VERSION ""

NS_ :

BS_:

BU_: EBOOST_HS CGM_HS BSM_HS HCP_B_HS AVM_HS PFAF_HS LVMPC_HS DCDC_HS TRCM_HS AMP_HS VICM2_HS FICM_HS ARS_HS MCP_B_HS MCP_A_HS ICCM_OBD_HS SAS_HS ACCM_HS VLBS_HS EBCM_OBD_HS HCP_T_HS EDI_HS HPCC_HS VITM_OBD_HS VICM_HS HCP_HS APPS_HS ICCM_HS EOCM_F_HS GPCM_HS VCM_HS HMIM_HS VES_HS Dummy_HS MCP_C_HS ONSTAR_HS EPS_HS TestTool_HS MCP_HS BCP_HS ALC_HS AHL_AFL_HS SADS_HS EPB_HS FCM_HS TCCM_HS RDCM_HS PTO_HS EBCM_HS ACC_HS BCM_HS TCM_HS ECM_HS

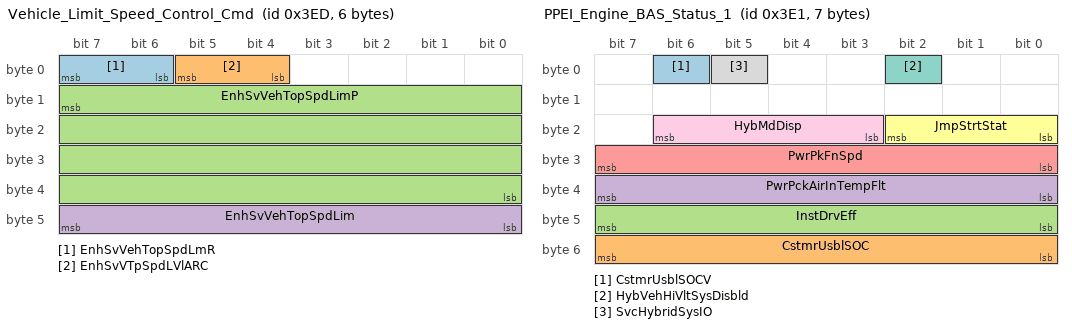
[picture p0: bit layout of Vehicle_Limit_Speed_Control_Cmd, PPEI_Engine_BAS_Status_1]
BO_ 1005 Vehicle_Limit_Speed_Control_Cmd: 6 ONSTAR_HS
 SG_ EnhSvVehTopSpdLmR : 7|2@0+ (1,0) [0|3] ""  ECM_HS
 SG_ EnhSvVTpSpdLVlARC : 5|2@0+ (1,0) [0|3] ""  ECM_HS
 SG_ EnhSvVehTopSpdLimP : 15|32@0+ (1,0) [0|4294967295] ""  ECM_HS
 SG_ EnhSvVehTopSpdLim : 47|8@0+ (2,0) [0|510] "km / h"  ECM_HS

BO_ 688 Starter_Generator_Status_3: 5 BCP_HS
 SG_ StrtrGenSpdV : 39|1@0+ (1,0) [0|1] ""  ECM_HS,EBCM_OBD_HS,EBCM_HS
 SG_ StrtrGenSpd : 21|14@0+ (1,0) [0|16383] "rpm"  ECM_HS,EBCM_OBD_HS,EBCM_HS

BO_ 993 PPEI_Engine_BAS_Status_1: 7 BCP_HS
 SG_ CstmrUsblSOCV : 6|1@0+ (1,0) [0|1] ""  CGM_HS,BCM_HS
 SG_ CstmrUsblSOC : 55|8@0+ (0.39216,0) [0|100.0008] "%"  CGM_HS,BCM_HS
 SG_ InstDrvEff : 47|8@0- (0.78125,0) [-100|99.21875] "%"  CGM_HS,BCM_HS
 SG_ PwrPckAirInTempFlt : 39|8@0+ (1,-40) [-40|215] "deg C"  CGM_HS,BCM_HS
 SG_ PwrPkFnSpd : 31|8@0+ (0.392157,0) [0|100.000035] "%"  CGM_HS,BCM_HS
 SG_ JmpStrtStat : 18|3@0+ (1,0) [0|7] ""  CGM_HS,BCM_HS
 SG_ HybVehHiVltSysDisbld : 2|1@0+ (1,0) [0|1] ""  CGM_HS,ONSTAR_HS
 SG_ SvcHybridSysIO : 5|1@0+ (1,0) [0|1] ""  CGM_HS,BCM_HS
 SG_ HybMdDisp : 22|4@0+ (1,0) [0|15] ""  CGM_HS,BCM_HS

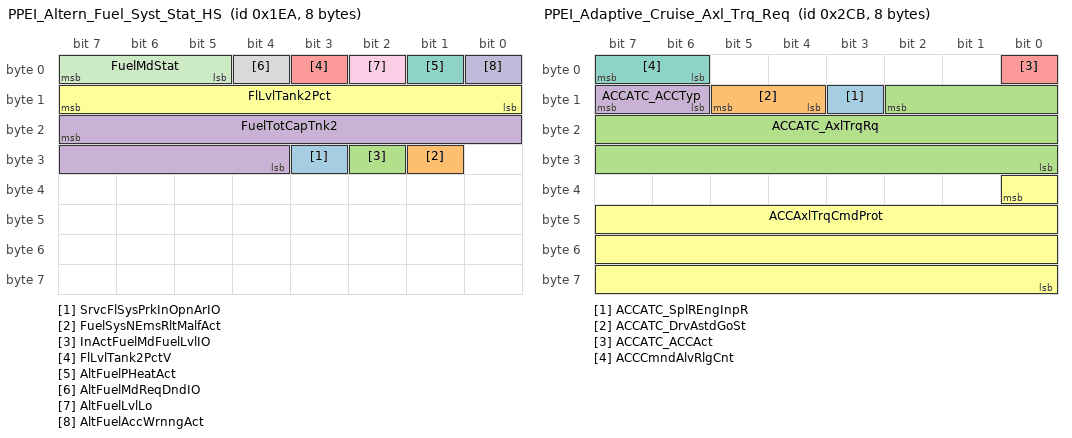
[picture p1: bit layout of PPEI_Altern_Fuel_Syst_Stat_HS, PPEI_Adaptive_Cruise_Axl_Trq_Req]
BO_ 490 PPEI_Altern_Fuel_Syst_Stat_HS: 8 ECM_HS
 SG_ SrvcFlSysPrkInOpnArIO : 27|1@0+ (1,0) [0|1] ""  BCM_HS
 SG_ FuelSysNEmsRltMalfAct : 25|1@0+ (1,0) [0|1] ""  BCM_HS
 SG_ InActFuelMdFuelLvlIO : 26|1@0+ (1,0) [0|1] ""  BCM_HS
 SG_ FuelTotCapTnk2 : 23|12@0+ (0.125,0) [0|511.875] "liters"  BCM_HS
 SG_ FlLvlTank2PctV : 3|1@0+ (1,0) [0|1] ""  BCM_HS
 SG_ FlLvlTank2Pct : 15|8@0+ (0.392157,0) [0|100.000035] "%"  BCM_HS
 SG_ AltFuelPHeatAct : 1|1@0+ (1,0) [0|1] ""  ECM_HS,BCM_HS
 SG_ AltFuelMdReqDndIO : 4|1@0+ (1,0) [0|1] ""  BCM_HS
 SG_ AltFuelLvlLo : 2|1@0+ (1,0) [0|1] ""  BCM_HS,ECM_HS
 SG_ AltFuelAccWrnngAct : 0|1@0+ (1,0) [0|1] ""  BCM_HS
 SG_ FuelMdStat : 7|3@0+ (1,0) [0|7] ""  BCM_HS,ECM_HS

BO_ 431 PTEI_Trans_General_Status_2: 8 TCM_HS
 SG_ TrnsInpCltchStatV : 39|1@0+ (1,0) [0|1] ""  ECM_HS
 SG_ TransCrnkPermsnStatV : 23|1@0+ (1,0) [0|1] ""  ECM_HS
 SG_ TransVehTopSpdLim : 63|8@0+ (2,0) [0|510] "km / h"  ECM_HS
 SG_ TransMinVoltReq : 55|8@0+ (0.07843,0) [0|19.99965] "volts"  ECM_HS
 SG_ TDslPrtFltrIdlRgtnMdAtv : 6|1@0+ (1,0) [0|1] ""  ECM_HS
 SG_ DrvlneTrqStabStat : 38|3@0+ (1,0) [0|7] ""  ECM_HS
 SG_ TrnsTrqCnvCltCmdMdF : 19|1@0+ (1,0) [0|1] ""  ECM_HS
 SG_ AutoTransGrSftDirectFl : 16|1@0+ (1,0) [0|1] ""  ECM_HS
 SG_ AutoTransGrSftDirect : 18|2@0+ (1,0) [0|3] ""  ECM_HS
 SG_ TrnsTrqCnvCltCmndMd : 22|3@0+ (1,0) [0|7] ""  ECM_HS
 SG_ TrnsTrqCnvCltDsrSlp : 35|12@0- (1,0) [-2048|2047] "rpm"  ECM_HS
 SG_ TrnsStWntrMdOvrd : 25|2@0+ (1,0) [0|3] ""  ECM_HS
 SG_ TrnsStTwHaulMdOvrd : 27|2@0+ (1,0) [0|3] ""  ECM_HS
 SG_ TrnsStSprtMdOvrd : 29|2@0+ (1,0) [0|3] ""  ECM_HS
 SG_ TrnsStEconMdOvrd : 31|2@0+ (1,0) [0|3] ""  ECM_HS
 SG_ TrnsInpCltchStat : 2|3@0+ (1,0) [0|7] ""  ECM_HS
 SG_ TrnsAntcptdCrpTrqRRnV : 7|1@0+ (1,0) [0|1] ""  ECM_HS
 SG_ TrnsAntcptdCrpTrqRRn : 15|8@0+ (0.5,0) [0|127.5] "Nm"  ECM_HS
 SG_ TrnCltAdpAtv : 3|1@0+ (1,0) [0|1] ""  ECM_HS
 SG_ TransCrnkPermsnStat : 5|1@0+ (1,0) [0|1] ""  ECM_HS
 SG_ WrmUpShftPtrn : 4|1@0+ (1,0) [0|1] ""  ECM_HS

BO_ 715 PPEI_Adaptive_Cruise_Axl_Trq_Req: 8 ACC_HS
 SG_ ACCATC_SplREngInpR : 11|1@0+ (1,0) [0|1] ""  ECM_HS
 SG_ ACCATC_DrvAstdGoSt : 13|2@0+ (1,0) [0|3] ""  ECM_HS
 SG_ ACCATC_AxlTrqRq : 10|19@0+ (0.125,-22534) [-22534|43001.875] "Nm"  ECM_HS
 SG_ ACCATC_ACCTyp : 15|2@0+ (1,0) [0|3] ""  ECM_HS
 SG_ ACCATC_ACCAct : 0|1@0+ (1,0) [0|1] ""  ECM_HS
 SG_ ACCAxlTrqCmdProt : 32|25@0+ (1,0) [0|33554431] ""  ECM_HS
 SG_ ACCCmndAlvRlgCnt : 7|2@0+ (1,0) [0|3] ""  ECM_HS

BO_ 1267 PPEI_Powertrain_Config_Data_2: 1 ECM_HS
 SG_ VehMassNom : 7|8@0+ (20,500) [500|5600] "kg"  CGM_HS,EOCM_F_HS,ACC_HS,FCM_HS

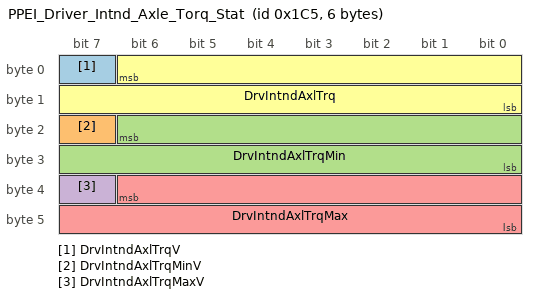
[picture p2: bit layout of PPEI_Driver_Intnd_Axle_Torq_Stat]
BO_ 453 PPEI_Driver_Intnd_Axle_Torq_Stat: 6 ECM_HS
 SG_ DrvIntndAxlTrqV : 7|1@0+ (1,0) [0|1] ""  CGM_HS,FCM_HS,ICCM_OBD_HS,ICCM_HS,EBCM_OBD_HS,EBCM_HS,BSM_HS,VICM_HS,EOCM_F_HS,ACC_HS
 SG_ DrvIntndAxlTrqMinV : 23|1@0+ (1,0) [0|1] ""  CGM_HS,FCM_HS,EOCM_F_HS,ACC_HS
 SG_ DrvIntndAxlTrqMin : 22|15@0+ (2,-22534) [-22534|43000] "Nm"  CGM_HS,FCM_HS,HCP_B_HS,EOCM_F_HS,ACC_HS
 SG_ DrvIntndAxlTrqMaxV : 39|1@0+ (1,0) [0|1] ""  CGM_HS,FCM_HS,EOCM_F_HS,ACC_HS
 SG_ DrvIntndAxlTrqMax : 38|15@0+ (2,-22534) [-22534|43000] "Nm"  CGM_HS,FCM_HS,EOCM_F_HS,ACC_HS
 SG_ DrvIntndAxlTrq : 6|15@0+ (2,-22534) [-22534|43000] "Nm"  CGM_HS,FCM_HS,ICCM_OBD_HS,ICCM_HS,EBCM_OBD_HS,EBCM_HS,BSM_HS,VICM_HS,EOCM_F_HS,ACC_HS

BO_ 452 PPEI_Torque_Request_Status: 8 ECM_HS
 SG_ FSpRgACCSwADdPVal : 50|2@0+ (1,0) [0|3] ""  CGM_HS,EBCM_OBD_HS,EBCM_HS
 SG_ FSpRgACCSwADdARC : 6|2@0+ (1,0) [0|3] ""  CGM_HS,EBCM_OBD_HS,EBCM_HS
 SG_ FSpRgACCSwADd : 7|1@0+ (1,0) [0|1] ""  CGM_HS,EBCM_OBD_HS,EBCM_HS,ACC_HS
 SG_ AutBrkAccActPsStRC : 34|2@0+ (1,0) [0|3] ""  CGM_HS,FCM_HS,EPB_HS,EOCM_F_HS,ACC_HS,EBCM_OBD_HS,EBCM_HS
 SG_ AutBrkAccActPsStPVal : 48|9@0+ (1,0) [0|511] ""  CGM_HS,FCM_HS,EPB_HS,EOCM_F_HS,ACC_HS,EBCM_OBD_HS,EBCM_HS
 SG_ ABAAPS_AccPos : 47|8@0+ (0.392157,0) [0|100.000035] "%"  CGM_HS,FCM_HS,EPB_HS,EBCM_OBD_HS,EBCM_HS,ACC_HS,EOCM_F_HS
 SG_ ABAAPS_AccPosV : 32|1@0+ (1,0) [0|1] ""  CGM_HS,FCM_HS,EPB_HS,EBCM_OBD_HS,EBCM_HS,ACC_HS,EOCM_F_HS
 SG_ ACCATCS_LmtgStat : 12|2@0+ (1,0) [0|3] ""  HCP_B_HS,CGM_HS,EOCM_F_HS,ACC_HS
 SG_ ACCATCS_RqStat : 15|3@0+ (1,0) [0|7] ""  HCP_B_HS,CGM_HS,EOCM_F_HS,ACC_HS
 SG_ RdLdNomAxlTrq : 10|19@0+ (0.125,-22534) [-22534|43001.875] "Nm"  CGM_HS,EOCM_F_HS,ACC_HS
 SG_ AccPdlOvrrdAtvProtVal : 1|2@0+ (1,0) [0|3] ""  CGM_HS,FCM_HS,EOCM_F_HS,EBCM_OBD_HS,EBCM_HS,ACC_HS,PTO_HS
 SG_ AccPdlOvrrdAtvARC : 3|2@0+ (1,0) [0|3] ""  CGM_HS,FCM_HS,EOCM_F_HS,EBCM_OBD_HS,EBCM_HS,ACC_HS,PTO_HS
 SG_ AccPdlOvrrdAtv : 4|1@0+ (1,0) [0|1] ""  CGM_HS,FCM_HS,BCM_HS,EOCM_F_HS,EBCM_OBD_HS,EBCM_HS,ACC_HS,PTO_HS
 SG_ CPSATCS_ReqStatus : 37|3@0+ (1,0) [0|7] ""  CGM_HS,FCM_HS,ACC_HS,EOCM_F_HS
 SG_ CPSATCS_LmtngStatus : 39|2@0+ (1,0) [0|3] ""  CGM_HS,FCM_HS,ACC_HS,EOCM_F_HS
 SG_ RVBATCS_ReqStat : 53|3@0+ (1,0) [0|7] ""  CGM_HS,EOCM_F_HS
 SG_ RVBATCS_LmtngStat : 55|2@0+ (1,0) [0|3] ""  CGM_HS,EOCM_F_HS

BO_ 1905 DTC_Triggered_771: 7 EBOOST_HS
 SG_ DTCI_DTCFaultType_771 : 55|8@0+ (1,0) [0|255] ""  HMIM_HS,ONSTAR_HS
 SG_ DTCI_CodeSupported_771 : 40|1@0+ (1,0) [0|1] ""  HMIM_HS,ONSTAR_HS
 SG_ DTCI_CurrentStatus_771 : 41|1@0+ (1,0) [0|1] ""  HMIM_HS,ONSTAR_HS
 SG_ DTCI_TstNPsdCdClrdSt_771 : 42|1@0+ (1,0) [0|1] ""  HMIM_HS,ONSTAR_HS
 SG_ DTCI_TstFldCdClrdStat_771 : 43|1@0+ (1,0) [0|1] ""  HMIM_HS,ONSTAR_HS
 SG_ DTCI_HistStat_771 : 44|1@0+ (1,0) [0|1] ""  HMIM_HS,ONSTAR_HS
 SG_ DTCI_TstNPsdPwrUpSt_771 : 45|1@0+ (1,0) [0|1] ""  HMIM_HS,ONSTAR_HS
 SG_ DTCI_TstFldPwrUpSt_771 : 46|1@0+ (1,0) [0|1] ""  HMIM_HS,ONSTAR_HS
 SG_ DTCI_WrnIndRqdSt_771 : 47|1@0+ (1,0) [0|1] ""  HMIM_HS,ONSTAR_HS
 SG_ DTCI_DTCFailType_771 : 39|8@0+ (1,0) [0|255] ""  HMIM_HS,ONSTAR_HS
 SG_ DTCI_DTCNumber_771 : 23|16@0+ (1,0) [0|65535] ""  HMIM_HS,ONSTAR_HS
 SG_ DTCI_DTCSource_771 : 15|8@0+ (1,0) [0|255] ""  HMIM_HS,ONSTAR_HS
 SG_ DTCI_DTCTriggered_771 : 0|1@0+ (1,0) [0|1] ""  HMIM_HS,ONSTAR_HS
 SG_ DTCIUnused7_771 : 1|1@0+ (1,0) [0|1] ""  HMIM_HS,ONSTAR_HS
 SG_ DTCIUnused6_771 : 2|1@0+ (1,0) [0|1] ""  HMIM_HS,ONSTAR_HS
 SG_ DTCIUnused5_771 : 3|1@0+ (1,0) [0|1] ""  HMIM_HS,ONSTAR_HS
 SG_ DTCIUnused4_771 : 4|1@0+ (1,0) [0|1] ""  HMIM_HS,ONSTAR_HS
 SG_ DTCIUnused3_771 : 5|1@0+ (1,0) [0|1] ""  HMIM_HS,ONSTAR_HS
 SG_ DTCIUnused2_771 : 6|1@0+ (1,0) [0|1] ""  HMIM_HS,ONSTAR_HS
 SG_ DTCIUnused1_771 : 7|1@0+ (1,0) [0|1] ""  HMIM_HS,ONSTAR_HS

BO_ 1935 DTC_Triggered_78F: 7 Dummy_HS
 SG_ DTCI_DTCSource_78F : 15|8@0+ (1,0) [0|255] ""  HMIM_HS,ONSTAR_HS
 SG_ DTCI_DTCTriggered_78F : 0|1@0+ (1,0) [0|1] ""  HMIM_HS,ONSTAR_HS
 SG_ DTCIUnused1_78F : 7|1@0+ (1,0) [0|1] ""  HMIM_HS,ONSTAR_HS
 SG_ DTCIUnused2_78F : 6|1@0+ (1,0) [0|1] ""  HMIM_HS,ONSTAR_HS
 SG_ DTCIUnused3_78F : 5|1@0+ (1,0) [0|1] ""  HMIM_HS,ONSTAR_HS
 SG_ DTCIUnused4_78F : 4|1@0+ (1,0) [0|1] ""  HMIM_HS,ONSTAR_HS
 SG_ DTCIUnused5_78F : 3|1@0+ (1,0) [0|1] ""  HMIM_HS,ONSTAR_HS
 SG_ DTCIUnused6_78F : 2|1@0+ (1,0) [0|1] ""  HMIM_HS,ONSTAR_HS
 SG_ DTCIUnused7_78F : 1|1@0+ (1,0) [0|1] ""  HMIM_HS,ONSTAR_HS
 SG_ DTCI_CodeSupported_78F : 40|1@0+ (1,0) [0|1] ""  HMIM_HS,ONSTAR_HS
 SG_ DTCI_CurrentStatus_78F : 41|1@0+ (1,0) [0|1] ""  HMIM_HS,ONSTAR_HS
 SG_ DTCI_DTCFaultType_78F : 55|8@0+ (1,0) [0|255] ""  HMIM_HS,ONSTAR_HS
 SG_ DTCI_TstFldCdClrdStat_78F : 43|1@0+ (1,0) [0|1] ""  HMIM_HS,ONSTAR_HS
 SG_ DTCI_TstNPsdCdClrdSt_78F : 42|1@0+ (1,0) [0|1] ""  HMIM_HS,ONSTAR_HS
 SG_ DTCI_HistStat_78F : 44|1@0+ (1,0) [0|1] ""  HMIM_HS,ONSTAR_HS
 SG_ DTCI_TstNPsdPwrUpSt_78F : 45|1@0+ (1,0) [0|1] ""  HMIM_HS,ONSTAR_HS
 SG_ DTCI_TstFldPwrUpSt_78F : 46|1@0+ (1,0) [0|1] ""  HMIM_HS,ONSTAR_HS
 SG_ DTCI_WrnIndRqdSt_78F : 47|1@0+ (1,0) [0|1] ""  HMIM_HS,ONSTAR_HS
 SG_ DTCI_DTCFailType_78F : 39|8@0+ (1,0) [0|255] ""  HMIM_HS,ONSTAR_HS
 SG_ DTCI_DTCNumber_78F : 23|16@0+ (1,0) [0|65535] ""  HMIM_HS,ONSTAR_HS

BO_ 1934 DTC_Triggered_78E: 7 Dummy_HS
 SG_ DTCI_CodeSupported_78E : 40|1@0+ (1,0) [0|1] ""  HMIM_HS,ONSTAR_HS
 SG_ DTCI_CurrentStatus_78E : 41|1@0+ (1,0) [0|1] ""  HMIM_HS,ONSTAR_HS
 SG_ DTCI_DTCFailType_78E : 39|8@0+ (1,0) [0|255] ""  HMIM_HS,ONSTAR_HS
 SG_ DTCI_DTCFaultType_78E : 55|8@0+ (1,0) [0|255] ""  HMIM_HS,ONSTAR_HS
 SG_ DTCI_DTCNumber_78E : 23|16@0+ (1,0) [0|65535] ""  HMIM_HS,ONSTAR_HS
 SG_ DTCI_DTCSource_78E : 15|8@0+ (1,0) [0|255] ""  HMIM_HS,ONSTAR_HS
 SG_ DTCI_DTCTriggered_78E : 0|1@0+ (1,0) [0|1] ""  HMIM_HS,ONSTAR_HS
 SG_ DTCI_HistStat_78E : 44|1@0+ (1,0) [0|1] ""  HMIM_HS,ONSTAR_HS
 SG_ DTCI_TstFldCdClrdStat_78E : 43|1@0+ (1,0) [0|1] ""  HMIM_HS,ONSTAR_HS
 SG_ DTCI_TstFldPwrUpSt_78E : 46|1@0+ (1,0) [0|1] ""  HMIM_HS,ONSTAR_HS
 SG_ DTCI_TstNPsdCdClrdSt_78E : 42|1@0+ (1,0) [0|1] ""  HMIM_HS,ONSTAR_HS
 SG_ DTCI_TstNPsdPwrUpSt_78E : 45|1@0+ (1,0) [0|1] ""  HMIM_HS,ONSTAR_HS
 SG_ DTCIUnused1_78E : 7|1@0+ (1,0) [0|1] ""  HMIM_HS,ONSTAR_HS
 SG_ DTCIUnused2_78E : 6|1@0+ (1,0) [0|1] ""  HMIM_HS,ONSTAR_HS
 SG_ DTCIUnused3_78E : 5|1@0+ (1,0) [0|1] ""  HMIM_HS,ONSTAR_HS
 SG_ DTCIUnused4_78E : 4|1@0+ (1,0) [0|1] ""  HMIM_HS,ONSTAR_HS
 SG_ DTCIUnused5_78E : 3|1@0+ (1,0) [0|1] ""  HMIM_HS,ONSTAR_HS
 SG_ DTCIUnused6_78E : 2|1@0+ (1,0) [0|1] ""  HMIM_HS,ONSTAR_HS
 SG_ DTCIUnused7_78E : 1|1@0+ (1,0) [0|1] ""  HMIM_HS,ONSTAR_HS
 SG_ DTCI_WrnIndRqdSt_78E : 47|1@0+ (1,0) [0|1] ""  HMIM_HS,ONSTAR_HS

BO_ 1933 DTC_Triggered_78D: 7 Dummy_HS
 SG_ DTCI_CodeSupported_78D : 40|1@0+ (1,0) [0|1] ""  HMIM_HS,ONSTAR_HS
 SG_ DTCI_CurrentStatus_78D : 41|1@0+ (1,0) [0|1] ""  HMIM_HS,ONSTAR_HS
 SG_ DTCI_DTCFailType_78D : 39|8@0+ (1,0) [0|255] ""  HMIM_HS,ONSTAR_HS
 SG_ DTCI_DTCFaultType_78D : 55|8@0+ (1,0) [0|255] ""  HMIM_HS,ONSTAR_HS
 SG_ DTCI_DTCNumber_78D : 23|16@0+ (1,0) [0|65535] ""  HMIM_HS,ONSTAR_HS
 SG_ DTCI_DTCSource_78D : 15|8@0+ (1,0) [0|255] ""  HMIM_HS,ONSTAR_HS
 SG_ DTCI_DTCTriggered_78D : 0|1@0+ (1,0) [0|1] ""  HMIM_HS,ONSTAR_HS
 SG_ DTCI_HistStat_78D : 44|1@0+ (1,0) [0|1] ""  HMIM_HS,ONSTAR_HS
 SG_ DTCI_TstFldCdClrdStat_78D : 43|1@0+ (1,0) [0|1] ""  HMIM_HS,ONSTAR_HS
 SG_ DTCI_TstFldPwrUpSt_78D : 46|1@0+ (1,0) [0|1] ""  HMIM_HS,ONSTAR_HS
 SG_ DTCI_TstNPsdCdClrdSt_78D : 42|1@0+ (1,0) [0|1] ""  HMIM_HS,ONSTAR_HS
 SG_ DTCI_TstNPsdPwrUpSt_78D : 45|1@0+ (1,0) [0|1] ""  HMIM_HS,ONSTAR_HS
 SG_ DTCIUnused1_78D : 7|1@0+ (1,0) [0|1] ""  HMIM_HS,ONSTAR_HS
 SG_ DTCIUnused2_78D : 6|1@0+ (1,0) [0|1] ""  HMIM_HS,ONSTAR_HS
 SG_ DTCIUnused3_78D : 5|1@0+ (1,0) [0|1] ""  HMIM_HS,ONSTAR_HS
 SG_ DTCIUnused4_78D : 4|1@0+ (1,0) [0|1] ""  HMIM_HS,ONSTAR_HS
 SG_ DTCIUnused5_78D : 3|1@0+ (1,0) [0|1] ""  HMIM_HS,ONSTAR_HS
 SG_ DTCIUnused6_78D : 2|1@0+ (1,0) [0|1] ""  HMIM_HS,ONSTAR_HS
 SG_ DTCIUnused7_78D : 1|1@0+ (1,0) [0|1] ""  HMIM_HS,ONSTAR_HS
 SG_ DTCI_WrnIndRqdSt_78D : 47|1@0+ (1,0) [0|1] ""  HMIM_HS,ONSTAR_HS

BO_ 1932 DTC_Triggered_78C: 7 Dummy_HS
 SG_ DTCI_CodeSupported_78C : 40|1@0+ (1,0) [0|1] ""  HMIM_HS,ONSTAR_HS
 SG_ DTCI_CurrentStatus_78C : 41|1@0+ (1,0) [0|1] ""  HMIM_HS,ONSTAR_HS
 SG_ DTCI_DTCFailType_78C : 39|8@0+ (1,0) [0|255] ""  HMIM_HS,ONSTAR_HS
 SG_ DTCI_DTCFaultType_78C : 55|8@0+ (1,0) [0|255] ""  HMIM_HS,ONSTAR_HS
 SG_ DTCI_DTCNumber_78C : 23|16@0+ (1,0) [0|65535] ""  HMIM_HS,ONSTAR_HS
 SG_ DTCI_DTCSource_78C : 15|8@0+ (1,0) [0|255] ""  HMIM_HS,ONSTAR_HS
 SG_ DTCI_DTCTriggered_78C : 0|1@0+ (1,0) [0|1] ""  HMIM_HS,ONSTAR_HS
 SG_ DTCI_HistStat_78C : 44|1@0+ (1,0) [0|1] ""  HMIM_HS,ONSTAR_HS
 SG_ DTCI_TstFldCdClrdStat_78C : 43|1@0+ (1,0) [0|1] ""  HMIM_HS,ONSTAR_HS
 SG_ DTCI_TstFldPwrUpSt_78C : 45|1@0+ (1,0) [0|1] ""  HMIM_HS,ONSTAR_HS
 SG_ DTCI_TstNPsdCdClrdSt_78C : 42|1@0+ (1,0) [0|1] ""  HMIM_HS,ONSTAR_HS
 SG_ DTCI_TstNPsdPwrUpSt_78C : 46|1@0+ (1,0) [0|1] ""  HMIM_HS,ONSTAR_HS
 SG_ DTCIUnused1_78C : 7|1@0+ (1,0) [0|1] ""  HMIM_HS,ONSTAR_HS
 SG_ DTCIUnused2_78C : 6|1@0+ (1,0) [0|1] ""  HMIM_HS,ONSTAR_HS
 SG_ DTCIUnused3_78C : 5|1@0+ (1,0) [0|1] ""  HMIM_HS,ONSTAR_HS
 SG_ DTCIUnused4_78C : 4|1@0+ (1,0) [0|1] ""  HMIM_HS,ONSTAR_HS
 SG_ DTCIUnused5_78C : 3|1@0+ (1,0) [0|1] ""  HMIM_HS,ONSTAR_HS
 SG_ DTCIUnused6_78C : 2|1@0+ (1,0) [0|1] ""  HMIM_HS,ONSTAR_HS
 SG_ DTCIUnused7_78C : 1|1@0+ (1,0) [0|1] ""  HMIM_HS,ONSTAR_HS
 SG_ DTCI_WrnIndRqdSt_78C : 47|1@0+ (1,0) [0|1] ""  HMIM_HS,ONSTAR_HS

BO_ 1931 DTC_Triggered_78B: 7 Dummy_HS
 SG_ DTCI_CodeSupported_78B : 40|1@0+ (1,0) [0|1] ""  HMIM_HS,ONSTAR_HS
 SG_ DTCI_CurrentStatus_78B : 41|1@0+ (1,0) [0|1] ""  HMIM_HS,ONSTAR_HS
 SG_ DTCI_DTCFailType_78B : 39|8@0+ (1,0) [0|255] ""  HMIM_HS,ONSTAR_HS
 SG_ DTCI_DTCFaultType_78B : 55|8@0+ (1,0) [0|255] ""  HMIM_HS,ONSTAR_HS
 SG_ DTCI_DTCNumber_78B : 23|16@0+ (1,0) [0|65535] ""  HMIM_HS,ONSTAR_HS
 SG_ DTCI_DTCSource_78B : 15|8@0+ (1,0) [0|255] ""  HMIM_HS,ONSTAR_HS
 SG_ DTCI_DTCTriggered_78B : 0|1@0+ (1,0) [0|1] ""  HMIM_HS,ONSTAR_HS
 SG_ DTCI_HistStat_78B : 44|1@0+ (1,0) [0|1] ""  HMIM_HS,ONSTAR_HS
 SG_ DTCI_TstFldCdClrdStat_78B : 43|1@0+ (1,0) [0|1] ""  HMIM_HS,ONSTAR_HS
 SG_ DTCI_TstFldPwrUpSt_78B : 46|1@0+ (1,0) [0|1] ""  HMIM_HS,ONSTAR_HS
 SG_ DTCI_TstNPsdCdClrdSt_78B : 42|1@0+ (1,0) [0|1] ""  HMIM_HS,ONSTAR_HS
 SG_ DTCI_TstNPsdPwrUpSt_78B : 45|1@0+ (1,0) [0|1] ""  HMIM_HS,ONSTAR_HS
 SG_ DTCIUnused1_78B : 7|1@0+ (1,0) [0|1] ""  HMIM_HS,ONSTAR_HS
 SG_ DTCIUnused2_78B : 6|1@0+ (1,0) [0|1] ""  HMIM_HS,ONSTAR_HS
 SG_ DTCIUnused3_78B : 5|1@0+ (1,0) [0|1] ""  HMIM_HS,ONSTAR_HS
 SG_ DTCIUnused4_78B : 4|1@0+ (1,0) [0|1] ""  HMIM_HS,ONSTAR_HS
 SG_ DTCIUnused5_78B : 3|1@0+ (1,0) [0|1] ""  HMIM_HS,ONSTAR_HS
 SG_ DTCIUnused6_78B : 2|1@0+ (1,0) [0|1] ""  HMIM_HS,ONSTAR_HS
 SG_ DTCIUnused7_78B : 1|1@0+ (1,0) [0|1] ""  HMIM_HS,ONSTAR_HS
 SG_ DTCI_WrnIndRqdSt_78B : 47|1@0+ (1,0) [0|1] ""  HMIM_HS,ONSTAR_HS

BO_ 1930 DTC_Triggered_78A: 7 FCM_HS
 SG_ DTCI_CodeSupported_78A : 40|1@0+ (1,0) [0|1] ""  HMIM_HS,ONSTAR_HS
 SG_ DTCI_CurrentStatus_78A : 41|1@0+ (1,0) [0|1] ""  HMIM_HS,ONSTAR_HS
 SG_ DTCI_DTCFailType_78A : 39|8@0+ (1,0) [0|255] ""  HMIM_HS,ONSTAR_HS
 SG_ DTCI_DTCFaultType_78A : 55|8@0+ (1,0) [0|255] ""  HMIM_HS,ONSTAR_HS
 SG_ DTCI_DTCNumber_78A : 23|16@0+ (1,0) [0|65535] ""  HMIM_HS,ONSTAR_HS
 SG_ DTCI_DTCSource_78A : 15|8@0+ (1,0) [0|255] ""  HMIM_HS,ONSTAR_HS
 SG_ DTCI_DTCTriggered_78A : 0|1@0+ (1,0) [0|1] ""  HMIM_HS,ONSTAR_HS
 SG_ DTCI_HistStat_78A : 44|1@0+ (1,0) [0|1] ""  HMIM_HS,ONSTAR_HS
 SG_ DTCI_TstFldCdClrdStat_78A : 43|1@0+ (1,0) [0|1] ""  HMIM_HS,ONSTAR_HS
 SG_ DTCI_TstFldPwrUpSt_78A : 46|1@0+ (1,0) [0|1] ""  HMIM_HS,ONSTAR_HS
 SG_ DTCI_TstNPsdCdClrdSt_78A : 42|1@0+ (1,0) [0|1] ""  HMIM_HS,ONSTAR_HS
 SG_ DTCI_TstNPsdPwrUpSt_78A : 45|1@0+ (1,0) [0|1] ""  HMIM_HS,ONSTAR_HS
 SG_ DTCIUnused1_78A : 7|1@0+ (1,0) [0|1] ""  HMIM_HS,ONSTAR_HS
 SG_ DTCIUnused2_78A : 6|1@0+ (1,0) [0|1] ""  HMIM_HS,ONSTAR_HS
 SG_ DTCIUnused3_78A : 5|1@0+ (1,0) [0|1] ""  HMIM_HS,ONSTAR_HS
 SG_ DTCIUnused4_78A : 4|1@0+ (1,0) [0|1] ""  HMIM_HS,ONSTAR_HS
 SG_ DTCIUnused5_78A : 3|1@0+ (1,0) [0|1] ""  HMIM_HS,ONSTAR_HS
 SG_ DTCIUnused6_78A : 2|1@0+ (1,0) [0|1] ""  HMIM_HS,ONSTAR_HS
 SG_ DTCIUnused7_78A : 1|1@0+ (1,0) [0|1] ""  HMIM_HS,ONSTAR_HS
 SG_ DTCI_WrnIndRqdSt_78A : 47|1@0+ (1,0) [0|1] ""  HMIM_HS,ONSTAR_HS

BO_ 1929 DTC_Triggered_789: 7 ARS_HS
 SG_ DTCI_CodeSupported_789 : 40|1@0+ (1,0) [0|1] ""  HMIM_HS,ONSTAR_HS
 SG_ DTCI_CurrentStatus_789 : 41|1@0+ (1,0) [0|1] ""  HMIM_HS,ONSTAR_HS
 SG_ DTCI_DTCFailType_789 : 39|8@0+ (1,0) [0|255] ""  HMIM_HS,ONSTAR_HS
 SG_ DTCI_DTCFaultType_789 : 55|8@0+ (1,0) [0|255] ""  HMIM_HS,ONSTAR_HS
 SG_ DTCI_DTCNumber_789 : 23|16@0+ (1,0) [0|65535] ""  HMIM_HS,ONSTAR_HS
 SG_ DTCI_DTCSource_789 : 15|8@0+ (1,0) [0|255] ""  HMIM_HS,ONSTAR_HS
 SG_ DTCI_DTCTriggered_789 : 0|1@0+ (1,0) [0|1] ""  HMIM_HS,ONSTAR_HS
 SG_ DTCI_HistStat_789 : 44|1@0+ (1,0) [0|1] ""  HMIM_HS,ONSTAR_HS
 SG_ DTCI_TstFldCdClrdStat_789 : 43|1@0+ (1,0) [0|1] ""  HMIM_HS,ONSTAR_HS
 SG_ DTCI_TstFldPwrUpSt_789 : 46|1@0+ (1,0) [0|1] ""  HMIM_HS,ONSTAR_HS
 SG_ DTCI_TstNPsdCdClrdSt_789 : 42|1@0+ (1,0) [0|1] ""  HMIM_HS,ONSTAR_HS
 SG_ DTCI_TstNPsdPwrUpSt_789 : 45|1@0+ (1,0) [0|1] ""  HMIM_HS,ONSTAR_HS
 SG_ DTCIUnused1_789 : 7|1@0+ (1,0) [0|1] ""  HMIM_HS,ONSTAR_HS
 SG_ DTCIUnused2_789 : 6|1@0+ (1,0) [0|1] ""  HMIM_HS,ONSTAR_HS
 SG_ DTCIUnused3_789 : 5|1@0+ (1,0) [0|1] ""  HMIM_HS,ONSTAR_HS
 SG_ DTCIUnused4_789 : 4|1@0+ (1,0) [0|1] ""  HMIM_HS,ONSTAR_HS
 SG_ DTCIUnused5_789 : 3|1@0+ (1,0) [0|1] ""  HMIM_HS,ONSTAR_HS
 SG_ DTCIUnused6_789 : 2|1@0+ (1,0) [0|1] ""  HMIM_HS,ONSTAR_HS
 SG_ DTCIUnused7_789 : 1|1@0+ (1,0) [0|1] ""  HMIM_HS,ONSTAR_HS
 SG_ DTCI_WrnIndRqdSt_789 : 47|1@0+ (1,0) [0|1] ""  HMIM_HS,ONSTAR_HS

BO_ 1928 DTC_Triggered_788: 7 HMIM_HS
 SG_ DTCI_CodeSupported_788 : 40|1@0+ (1,0) [0|1] ""  HMIM_HS,ONSTAR_HS
 SG_ DTCI_CurrentStatus_788 : 41|1@0+ (1,0) [0|1] ""  HMIM_HS,ONSTAR_HS
 SG_ DTCI_DTCFailType_788 : 39|8@0+ (1,0) [0|255] ""  HMIM_HS,ONSTAR_HS
 SG_ DTCI_DTCFaultType_788 : 55|8@0+ (1,0) [0|255] ""  HMIM_HS,ONSTAR_HS
 SG_ DTCI_DTCNumber_788 : 23|16@0+ (1,0) [0|65535] ""  HMIM_HS,ONSTAR_HS
 SG_ DTCI_DTCSource_788 : 15|8@0+ (1,0) [0|255] ""  HMIM_HS,ONSTAR_HS
 SG_ DTCI_DTCTriggered_788 : 0|1@0+ (1,0) [0|1] ""  HMIM_HS,ONSTAR_HS
 SG_ DTCI_HistStat_788 : 44|1@0+ (1,0) [0|1] ""  HMIM_HS,ONSTAR_HS
 SG_ DTCI_TstFldCdClrdStat_788 : 42|1@0+ (1,0) [0|1] ""  HMIM_HS,ONSTAR_HS
 SG_ DTCI_TstFldPwrUpSt_788 : 46|1@0+ (1,0) [0|1] ""  HMIM_HS,ONSTAR_HS
 SG_ DTCI_TstNPsdCdClrdSt_788 : 43|1@0+ (1,0) [0|1] ""  HMIM_HS,ONSTAR_HS
 SG_ DTCI_TstNPsdPwrUpSt_788 : 45|1@0+ (1,0) [0|1] ""  HMIM_HS,ONSTAR_HS
 SG_ DTCIUnused1_788 : 7|1@0+ (1,0) [0|1] ""  HMIM_HS,ONSTAR_HS
 SG_ DTCIUnused2_788 : 6|1@0+ (1,0) [0|1] ""  HMIM_HS,ONSTAR_HS
 SG_ DTCIUnused3_788 : 5|1@0+ (1,0) [0|1] ""  HMIM_HS,ONSTAR_HS
 SG_ DTCIUnused4_788 : 4|1@0+ (1,0) [0|1] ""  HMIM_HS,ONSTAR_HS
 SG_ DTCIUnused5_788 : 3|1@0+ (1,0) [0|1] ""  HMIM_HS,ONSTAR_HS
 SG_ DTCIUnused6_788 : 2|1@0+ (1,0) [0|1] ""  HMIM_HS,ONSTAR_HS
 SG_ DTCIUnused7_788 : 1|1@0+ (1,0) [0|1] ""  HMIM_HS,ONSTAR_HS
 SG_ DTCI_WrnIndRqdSt_788 : 47|1@0+ (1,0) [0|1] ""  HMIM_HS,ONSTAR_HS

BO_ 1927 DTC_Triggered_787: 7 VICM_HS
 SG_ DTCI_CodeSupported_787 : 40|1@0+ (1,0) [0|1] ""  HMIM_HS,ONSTAR_HS
 SG_ DTCI_CurrentStatus_787 : 41|1@0+ (1,0) [0|1] ""  HMIM_HS,ONSTAR_HS
 SG_ DTCI_DTCFailType_787 : 39|8@0+ (1,0) [0|255] ""  HMIM_HS,ONSTAR_HS
 SG_ DTCI_DTCFaultType_787 : 55|8@0+ (1,0) [0|255] ""  HMIM_HS,ONSTAR_HS
 SG_ DTCI_DTCNumber_787 : 23|16@0+ (1,0) [0|65535] ""  HMIM_HS,ONSTAR_HS
 SG_ DTCI_DTCSource_787 : 15|8@0+ (1,0) [0|255] ""  HMIM_HS,ONSTAR_HS
 SG_ DTCI_DTCTriggered_787 : 0|1@0+ (1,0) [0|1] ""  HMIM_HS,ONSTAR_HS
 SG_ DTCI_HistStat_787 : 44|1@0+ (1,0) [0|1] ""  HMIM_HS,ONSTAR_HS
 SG_ DTCI_TstFldCdClrdStat_787 : 43|1@0+ (1,0) [0|1] ""  HMIM_HS,ONSTAR_HS
 SG_ DTCI_TstFldPwrUpSt_787 : 46|1@0+ (1,0) [0|1] ""  HMIM_HS,ONSTAR_HS
 SG_ DTCI_TstNPsdCdClrdSt_787 : 42|1@0+ (1,0) [0|1] ""  HMIM_HS,ONSTAR_HS
 SG_ DTCI_TstNPsdPwrUpSt_787 : 45|1@0+ (1,0) [0|1] ""  HMIM_HS,ONSTAR_HS
 SG_ DTCIUnused1_787 : 7|1@0+ (1,0) [0|1] ""  HMIM_HS,ONSTAR_HS
 SG_ DTCIUnused2_787 : 6|1@0+ (1,0) [0|1] ""  HMIM_HS,ONSTAR_HS
 SG_ DTCIUnused3_787 : 5|1@0+ (1,0) [0|1] ""  HMIM_HS,ONSTAR_HS
 SG_ DTCIUnused4_787 : 4|1@0+ (1,0) [0|1] ""  HMIM_HS,ONSTAR_HS
 SG_ DTCIUnused5_787 : 3|1@0+ (1,0) [0|1] ""  HMIM_HS,ONSTAR_HS
 SG_ DTCIUnused6_787 : 2|1@0+ (1,0) [0|1] ""  HMIM_HS,ONSTAR_HS
 SG_ DTCIUnused7_787 : 1|1@0+ (1,0) [0|1] ""  HMIM_HS,ONSTAR_HS
 SG_ DTCI_WrnIndRqdSt_787 : 47|1@0+ (1,0) [0|1] ""  HMIM_HS,ONSTAR_HS

BO_ 1926 DTC_Triggered_786: 7 MCP_B_HS
 SG_ DTCI_CodeSupported_786 : 40|1@0+ (1,0) [0|1] ""  HMIM_HS,ONSTAR_HS
 SG_ DTCI_CurrentStatus_786 : 41|1@0+ (1,0) [0|1] ""  HMIM_HS,ONSTAR_HS
 SG_ DTCI_DTCFailType_786 : 39|8@0+ (1,0) [0|255] ""  HMIM_HS,ONSTAR_HS
 SG_ DTCI_DTCFaultType_786 : 55|8@0+ (1,0) [0|255] ""  HMIM_HS,ONSTAR_HS
 SG_ DTCI_DTCNumber_786 : 23|16@0+ (1,0) [0|65535] ""  HMIM_HS,ONSTAR_HS
 SG_ DTCI_DTCSource_786 : 15|8@0+ (1,0) [0|255] ""  HMIM_HS,ONSTAR_HS
 SG_ DTCI_DTCTriggered_786 : 0|1@0+ (1,0) [0|1] ""  HMIM_HS,ONSTAR_HS
 SG_ DTCI_HistStat_786 : 44|1@0+ (1,0) [0|1] ""  HMIM_HS,ONSTAR_HS
 SG_ DTCI_TstFldCdClrdStat_786 : 43|1@0+ (1,0) [0|1] ""  HMIM_HS,ONSTAR_HS
 SG_ DTCI_TstFldPwrUpSt_786 : 46|1@0+ (1,0) [0|1] ""  HMIM_HS,ONSTAR_HS
 SG_ DTCI_TstNPsdCdClrdSt_786 : 42|1@0+ (1,0) [0|1] ""  HMIM_HS,ONSTAR_HS
 SG_ DTCI_TstNPsdPwrUpSt_786 : 45|1@0+ (1,0) [0|1] ""  HMIM_HS,ONSTAR_HS
 SG_ DTCIUnused1_786 : 7|1@0+ (1,0) [0|1] ""  HMIM_HS,ONSTAR_HS
 SG_ DTCIUnused2_786 : 6|1@0+ (1,0) [0|1] ""  HMIM_HS,ONSTAR_HS
 SG_ DTCIUnused3_786 : 5|1@0+ (1,0) [0|1] ""  HMIM_HS,ONSTAR_HS
 SG_ DTCIUnused4_786 : 4|1@0+ (1,0) [0|1] ""  HMIM_HS,ONSTAR_HS
 SG_ DTCIUnused5_786 : 3|1@0+ (1,0) [0|1] ""  HMIM_HS,ONSTAR_HS
 SG_ DTCIUnused6_786 : 2|1@0+ (1,0) [0|1] ""  HMIM_HS,ONSTAR_HS
 SG_ DTCIUnused7_786 : 1|1@0+ (1,0) [0|1] ""  HMIM_HS,ONSTAR_HS
 SG_ DTCI_WrnIndRqdSt_786 : 47|1@0+ (1,0) [0|1] ""  HMIM_HS,ONSTAR_HS

BO_ 1925 DTC_Triggered_785: 7 ICCM_HS
 SG_ DTCI_CodeSupported_785 : 40|1@0+ (1,0) [0|1] ""  HMIM_HS,ONSTAR_HS
 SG_ DTCI_CurrentStatus_785 : 41|1@0+ (1,0) [0|1] ""  HMIM_HS,ONSTAR_HS
 SG_ DTCI_DTCFailType_785 : 39|8@0+ (1,0) [0|255] ""  HMIM_HS,ONSTAR_HS
 SG_ DTCI_DTCFaultType_785 : 55|8@0+ (1,0) [0|255] ""  HMIM_HS,ONSTAR_HS
 SG_ DTCI_DTCNumber_785 : 23|16@0+ (1,0) [0|65535] ""  HMIM_HS,ONSTAR_HS
 SG_ DTCI_DTCSource_785 : 15|8@0+ (1,0) [0|255] ""  HMIM_HS,ONSTAR_HS
 SG_ DTCI_DTCTriggered_785 : 0|1@0+ (1,0) [0|1] ""  HMIM_HS,ONSTAR_HS
 SG_ DTCI_HistStat_785 : 44|1@0+ (1,0) [0|1] ""  HMIM_HS,ONSTAR_HS
 SG_ DTCI_TstFldCdClrdStat_785 : 43|1@0+ (1,0) [0|1] ""  HMIM_HS,ONSTAR_HS
 SG_ DTCI_TstFldPwrUpSt_785 : 46|1@0+ (1,0) [0|1] ""  HMIM_HS,ONSTAR_HS
 SG_ DTCI_TstNPsdCdClrdSt_785 : 42|1@0+ (1,0) [0|1] ""  HMIM_HS,ONSTAR_HS
 SG_ DTCI_TstNPsdPwrUpSt_785 : 45|1@0+ (1,0) [0|1] ""  HMIM_HS,ONSTAR_HS
 SG_ DTCIUnused1_785 : 7|1@0+ (1,0) [0|1] ""  HMIM_HS,ONSTAR_HS
 SG_ DTCIUnused2_785 : 6|1@0+ (1,0) [0|1] ""  HMIM_HS,ONSTAR_HS
 SG_ DTCIUnused3_785 : 5|1@0+ (1,0) [0|1] ""  HMIM_HS,ONSTAR_HS
 SG_ DTCIUnused4_785 : 4|1@0+ (1,0) [0|1] ""  HMIM_HS,ONSTAR_HS
 SG_ DTCIUnused5_785 : 3|1@0+ (1,0) [0|1] ""  HMIM_HS,ONSTAR_HS
 SG_ DTCIUnused6_785 : 2|1@0+ (1,0) [0|1] ""  HMIM_HS,ONSTAR_HS
 SG_ DTCIUnused7_785 : 1|1@0+ (1,0) [0|1] ""  HMIM_HS,ONSTAR_HS
 SG_ DTCI_WrnIndRqdSt_785 : 47|1@0+ (1,0) [0|1] ""  HMIM_HS,ONSTAR_HS

BO_ 1924 DTC_Triggered_784: 7 AVM_HS
 SG_ DTCI_HistStat_784 : 44|1@0+ (1,0) [0|1] ""  HMIM_HS,ONSTAR_HS
 SG_ DTCI_TstFldCdClrdStat_784 : 43|1@0+ (1,0) [0|1] ""  HMIM_HS,ONSTAR_HS
 SG_ DTCI_TstFldPwrUpSt_784 : 46|1@0+ (1,0) [0|1] ""  HMIM_HS,ONSTAR_HS
 SG_ DTCI_TstNPsdCdClrdSt_784 : 42|1@0+ (1,0) [0|1] ""  HMIM_HS,ONSTAR_HS
 SG_ DTCI_TstNPsdPwrUpSt_784 : 45|1@0+ (1,0) [0|1] ""  HMIM_HS,ONSTAR_HS
 SG_ DTCIUnused1_784 : 7|1@0+ (1,0) [0|1] ""  HMIM_HS,ONSTAR_HS
 SG_ DTCIUnused2_784 : 6|1@0+ (1,0) [0|1] ""  HMIM_HS,ONSTAR_HS
 SG_ DTCIUnused3_784 : 5|1@0+ (1,0) [0|1] ""  HMIM_HS,ONSTAR_HS
 SG_ DTCIUnused4_784 : 4|1@0+ (1,0) [0|1] ""  HMIM_HS,ONSTAR_HS
 SG_ DTCIUnused5_784 : 3|1@0+ (1,0) [0|1] ""  HMIM_HS,ONSTAR_HS
 SG_ DTCIUnused6_784 : 2|1@0+ (1,0) [0|1] ""  HMIM_HS,ONSTAR_HS
 SG_ DTCIUnused7_784 : 1|1@0+ (1,0) [0|1] ""  HMIM_HS,ONSTAR_HS
 SG_ DTCI_WrnIndRqdSt_784 : 47|1@0+ (1,0) [0|1] ""  HMIM_HS,ONSTAR_HS
 SG_ DTCI_CodeSupported_784 : 40|1@0+ (1,0) [0|1] ""  HMIM_HS,ONSTAR_HS
 SG_ DTCI_CurrentStatus_784 : 41|1@0+ (1,0) [0|1] ""  HMIM_HS,ONSTAR_HS
 SG_ DTCI_DTCFailType_784 : 39|8@0+ (1,0) [0|255] ""  HMIM_HS,ONSTAR_HS
 SG_ DTCI_DTCFaultType_784 : 55|8@0+ (1,0) [0|255] ""  HMIM_HS,ONSTAR_HS
 SG_ DTCI_DTCNumber_784 : 23|16@0+ (1,0) [0|65535] ""  HMIM_HS,ONSTAR_HS
 SG_ DTCI_DTCSource_784 : 15|8@0+ (1,0) [0|255] ""  HMIM_HS,ONSTAR_HS
 SG_ DTCI_DTCTriggered_784 : 0|1@0+ (1,0) [0|1] ""  HMIM_HS,ONSTAR_HS

BO_ 1923 DTC_Triggered_783: 7 ALC_HS
 SG_ DTCI_WrnIndRqdSt_783 : 47|1@0+ (1,0) [0|1] ""  HMIM_HS,ONSTAR_HS
 SG_ DTCI_TstNPsdPwrUpSt_783 : 45|1@0+ (1,0) [0|1] ""  HMIM_HS,ONSTAR_HS
 SG_ DTCI_TstNPsdCdClrdSt_783 : 42|1@0+ (1,0) [0|1] ""  HMIM_HS,ONSTAR_HS
 SG_ DTCI_TstFldPwrUpSt_783 : 46|1@0+ (1,0) [0|1] ""  HMIM_HS,ONSTAR_HS
 SG_ DTCI_TstFldCdClrdStat_783 : 43|1@0+ (1,0) [0|1] ""  HMIM_HS,ONSTAR_HS
 SG_ DTCI_HistStat_783 : 44|1@0+ (1,0) [0|1] ""  HMIM_HS,ONSTAR_HS
 SG_ DTCI_DTCTriggered_783 : 0|1@0+ (1,0) [0|1] ""  HMIM_HS,ONSTAR_HS
 SG_ DTCI_DTCSource_783 : 15|8@0+ (1,0) [0|255] ""  HMIM_HS,ONSTAR_HS
 SG_ DTCI_DTCNumber_783 : 23|16@0+ (1,0) [0|65535] ""  HMIM_HS,ONSTAR_HS
 SG_ DTCI_DTCFaultType_783 : 55|8@0+ (1,0) [0|255] ""  HMIM_HS,ONSTAR_HS
 SG_ DTCI_DTCFailType_783 : 39|8@0+ (1,0) [0|255] ""  HMIM_HS,ONSTAR_HS
 SG_ DTCI_CurrentStatus_783 : 41|1@0+ (1,0) [0|1] ""  HMIM_HS,ONSTAR_HS
 SG_ DTCI_CodeSupported_783 : 40|1@0+ (1,0) [0|1] ""  HMIM_HS,ONSTAR_HS
 SG_ DTCIUnused7_783 : 1|1@0+ (1,0) [0|1] ""  HMIM_HS,ONSTAR_HS
 SG_ DTCIUnused6_783 : 2|1@0+ (1,0) [0|1] ""  HMIM_HS,ONSTAR_HS
 SG_ DTCIUnused5_783 : 3|1@0+ (1,0) [0|1] ""  HMIM_HS,ONSTAR_HS
 SG_ DTCIUnused4_783 : 4|1@0+ (1,0) [0|1] ""  HMIM_HS,ONSTAR_HS
 SG_ DTCIUnused3_783 : 5|1@0+ (1,0) [0|1] ""  HMIM_HS,ONSTAR_HS
 SG_ DTCIUnused2_783 : 6|1@0+ (1,0) [0|1] ""  HMIM_HS,ONSTAR_HS
 SG_ DTCIUnused1_783 : 7|1@0+ (1,0) [0|1] ""  HMIM_HS,ONSTAR_HS

BO_ 1363 UUDT_Resp_From_AMP_HS: 8 AMP_HS
 SG_ DgnInf_HS553 : 7|64@0+ (1,0) [0|1.84467440737096E+019] ""  ONSTAR_HS,TestTool_HS

BO_ 607 USDT_Req_to_VLBS_CGM_HS: 8 TestTool_HS
 SG_ DgnInf : 7|64@0+ (1,0) [0|1.84467440737096E+019] ""  CGM_HS,VLBS_HS

BO_ 1630 USDT_Resp_From_VCM_HS: 8 VCM_HS
 SG_ DgnInf : 7|64@0+ (1,0) [0|1.84467440737096E+019] ""  CGM_HS,ONSTAR_HS,TestTool_HS

BO_ 1629 USDT_Resp_From_ARS_HS: 8 ARS_HS
 SG_ DgnInf : 7|64@0+ (1,0) [0|1.84467440737096E+019] ""  CGM_HS,ONSTAR_HS,TestTool_HS

BO_ 606 USDT_Req_to_VCM_HS: 8 TestTool_HS
 SG_ DgnInf : 7|64@0+ (1,0) [0|1.84467440737096E+019] ""  VCM_HS

BO_ 605 USDT_Req_to_ARS_HS: 8 TestTool_HS
 SG_ DgnInf : 7|64@0+ (1,0) [0|1.84467440737096E+019] ""  ARS_HS

BO_ 604 USDT_Req_to_ACCM_HS: 8 TestTool_HS
 SG_ DgnInf : 7|64@0+ (1,0) [0|1.84467440737096E+019] ""  ACCM_HS

BO_ 603 USDT_Req_to_ACC_HS: 8 TestTool_HS
 SG_ DgnInf : 7|64@0+ (1,0) [0|1.84467440737096E+019] ""  CGM_HS,ACC_HS

BO_ 602 USDT_Req_to_Free_5A_HS: 8 TestTool_HS
 SG_ DgnInf : 7|64@0+ (1,0) [0|1.84467440737096E+019] ""  Dummy_HS

BO_ 1631 USDT_Resp_From_VLBS_CGM_HS: 8 VLBS_HS
 SG_ DgnInf : 7|64@0+ (1,0) [0|1.84467440737096E+019] ""  ONSTAR_HS,TestTool_HS

BO_ 1375 UUDT_Resp_From_VLBS_CGM_HS: 8 VLBS_HS
 SG_ DgnInf_HS55F : 7|64@0+ (1,0) [0|1.84467440737096E+019] ""  ONSTAR_HS,TestTool_HS

BO_ 1374 UUDT_Resp_From_VCM_HS: 8 VCM_HS
 SG_ DgnInf_HS55E : 7|64@0+ (1,0) [0|1.84467440737096E+019] ""  CGM_HS,ONSTAR_HS,TestTool_HS

BO_TX_BU_ 1005 : CGM_HS,VLBS_HS,ONSTAR_HS;
BO_TX_BU_ 993 : BSM_HS,BCP_HS;
BO_TX_BU_ 490 : VCM_HS,FICM_HS,ECM_HS;
BO_TX_BU_ 715 : CGM_HS,EOCM_F_HS,ACC_HS;
BO_TX_BU_ 1932 : VLBS_HS,Dummy_HS;
BO_TX_BU_ 1931 : SAS_HS,Dummy_HS;
BO_TX_BU_ 1930 : CGM_HS,EOCM_F_HS,FCM_HS;
BO_TX_BU_ 1927 : BSM_HS,VICM_HS;
BO_TX_BU_ 1363 : CGM_HS,AMP_HS;
BO_TX_BU_ 607 : ONSTAR_HS,TestTool_HS;
BO_TX_BU_ 606 : CGM_HS,ONSTAR_HS,TestTool_HS;
BO_TX_BU_ 605 : CGM_HS,ONSTAR_HS,TestTool_HS;
BO_TX_BU_ 604 : CGM_HS,ONSTAR_HS,TestTool_HS;
BO_TX_BU_ 603 : CGM_HS,ONSTAR_HS,TestTool_HS;
BO_TX_BU_ 602 : CGM_HS,ONSTAR_HS,TestTool_HS;
BO_TX_BU_ 1631 : CGM_HS,VLBS_HS;
BO_TX_BU_ 1375 : CGM_HS,VLBS_HS;
CM_ SG_ 1005 EnhSvVehTopSpdLimP "4 ASCII characters";
CM_ BO_ 715 "Note that the ACC algorithm will transmit this message at a 50 ms periodic rate and the EOCM algorithm will transmit this message at a 40 ms periodic rate";
CM_ SG_ 1905 DTCI_DTCFaultType_771 "Based on Powertrain definition.  Not expected to be supported by all devices.";
CM_ SG_ 1905 DTCI_DTCFailType_771 "Assigned per GMW3110, Appendix E";
CM_ SG_ 1905 DTCI_DTCSource_771 "This shall be equal to the Diagnostic Address of the transmittting device.";
CM_ SG_ 1935 DTCI_DTCSource_78F "This shall be equal to the Diagnostic Address of the transmittting device.";
CM_ SG_ 1935 DTCI_DTCFaultType_78F "Based on Powertrain definition.  Not expected to be supported by all devices.";
CM_ SG_ 1935 DTCI_DTCFailType_78F "Assigned per GMW3110, Appendix E";
CM_ SG_ 1934 DTCI_DTCFailType_78E "Assigned per GMW3110, Appendix E";
CM_ SG_ 1934 DTCI_DTCFaultType_78E "Based on Powertrain definition.  Not expected to be supported by all devices.";
CM_ SG_ 1934 DTCI_DTCSource_78E "This shall be equal to the Diagnostic Address of the transmittting device.";
CM_ SG_ 1933 DTCI_DTCFailType_78D "Assigned per GMW3110, Appendix E";
CM_ SG_ 1933 DTCI_DTCFaultType_78D "Based on Powertrain definition.  Not expected to be supported by all devices.";
CM_ SG_ 1933 DTCI_DTCSource_78D "This shall be equal to the Diagnostic Address of the transmittting device.";
CM_ SG_ 1932 DTCI_DTCFailType_78C "Assigned per GMW3110, Appendix E";
CM_ SG_ 1932 DTCI_DTCFaultType_78C "Based on Powertrain definition.  Not expected to be supported by all devices.";
CM_ SG_ 1932 DTCI_DTCSource_78C "This shall be equal to the Diagnostic Address of the transmittting device.";
CM_ SG_ 1931 DTCI_DTCFailType_78B "Assigned per GMW3110, Appendix E";
CM_ SG_ 1931 DTCI_DTCFaultType_78B "Based on Powertrain definition.  Not expected to be supported by all devices.";
CM_ SG_ 1931 DTCI_DTCSource_78B "This shall be equal to the Diagnostic Address of the transmittting device.";
CM_ SG_ 1930 DTCI_DTCFailType_78A "Assigned per GMW3110, Appendix E";
CM_ SG_ 1930 DTCI_DTCFaultType_78A "Based on Powertrain definition.  Not expected to be supported by all devices.";
CM_ SG_ 1930 DTCI_DTCSource_78A "This shall be equal to the Diagnostic Address of the transmittting device.";
CM_ SG_ 1929 DTCI_DTCFailType_789 "Assigned per GMW3110, Appendix E";
CM_ SG_ 1929 DTCI_DTCFaultType_789 "Based on Powertrain definition.  Not expected to be supported by all devices.";
CM_ SG_ 1929 DTCI_DTCSource_789 "This shall be equal to the Diagnostic Address of the transmittting device.";
CM_ SG_ 1928 DTCI_DTCFailType_788 "Assigned per GMW3110, Appendix E";
CM_ SG_ 1928 DTCI_DTCFaultType_788 "Based on Powertrain definition.  Not expected to be supported by all devices.";
CM_ SG_ 1928 DTCI_DTCSource_788 "This shall be equal to the Diagnostic Address of the transmittting device.";
CM_ SG_ 1927 DTCI_DTCFailType_787 "Assigned per GMW3110, Appendix E";
CM_ SG_ 1927 DTCI_DTCFaultType_787 "Based on Powertrain definition.  Not expected to be supported by all devices.";
CM_ SG_ 1927 DTCI_DTCSource_787 "This shall be equal to the Diagnostic Address of the transmittting device.";
CM_ SG_ 1926 DTCI_DTCFailType_786 "Assigned per GMW3110, Appendix E";
CM_ SG_ 1926 DTCI_DTCFaultType_786 "Based on Powertrain definition.  Not expected to be supported by all devices.";
CM_ SG_ 1926 DTCI_DTCSource_786 "This shall be equal to the Diagnostic Address of the transmittting device.";
CM_ SG_ 1925 DTCI_DTCFailType_785 "Assigned per GMW3110, Appendix E";
CM_ SG_ 1925 DTCI_DTCFaultType_785 "Based on Powertrain definition.  Not expected to be supported by all devices.";
CM_ SG_ 1925 DTCI_DTCSource_785 "This shall be equal to the Diagnostic Address of the transmittting device.";
CM_ SG_ 1924 DTCI_DTCFailType_784 "Assigned per GMW3110, Appendix E";
CM_ SG_ 1924 DTCI_DTCFaultType_784 "Based on Powertrain definition.  Not expected to be supported by all devices.";
CM_ SG_ 1924 DTCI_DTCSource_784 "This shall be equal to the Diagnostic Address of the transmittting device.";
CM_ SG_ 1923 DTCI_DTCSource_783 "This shall be equal to the Diagnostic Address of the transmittting device.";
CM_ SG_ 1923 DTCI_DTCFaultType_783 "Based on Powertrain definition.  Not expected to be supported by all devices.";
CM_ SG_ 1923 DTCI_DTCFailType_783 "Assigned per GMW3110, Appendix E";
BA_DEF_ SG_  "VNSigSLHS_VNReq" ENUM  "No","Yes";
BA_DEF_ SG_  "VNSigSLHSSharedDiagnostic" ENUM  "No","Yes";
BA_DEF_ SG_  "SignalType" STRING ;
BA_DEF_ SG_  "PacketOrder" INT 0 65535;
BA_DEF_ SG_  "SignalLongName" STRING ;
BA_DEF_ SG_  "GenSigStartValue" INT 0 65535;
BA_DEF_ SG_  "VNSigAllNodes" ENUM  "No","Yes";
BA_DEF_ SG_  "GenSigDeltaValue" INT 0 0;
BA_DEF_ SG_  "GenSigSendType" ENUM  "not used","not used","not used","not used","not used","not used","not used","NoSigSendType","not used","not used","OnAnyChange","OnChangeIfActive","OnDelta";
BA_DEF_ SG_  "GenSigSendOnInit" ENUM  "Not Initialized","Application","Handler";
BA_DEF_ BO_  "AppGenMsgCycleTime" INT 0 0;
BA_DEF_ BO_  "TpTxIndex" INT 0 99;
BA_DEF_ BO_  "GenMsgILSupport" ENUM  "No","Yes";
BA_DEF_ BO_  "TpApplType" STRING ;
BA_DEF_ BO_  "Prio" INT 0 7;
BA_DEF_ BO_  "MessageSubnet" ENUM  "LS","MS","HS","CE","PE","HV","FO","S1","HE","LE","HE2";
BA_DEF_ BO_  "DiagState" ENUM  "No","Yes";
BA_DEF_ BO_  "GenMsgStartDelayTime" INT 0 100000;
BA_DEF_ BO_  "GenMsgDelayTime" INT 0 100000;
BA_DEF_ BO_  "GenMsgCycleTime" INT 0 100000;
BA_DEF_ BO_  "GenMsgSendType" ENUM  "cyclicX","spontanX","cyclicIfActiveX","spontanWithDelay","cyclicAndSpontanX","cyclicAndSpontanWithDelay","spontanWithRepitition","cyclicIfActiveAndSpontanWD";
BA_DEF_ BO_  "DiagResponse" ENUM  "No","Yes";
BA_DEF_ BO_  "DiagRequest" ENUM  "No","Yes";
BA_DEF_ BO_  "NmMessage" ENUM  "No","Yes";
BA_DEF_REL_ BU_SG_REL_  "GenSigSuprvRespComment" STRING ;
BA_DEF_REL_ BU_SG_REL_  "GenSigVBitResp" ENUM  "No","Yes";
BA_DEF_REL_ BU_SG_REL_  "GenSigVBitRespComment" STRING ;
BA_DEF_REL_ BU_SG_REL_  "GenSigVDAFailComment" STRING ;
BA_DEF_REL_ BU_SG_REL_  "GenSigVDAFailResp" ENUM  "No","Yes";
BA_DEF_REL_ BU_SG_REL_  "GenSigRxStartValue" STRING ;
BA_DEF_REL_ BU_SG_REL_  "GenSigSuprvRespSubValue" INT 0 65535;
BA_DEF_REL_ BU_SG_REL_  "GenSigSuprvResp" ENUM  "None","Notify App","Substitute Default";
BA_DEF_REL_ BU_SG_REL_  "GenSigTimeoutMsg" HEX -2147483648 268435455;
BA_DEF_REL_ BU_SG_REL_  "GenSigTimeoutTime" INT 0 15000;
BA_DEF_DEF_  "VNSigSLHS_VNReq" "No";
BA_DEF_DEF_  "VNSigSLHSSharedDiagnostic" "No";
BA_DEF_DEF_  "SignalType" "";
BA_DEF_DEF_  "PacketOrder" 0;
BA_DEF_DEF_  "SignalLongName" "";
BA_DEF_DEF_  "GenSigStartValue" 0;
BA_DEF_DEF_  "VNSigAllNodes" "No";
BA_DEF_DEF_  "GenSigDeltaValue" 0;
BA_DEF_DEF_  "GenSigSendType" "NoSigSendType";
BA_DEF_DEF_  "GenSigSendOnInit" "Not Initialized";
BA_DEF_DEF_  "AppGenMsgCycleTime" 0;
BA_DEF_DEF_  "TpTxIndex" 0;
BA_DEF_DEF_  "GenMsgILSupport" "Yes";
BA_DEF_DEF_  "TpApplType" "";
BA_DEF_DEF_  "Prio" 4;
BA_DEF_DEF_  "MessageSubnet" "FO";
BA_DEF_DEF_  "DiagState" "No";
BA_DEF_DEF_  "GenMsgStartDelayTime" 0;
BA_DEF_DEF_  "GenMsgDelayTime" 0;
BA_DEF_DEF_  "GenMsgCycleTime" 0;
BA_DEF_DEF_  "GenMsgSendType" "spontanX";
BA_DEF_DEF_  "DiagResponse" "No";
BA_DEF_DEF_  "DiagRequest" "No";
BA_DEF_DEF_  "NmMessage" "No";
BA_DEF_DEF_REL_ "GenSigSuprvRespComment" "";
BA_DEF_DEF_REL_ "GenSigVBitResp" "No";
BA_DEF_DEF_REL_ "GenSigVBitRespComment" "";
BA_DEF_DEF_REL_ "GenSigVDAFailComment" "";
BA_DEF_DEF_REL_ "GenSigVDAFailResp" "No";
BA_DEF_DEF_REL_ "GenSigRxStartValue" "";
BA_DEF_DEF_REL_ "GenSigSuprvRespSubValue" 0;
BA_DEF_DEF_REL_ "GenSigSuprvResp" "None";
BA_DEF_DEF_REL_ "GenSigTimeoutMsg" 0;
BA_DEF_DEF_REL_ "GenSigTimeoutTime" 0;
BA_ "Prio" BO_ 1005 0;
BA_ "MessageSubnet" BO_ 1005 2;
BA_ "GenMsgCycleTime" BO_ 1005 250;
BA_ "GenMsgSendType" BO_ 1005 0;
BA_ "Prio" BO_ 688 0;
BA_ "MessageSubnet" BO_ 688 2;
BA_ "GenMsgCycleTime" BO_ 688 20;
BA_ "GenMsgSendType" BO_ 688 0;
BA_ "Prio" BO_ 993 0;
BA_ "MessageSubnet" BO_ 993 2;
BA_ "GenMsgCycleTime" BO_ 993 100;
BA_ "GenMsgSendType" BO_ 993 0;
BA_ "Prio" BO_ 490 0;
BA_ "MessageSubnet" BO_ 490 2;
BA_ "GenMsgCycleTime" BO_ 490 12;
BA_ "GenMsgSendType" BO_ 490 0;
BA_ "Prio" BO_ 431 0;
BA_ "MessageSubnet" BO_ 431 2;
BA_ "GenMsgCycleTime" BO_ 431 25;
BA_ "GenMsgSendType" BO_ 431 0;
BA_ "AppGenMsgCycleTime" BO_ 715 40;
BA_ "Prio" BO_ 715 0;
BA_ "MessageSubnet" BO_ 715 2;
BA_ "Prio" BO_ 1267 0;
BA_ "MessageSubnet" BO_ 1267 2;
BA_ "GenMsgCycleTime" BO_ 1267 1000;
BA_ "GenMsgSendType" BO_ 1267 0;
BA_ "Prio" BO_ 453 0;
BA_ "MessageSubnet" BO_ 453 2;
BA_ "GenMsgCycleTime" BO_ 453 25;
BA_ "GenMsgSendType" BO_ 453 0;
BA_ "Prio" BO_ 452 0;
BA_ "MessageSubnet" BO_ 452 2;
BA_ "GenMsgCycleTime" BO_ 452 25;
BA_ "GenMsgSendType" BO_ 452 0;
BA_ "Prio" BO_ 1905 6;
BA_ "MessageSubnet" BO_ 1905 2;
BA_ "GenMsgCycleTime" BO_ 1905 1000;
BA_ "GenMsgSendType" BO_ 1905 0;
BA_ "Prio" BO_ 1935 0;
BA_ "MessageSubnet" BO_ 1935 2;
BA_ "GenMsgCycleTime" BO_ 1935 1000;
BA_ "GenMsgSendType" BO_ 1935 0;
BA_ "Prio" BO_ 1934 0;
BA_ "MessageSubnet" BO_ 1934 2;
BA_ "GenMsgCycleTime" BO_ 1934 1000;
BA_ "GenMsgSendType" BO_ 1934 0;
BA_ "Prio" BO_ 1933 0;
BA_ "MessageSubnet" BO_ 1933 2;
BA_ "GenMsgCycleTime" BO_ 1933 1000;
BA_ "GenMsgSendType" BO_ 1933 0;
BA_ "Prio" BO_ 1932 0;
BA_ "MessageSubnet" BO_ 1932 2;
BA_ "GenMsgCycleTime" BO_ 1932 1000;
BA_ "GenMsgSendType" BO_ 1932 0;
BA_ "Prio" BO_ 1931 0;
BA_ "MessageSubnet" BO_ 1931 2;
BA_ "GenMsgCycleTime" BO_ 1931 1000;
BA_ "GenMsgSendType" BO_ 1931 0;
BA_ "Prio" BO_ 1930 0;
BA_ "MessageSubnet" BO_ 1930 2;
BA_ "GenMsgCycleTime" BO_ 1930 1000;
BA_ "GenMsgSendType" BO_ 1930 0;
BA_ "Prio" BO_ 1929 0;
BA_ "MessageSubnet" BO_ 1929 2;
BA_ "GenMsgCycleTime" BO_ 1929 1000;
BA_ "GenMsgSendType" BO_ 1929 0;
BA_ "Prio" BO_ 1928 0;
BA_ "MessageSubnet" BO_ 1928 2;
BA_ "GenMsgCycleTime" BO_ 1928 1000;
BA_ "GenMsgSendType" BO_ 1928 0;
BA_ "Prio" BO_ 1927 0;
BA_ "MessageSubnet" BO_ 1927 2;
BA_ "GenMsgCycleTime" BO_ 1927 1000;
BA_ "GenMsgSendType" BO_ 1927 0;
BA_ "Prio" BO_ 1926 0;
BA_ "MessageSubnet" BO_ 1926 2;
BA_ "GenMsgCycleTime" BO_ 1926 1000;
BA_ "GenMsgSendType" BO_ 1926 0;
BA_ "Prio" BO_ 1925 0;
BA_ "MessageSubnet" BO_ 1925 2;
BA_ "GenMsgCycleTime" BO_ 1925 1000;
BA_ "GenMsgSendType" BO_ 1925 0;
BA_ "Prio" BO_ 1924 0;
BA_ "MessageSubnet" BO_ 1924 2;
BA_ "GenMsgCycleTime" BO_ 1924 1000;
BA_ "GenMsgSendType" BO_ 1924 0;
BA_ "Prio" BO_ 1923 0;
BA_ "MessageSubnet" BO_ 1923 2;
BA_ "GenMsgCycleTime" BO_ 1923 1000;
BA_ "GenMsgSendType" BO_ 1923 0;
BA_ "GenMsgILSupport" BO_ 1363 0;
BA_ "TpApplType" BO_ 1363 "DiagUUDTResponse";
BA_ "Prio" BO_ 1363 0;
BA_ "MessageSubnet" BO_ 1363 2;
BA_ "Prio" BO_ 607 0;
BA_ "MessageSubnet" BO_ 607 2;
BA_ "DiagRequest" BO_ 607 1;
BA_ "GenMsgILSupport" BO_ 1630 0;
BA_ "Prio" BO_ 1630 0;
BA_ "MessageSubnet" BO_ 1630 2;
BA_ "DiagResponse" BO_ 1630 1;
BA_ "GenMsgILSupport" BO_ 1629 0;
BA_ "Prio" BO_ 1629 0;
BA_ "MessageSubnet" BO_ 1629 2;
BA_ "DiagResponse" BO_ 1629 1;
BA_ "GenMsgILSupport" BO_ 606 0;
BA_ "Prio" BO_ 606 0;
BA_ "MessageSubnet" BO_ 606 2;
BA_ "DiagRequest" BO_ 606 1;
BA_ "GenMsgILSupport" BO_ 605 0;
BA_ "Prio" BO_ 605 0;
BA_ "MessageSubnet" BO_ 605 2;
BA_ "DiagRequest" BO_ 605 1;
BA_ "Prio" BO_ 604 0;
BA_ "MessageSubnet" BO_ 604 2;
BA_ "DiagRequest" BO_ 604 1;
BA_ "Prio" BO_ 603 0;
BA_ "MessageSubnet" BO_ 603 2;
BA_ "DiagRequest" BO_ 603 1;
BA_ "Prio" BO_ 602 0;
BA_ "MessageSubnet" BO_ 602 2;
BA_ "DiagRequest" BO_ 602 1;
BA_ "Prio" BO_ 1631 0;
BA_ "MessageSubnet" BO_ 1631 2;
BA_ "DiagResponse" BO_ 1631 1;
BA_ "GenMsgILSupport" BO_ 1375 0;
BA_ "TpApplType" BO_ 1375 "DiagUUDTResponse";
BA_ "Prio" BO_ 1375 0;
BA_ "MessageSubnet" BO_ 1375 2;
BA_ "GenMsgILSupport" BO_ 1374 0;
BA_ "TpApplType" BO_ 1374 "DiagUUDTResponse";
BA_ "Prio" BO_ 1374 0;
BA_ "MessageSubnet" BO_ 1374 2;
BA_ "SignalType" SG_ 1005 EnhSvVehTopSpdLmR "ENM";
BA_ "SignalLongName" SG_ 1005 EnhSvVehTopSpdLmR "Enhanced Services Vehicle Top Speed Limit Request";
BA_ "VNSigAllNodes" SG_ 1005 EnhSvVehTopSpdLmR 1;
BA_ "SignalType" SG_ 1005 EnhSvVTpSpdLVlARC "UNM";
BA_ "SignalLongName" SG_ 1005 EnhSvVTpSpdLVlARC "Enhanced Services Vehicle Top Speed Limit Value Alive Rolling Count";
BA_ "VNSigAllNodes" SG_ 1005 EnhSvVTpSpdLVlARC 1;
BA_ "SignalType" SG_ 1005 EnhSvVehTopSpdLimP "UNM";
BA_ "SignalLongName" SG_ 1005 EnhSvVehTopSpdLimP "Enhanced Services Vehicle Top Speed Limit Password";
BA_ "VNSigAllNodes" SG_ 1005 EnhSvVehTopSpdLimP 1;
BA_ "SignalType" SG_ 1005 EnhSvVehTopSpdLim "UNM";
BA_ "SignalLongName" SG_ 1005 EnhSvVehTopSpdLim "Enhanced Services Vehicle Top Speed Limit Value";
BA_ "GenSigStartValue" SG_ 1005 EnhSvVehTopSpdLim 255;
BA_ "VNSigAllNodes" SG_ 1005 EnhSvVehTopSpdLim 1;
BA_ "SignalType" SG_ 688 StrtrGenSpdV "ENM";
BA_ "SignalLongName" SG_ 688 StrtrGenSpdV "Starter Generator Speed  Validity";
BA_ "VNSigAllNodes" SG_ 688 StrtrGenSpdV 1;
BA_ "SignalType" SG_ 688 StrtrGenSpd "UNM";
BA_ "SignalLongName" SG_ 688 StrtrGenSpd "Starter Generator Speed";
BA_ "VNSigAllNodes" SG_ 688 StrtrGenSpd 1;
BA_ "SignalType" SG_ 993 CstmrUsblSOCV "ENM";
BA_ "SignalLongName" SG_ 993 CstmrUsblSOCV "Customer Usable State of Charge Validity";
BA_ "VNSigAllNodes" SG_ 993 CstmrUsblSOCV 1;
BA_ "SignalType" SG_ 993 CstmrUsblSOC "UNM";
BA_ "SignalLongName" SG_ 993 CstmrUsblSOC "Customer Usable State of Charge";
BA_ "VNSigAllNodes" SG_ 993 CstmrUsblSOC 1;
BA_ "SignalType" SG_ 993 InstDrvEff "SNM";
BA_ "SignalLongName" SG_ 993 InstDrvEff "Instantaneous Drive Efficiency";
BA_ "VNSigAllNodes" SG_ 993 InstDrvEff 1;
BA_ "SignalType" SG_ 993 PwrPckAirInTempFlt "UNM";
BA_ "SignalLongName" SG_ 993 PwrPckAirInTempFlt "Power Pack Air Inlet Temperature Filtered";
BA_ "VNSigAllNodes" SG_ 993 PwrPckAirInTempFlt 1;
BA_ "SignalType" SG_ 993 PwrPkFnSpd "UNM";
BA_ "SignalLongName" SG_ 993 PwrPkFnSpd "Power Pack Fan Speed";
BA_ "VNSigAllNodes" SG_ 993 PwrPkFnSpd 1;
BA_ "SignalType" SG_ 993 JmpStrtStat "ENM";
BA_ "SignalLongName" SG_ 993 JmpStrtStat "Jump Start Status";
BA_ "VNSigAllNodes" SG_ 993 JmpStrtStat 1;
BA_ "SignalType" SG_ 993 HybVehHiVltSysDisbld "BLN";
BA_ "SignalLongName" SG_ 993 HybVehHiVltSysDisbld "Hybrid Vehicle High Voltage System Disabled";
BA_ "VNSigAllNodes" SG_ 993 HybVehHiVltSysDisbld 1;
BA_ "SignalType" SG_ 993 SvcHybridSysIO "BLN";
BA_ "SignalLongName" SG_ 993 SvcHybridSysIO "Service Hybrid System Indication On";
BA_ "VNSigAllNodes" SG_ 993 SvcHybridSysIO 1;
BA_ "SignalType" SG_ 993 HybMdDisp "ENM";
BA_ "SignalLongName" SG_ 993 HybMdDisp "Hybrid Mode Display";
BA_ "VNSigAllNodes" SG_ 993 HybMdDisp 1;
BA_ "SignalType" SG_ 490 SrvcFlSysPrkInOpnArIO "BLN";
BA_ "SignalLongName" SG_ 490 SrvcFlSysPrkInOpnArIO "Service Fuel System Park In Open Area Indication On";
BA_ "VNSigAllNodes" SG_ 490 SrvcFlSysPrkInOpnArIO 1;
BA_ "SignalType" SG_ 490 FuelSysNEmsRltMalfAct "BLN";
BA_ "SignalLongName" SG_ 490 FuelSysNEmsRltMalfAct "Fuel System Non Emissions Related Malfunction Active";
BA_ "VNSigAllNodes" SG_ 490 FuelSysNEmsRltMalfAct 1;
BA_ "SignalType" SG_ 490 InActFuelMdFuelLvlIO "BLN";
BA_ "SignalLongName" SG_ 490 InActFuelMdFuelLvlIO "Inactive Fuel Mode Fuel Level Indication On";
BA_ "VNSigAllNodes" SG_ 490 InActFuelMdFuelLvlIO 1;
BA_ "SignalType" SG_ 490 FuelTotCapTnk2 "UNM";
BA_ "SignalLongName" SG_ 490 FuelTotCapTnk2 "Fuel Total Capacity Tank 2";
BA_ "VNSigAllNodes" SG_ 490 FuelTotCapTnk2 1;
BA_ "SignalType" SG_ 490 FlLvlTank2PctV "ENM";
BA_ "SignalLongName" SG_ 490 FlLvlTank2PctV "Fuel Level Tank 2 Percent Validity";
BA_ "VNSigAllNodes" SG_ 490 FlLvlTank2PctV 1;
BA_ "SignalType" SG_ 490 FlLvlTank2Pct "UNM";
BA_ "SignalLongName" SG_ 490 FlLvlTank2Pct "Fuel Level Tank 2 Percent";
BA_ "VNSigAllNodes" SG_ 490 FlLvlTank2Pct 1;
BA_ "SignalType" SG_ 490 AltFuelPHeatAct "BLN";
BA_ "SignalLongName" SG_ 490 AltFuelPHeatAct "Alternative Fuel Pre-heating Active";
BA_ "VNSigAllNodes" SG_ 490 AltFuelPHeatAct 1;
BA_ "SignalType" SG_ 490 AltFuelMdReqDndIO "BLN";
BA_ "SignalLongName" SG_ 490 AltFuelMdReqDndIO "Alternative Fuel Mode Request Denied Indication On";
BA_ "VNSigAllNodes" SG_ 490 AltFuelMdReqDndIO 1;
BA_ "SignalType" SG_ 490 AltFuelLvlLo "BLN";
BA_ "SignalLongName" SG_ 490 AltFuelLvlLo "Alternative Fuel Level Low";
BA_ "VNSigAllNodes" SG_ 490 AltFuelLvlLo 1;
BA_ "SignalType" SG_ 490 AltFuelAccWrnngAct "BLN";
BA_ "SignalLongName" SG_ 490 AltFuelAccWrnngAct "Alternative Fuel Acceleration Warning Active";
BA_ "VNSigAllNodes" SG_ 490 AltFuelAccWrnngAct 1;
BA_ "SignalType" SG_ 490 FuelMdStat "ENM";
BA_ "SignalLongName" SG_ 490 FuelMdStat "Fuel Mode Status";
BA_ "VNSigAllNodes" SG_ 490 FuelMdStat 1;
BA_ "SignalType" SG_ 431 TrnsInpCltchStatV "ENM";
BA_ "SignalLongName" SG_ 431 TrnsInpCltchStatV "Transmission Input Clutch Status Validity";
BA_ "VNSigAllNodes" SG_ 431 TrnsInpCltchStatV 1;
BA_ "SignalType" SG_ 431 TransCrnkPermsnStatV "ENM";
BA_ "SignalLongName" SG_ 431 TransCrnkPermsnStatV "Transmission Crank Permission Status Validity";
BA_ "VNSigAllNodes" SG_ 431 TransCrnkPermsnStatV 1;
BA_ "SignalType" SG_ 431 TransVehTopSpdLim "UNM";
BA_ "SignalLongName" SG_ 431 TransVehTopSpdLim "Transmission Vehicle Top Speed Limit Value";
BA_ "GenSigStartValue" SG_ 431 TransVehTopSpdLim 255;
BA_ "VNSigAllNodes" SG_ 431 TransVehTopSpdLim 1;
BA_ "SignalType" SG_ 431 TransMinVoltReq "UNM";
BA_ "SignalLongName" SG_ 431 TransMinVoltReq "Transmission Minimum Voltage Request";
BA_ "VNSigAllNodes" SG_ 431 TransMinVoltReq 1;
BA_ "SignalType" SG_ 431 TDslPrtFltrIdlRgtnMdAtv "BLN";
BA_ "SignalLongName" SG_ 431 TDslPrtFltrIdlRgtnMdAtv "Transmission Diesel Particulate Filter Idle Regeneration Mode Active";
BA_ "VNSigAllNodes" SG_ 431 TDslPrtFltrIdlRgtnMdAtv 1;
BA_ "SignalType" SG_ 431 DrvlneTrqStabStat "ENM";
BA_ "SignalLongName" SG_ 431 DrvlneTrqStabStat "Driveline Torque Stability Status";
BA_ "VNSigAllNodes" SG_ 431 DrvlneTrqStabStat 1;
BA_ "SignalType" SG_ 431 TrnsTrqCnvCltCmdMdF "BLN";
BA_ "SignalLongName" SG_ 431 TrnsTrqCnvCltCmdMdF "Transmission Torque Converter Clutch Commanded Mode Failure";
BA_ "VNSigAllNodes" SG_ 431 TrnsTrqCnvCltCmdMdF 1;
BA_ "SignalType" SG_ 431 AutoTransGrSftDirectFl "BLN";
BA_ "SignalLongName" SG_ 431 AutoTransGrSftDirectFl "Automatic Transmission Gear Shift Direction Failure";
BA_ "VNSigAllNodes" SG_ 431 AutoTransGrSftDirectFl 1;
BA_ "SignalType" SG_ 431 AutoTransGrSftDirect "ENM";
BA_ "SignalLongName" SG_ 431 AutoTransGrSftDirect "Automatic Transmission Gear Shift Direction";
BA_ "VNSigAllNodes" SG_ 431 AutoTransGrSftDirect 1;
BA_ "SignalType" SG_ 431 TrnsTrqCnvCltCmndMd "ENM";
BA_ "SignalLongName" SG_ 431 TrnsTrqCnvCltCmndMd "Transmission Torque Converter Clutch Commanded Mode";
BA_ "GenSigStartValue" SG_ 431 TrnsTrqCnvCltCmndMd 7;
BA_ "VNSigAllNodes" SG_ 431 TrnsTrqCnvCltCmndMd 1;
BA_ "SignalType" SG_ 431 TrnsTrqCnvCltDsrSlp "SNM";
BA_ "SignalLongName" SG_ 431 TrnsTrqCnvCltDsrSlp "Transmission Torque Converter Clutch Desired Slip";
BA_ "VNSigAllNodes" SG_ 431 TrnsTrqCnvCltDsrSlp 1;
BA_ "SignalType" SG_ 431 TrnsStWntrMdOvrd "ENM";
BA_ "SignalLongName" SG_ 431 TrnsStWntrMdOvrd "Transmission State Winter Mode Override";
BA_ "VNSigAllNodes" SG_ 431 TrnsStWntrMdOvrd 1;
BA_ "SignalType" SG_ 431 TrnsStTwHaulMdOvrd "ENM";
BA_ "SignalLongName" SG_ 431 TrnsStTwHaulMdOvrd "Transmission State Tow Haul Mode Override";
BA_ "VNSigAllNodes" SG_ 431 TrnsStTwHaulMdOvrd 1;
BA_ "SignalType" SG_ 431 TrnsStSprtMdOvrd "ENM";
BA_ "SignalLongName" SG_ 431 TrnsStSprtMdOvrd "Transmission State Sport Mode Override";
BA_ "VNSigAllNodes" SG_ 431 TrnsStSprtMdOvrd 1;
BA_ "SignalType" SG_ 431 TrnsStEconMdOvrd "ENM";
BA_ "SignalLongName" SG_ 431 TrnsStEconMdOvrd "Transmission State Economy Mode Override";
BA_ "VNSigAllNodes" SG_ 431 TrnsStEconMdOvrd 1;
BA_ "SignalType" SG_ 431 TrnsInpCltchStat "ENM";
BA_ "SignalLongName" SG_ 431 TrnsInpCltchStat "Transmission Input Clutch Status";
BA_ "VNSigAllNodes" SG_ 431 TrnsInpCltchStat 1;
BA_ "SignalType" SG_ 431 TrnsAntcptdCrpTrqRRnV "ENM";
BA_ "SignalLongName" SG_ 431 TrnsAntcptdCrpTrqRRnV "Transmission Anticipated Creep Torque Reduced Range Validity";
BA_ "VNSigAllNodes" SG_ 431 TrnsAntcptdCrpTrqRRnV 1;
BA_ "SignalType" SG_ 431 TrnsAntcptdCrpTrqRRn "UNM";
BA_ "SignalLongName" SG_ 431 TrnsAntcptdCrpTrqRRn "Transmission Anticipated Creep Torque Reduced Range";
BA_ "VNSigAllNodes" SG_ 431 TrnsAntcptdCrpTrqRRn 1;
BA_ "SignalType" SG_ 431 TrnCltAdpAtv "BLN";
BA_ "SignalLongName" SG_ 431 TrnCltAdpAtv "Transmission Clutch Adaptation Active";
BA_ "VNSigAllNodes" SG_ 431 TrnCltAdpAtv 1;
BA_ "SignalType" SG_ 431 TransCrnkPermsnStat "ENM";
BA_ "SignalLongName" SG_ 431 TransCrnkPermsnStat "Transmission Crank Permission Status";
BA_ "VNSigAllNodes" SG_ 431 TransCrnkPermsnStat 1;
BA_ "SignalType" SG_ 431 WrmUpShftPtrn "ENM";
BA_ "SignalLongName" SG_ 431 WrmUpShftPtrn "Warm Up Shift Pattern Status";
BA_ "VNSigAllNodes" SG_ 431 WrmUpShftPtrn 1;
BA_ "SignalType" SG_ 715 ACCATC_SplREngInpR "BLN";
BA_ "PacketOrder" SG_ 715 ACCATC_SplREngInpR 4;
BA_ "SignalLongName" SG_ 715 ACCATC_SplREngInpR "Adaptive Cruise Control Axle Torque Command : Special Re-engagement Input Required";
BA_ "VNSigAllNodes" SG_ 715 ACCATC_SplREngInpR 1;
BA_ "SignalType" SG_ 715 ACCATC_DrvAstdGoSt "ENM";
BA_ "PacketOrder" SG_ 715 ACCATC_DrvAstdGoSt 3;
BA_ "SignalLongName" SG_ 715 ACCATC_DrvAstdGoSt "Adaptive Cruise Control Axle Torque Command : Driver Assisted Go State";
BA_ "VNSigAllNodes" SG_ 715 ACCATC_DrvAstdGoSt 1;
BA_ "SignalType" SG_ 715 ACCATC_AxlTrqRq "UNM";
BA_ "PacketOrder" SG_ 715 ACCATC_AxlTrqRq 5;
BA_ "SignalLongName" SG_ 715 ACCATC_AxlTrqRq "Adaptive Cruise Control Axle Torque Command : Axle Torque Request";
BA_ "VNSigAllNodes" SG_ 715 ACCATC_AxlTrqRq 1;
BA_ "SignalType" SG_ 715 ACCATC_ACCTyp "ENM";
BA_ "PacketOrder" SG_ 715 ACCATC_ACCTyp 2;
BA_ "SignalLongName" SG_ 715 ACCATC_ACCTyp "Adaptive Cruise Control Axle Torque Command : Adaptive Cruise Control Type";
BA_ "VNSigAllNodes" SG_ 715 ACCATC_ACCTyp 1;
BA_ "SignalType" SG_ 715 ACCATC_ACCAct "BLN";
BA_ "PacketOrder" SG_ 715 ACCATC_ACCAct 1;
BA_ "SignalLongName" SG_ 715 ACCATC_ACCAct "Adaptive Cruise Control Axle Torque Command : Adaptive Cruise Control Active";
BA_ "VNSigAllNodes" SG_ 715 ACCATC_ACCAct 1;
BA_ "SignalType" SG_ 715 ACCAxlTrqCmdProt "UNM";
BA_ "SignalLongName" SG_ 715 ACCAxlTrqCmdProt "Adaptive Cruise Control Axle torque Command Protection";
BA_ "VNSigAllNodes" SG_ 715 ACCAxlTrqCmdProt 1;
BA_ "SignalType" SG_ 715 ACCCmndAlvRlgCnt "UNM";
BA_ "SignalLongName" SG_ 715 ACCCmndAlvRlgCnt "Adaptive Cruise Control Command Alive Rolling Count";
BA_ "VNSigAllNodes" SG_ 715 ACCCmndAlvRlgCnt 1;
BA_ "SignalType" SG_ 1267 VehMassNom "UNM";
BA_ "SignalLongName" SG_ 1267 VehMassNom "Vehicle Mass Nominal";
BA_ "VNSigAllNodes" SG_ 1267 VehMassNom 1;
BA_ "SignalType" SG_ 453 DrvIntndAxlTrqV "ENM";
BA_ "SignalLongName" SG_ 453 DrvIntndAxlTrqV "Driver Intended Axle Torque Validity";
BA_ "VNSigAllNodes" SG_ 453 DrvIntndAxlTrqV 1;
BA_ "SignalType" SG_ 453 DrvIntndAxlTrqMinV "ENM";
BA_ "SignalLongName" SG_ 453 DrvIntndAxlTrqMinV "Driver Intended Axle Torque Minimum Validity";
BA_ "VNSigAllNodes" SG_ 453 DrvIntndAxlTrqMinV 1;
BA_ "SignalType" SG_ 453 DrvIntndAxlTrqMin "UNM";
BA_ "SignalLongName" SG_ 453 DrvIntndAxlTrqMin "Driver Intended Axle Torque Minimum";
BA_ "VNSigAllNodes" SG_ 453 DrvIntndAxlTrqMin 1;
BA_ "SignalType" SG_ 453 DrvIntndAxlTrqMaxV "ENM";
BA_ "SignalLongName" SG_ 453 DrvIntndAxlTrqMaxV "Driver Intended Axle Torque Maximum Validity";
BA_ "VNSigAllNodes" SG_ 453 DrvIntndAxlTrqMaxV 1;
BA_ "SignalType" SG_ 453 DrvIntndAxlTrqMax "UNM";
BA_ "SignalLongName" SG_ 453 DrvIntndAxlTrqMax "Driver Intended Axle Torque Maximum";
BA_ "GenSigStartValue" SG_ 453 DrvIntndAxlTrqMax 32767;
BA_ "VNSigAllNodes" SG_ 453 DrvIntndAxlTrqMax 1;
BA_ "SignalType" SG_ 453 DrvIntndAxlTrq "UNM";
BA_ "SignalLongName" SG_ 453 DrvIntndAxlTrq "Driver Intended Axle Torque";
BA_ "GenSigStartValue" SG_ 453 DrvIntndAxlTrq 11267;
BA_ "VNSigAllNodes" SG_ 453 DrvIntndAxlTrq 1;
BA_ "SignalType" SG_ 452 FSpRgACCSwADdPVal "UNM";
BA_ "SignalLongName" SG_ 452 FSpRgACCSwADdPVal "Full Speed Range ACC Cruise Switch Action Detected Protection Value";
BA_ "VNSigAllNodes" SG_ 452 FSpRgACCSwADdPVal 1;
BA_ "SignalType" SG_ 452 FSpRgACCSwADdARC "UNM";
BA_ "SignalLongName" SG_ 452 FSpRgACCSwADdARC "Full Speed Range ACC Cruise Switch Action Detected Alive Rolling Count";
BA_ "VNSigAllNodes" SG_ 452 FSpRgACCSwADdARC 1;
BA_ "SignalType" SG_ 452 FSpRgACCSwADd "BLN";
BA_ "SignalLongName" SG_ 452 FSpRgACCSwADd "Full Speed Range ACC Cruise Switch Action Detected";
BA_ "VNSigAllNodes" SG_ 452 FSpRgACCSwADd 1;
BA_ "SignalType" SG_ 452 AutBrkAccActPsStRC "UNM";
BA_ "SignalLongName" SG_ 452 AutBrkAccActPsStRC "Autonomous Braking Accelerator Actual Position Status Rolling Count";
BA_ "VNSigAllNodes" SG_ 452 AutBrkAccActPsStRC 1;
BA_ "SignalType" SG_ 452 AutBrkAccActPsStPVal "UNM";
BA_ "SignalLongName" SG_ 452 AutBrkAccActPsStPVal "Autonomous Braking Accelerator Actual Position Status Protection Value";
BA_ "VNSigAllNodes" SG_ 452 AutBrkAccActPsStPVal 1;
BA_ "SignalType" SG_ 452 ABAAPS_AccPos "UNM";
BA_ "PacketOrder" SG_ 452 ABAAPS_AccPos 2;
BA_ "SignalLongName" SG_ 452 ABAAPS_AccPos "Autonomous Braking Accelerator Actual Position Status : Accelerator Position";
BA_ "VNSigAllNodes" SG_ 452 ABAAPS_AccPos 1;
BA_ "SignalType" SG_ 452 ABAAPS_AccPosV "ENM";
BA_ "PacketOrder" SG_ 452 ABAAPS_AccPosV 1;
BA_ "SignalLongName" SG_ 452 ABAAPS_AccPosV "Autonomous Braking Accelerator Actual Position Status : Accelerator Position Validity";
BA_ "VNSigAllNodes" SG_ 452 ABAAPS_AccPosV 1;
BA_ "SignalType" SG_ 452 ACCATCS_LmtgStat "ENM";
BA_ "PacketOrder" SG_ 452 ACCATCS_LmtgStat 2;
BA_ "SignalLongName" SG_ 452 ACCATCS_LmtgStat "Adaptive Cruise Control Axle Torque Command Status : Limiting Status";
BA_ "VNSigAllNodes" SG_ 452 ACCATCS_LmtgStat 1;
BA_ "SignalType" SG_ 452 ACCATCS_RqStat "ENM";
BA_ "PacketOrder" SG_ 452 ACCATCS_RqStat 1;
BA_ "SignalLongName" SG_ 452 ACCATCS_RqStat "Adaptive Cruise Control Axle Torque Command Status : Request Status";
BA_ "VNSigAllNodes" SG_ 452 ACCATCS_RqStat 1;
BA_ "SignalType" SG_ 452 RdLdNomAxlTrq "UNM";
BA_ "SignalLongName" SG_ 452 RdLdNomAxlTrq "Road Load Nominal Axle Torque";
BA_ "VNSigAllNodes" SG_ 452 RdLdNomAxlTrq 1;
BA_ "SignalType" SG_ 452 AccPdlOvrrdAtvProtVal "UNM";
BA_ "SignalLongName" SG_ 452 AccPdlOvrrdAtvProtVal "Accelerator Pedal Override Active Protection Value";
BA_ "VNSigAllNodes" SG_ 452 AccPdlOvrrdAtvProtVal 1;
BA_ "SignalType" SG_ 452 AccPdlOvrrdAtvARC "UNM";
BA_ "SignalLongName" SG_ 452 AccPdlOvrrdAtvARC "Accelerator Pedal Override Active Alive Rolling Count";
BA_ "VNSigAllNodes" SG_ 452 AccPdlOvrrdAtvARC 1;
BA_ "SignalType" SG_ 452 AccPdlOvrrdAtv "BLN";
BA_ "SignalLongName" SG_ 452 AccPdlOvrrdAtv "Accelerator Pedal Override Active";
BA_ "VNSigAllNodes" SG_ 452 AccPdlOvrrdAtv 1;
BA_ "SignalType" SG_ 452 CPSATCS_ReqStatus "ENM";
BA_ "PacketOrder" SG_ 452 CPSATCS_ReqStatus 2;
BA_ "SignalLongName" SG_ 452 CPSATCS_ReqStatus "Collision Preparation System Axle Torque Command Status : Request Status";
BA_ "VNSigAllNodes" SG_ 452 CPSATCS_ReqStatus 1;
BA_ "SignalType" SG_ 452 CPSATCS_LmtngStatus "ENM";
BA_ "PacketOrder" SG_ 452 CPSATCS_LmtngStatus 1;
BA_ "SignalLongName" SG_ 452 CPSATCS_LmtngStatus "Collision Preparation System Axle Torque Command Status : Limiting Status";
BA_ "VNSigAllNodes" SG_ 452 CPSATCS_LmtngStatus 1;
BA_ "SignalType" SG_ 452 RVBATCS_ReqStat "ENM";
BA_ "PacketOrder" SG_ 452 RVBATCS_ReqStat 2;
BA_ "SignalLongName" SG_ 452 RVBATCS_ReqStat "Rear Virtual Bumper Axle Torque Command Status : Request Status";
BA_ "VNSigAllNodes" SG_ 452 RVBATCS_ReqStat 1;
BA_ "SignalType" SG_ 452 RVBATCS_LmtngStat "ENM";
BA_ "PacketOrder" SG_ 452 RVBATCS_LmtngStat 1;
BA_ "SignalLongName" SG_ 452 RVBATCS_LmtngStat "Rear Virtual Bumper Axle Torque Command Status : Limiting Status";
BA_ "VNSigAllNodes" SG_ 452 RVBATCS_LmtngStat 1;
BA_ "SignalType" SG_ 1905 DTCI_DTCFaultType_771 "ENM";
BA_ "PacketOrder" SG_ 1905 DTCI_DTCFaultType_771 20;
BA_ "SignalLongName" SG_ 1905 DTCI_DTCFaultType_771 "Diagnostic Trouble Code Information Extended : Diagnostic Trouble Code Fault Type";
BA_ "VNSigAllNodes" SG_ 1905 DTCI_DTCFaultType_771 1;
BA_ "SignalType" SG_ 1905 DTCI_CodeSupported_771 "BLN";
BA_ "PacketOrder" SG_ 1905 DTCI_CodeSupported_771 19;
BA_ "SignalLongName" SG_ 1905 DTCI_CodeSupported_771 "Diagnostic Trouble Code Information Extended : Code Supported";
BA_ "VNSigAllNodes" SG_ 1905 DTCI_CodeSupported_771 1;
BA_ "SignalType" SG_ 1905 DTCI_CurrentStatus_771 "BLN";
BA_ "PacketOrder" SG_ 1905 DTCI_CurrentStatus_771 18;
BA_ "SignalLongName" SG_ 1905 DTCI_CurrentStatus_771 "Diagnostic Trouble Code Information Extended : Current Status";
BA_ "VNSigAllNodes" SG_ 1905 DTCI_CurrentStatus_771 1;
BA_ "SignalType" SG_ 1905 DTCI_TstNPsdCdClrdSt_771 "BLN";
BA_ "PacketOrder" SG_ 1905 DTCI_TstNPsdCdClrdSt_771 17;
BA_ "SignalLongName" SG_ 1905 DTCI_TstNPsdCdClrdSt_771 "Diagnostic Trouble Code Information Extended : Test Not Passed Since Code Cleared Status";
BA_ "VNSigAllNodes" SG_ 1905 DTCI_TstNPsdCdClrdSt_771 1;
BA_ "SignalType" SG_ 1905 DTCI_TstFldCdClrdStat_771 "BLN";
BA_ "PacketOrder" SG_ 1905 DTCI_TstFldCdClrdStat_771 16;
BA_ "SignalLongName" SG_ 1905 DTCI_TstFldCdClrdStat_771 "Diagnostic Trouble Code Information Extended : Test Failed Since Code Cleared Status";
BA_ "VNSigAllNodes" SG_ 1905 DTCI_TstFldCdClrdStat_771 1;
BA_ "SignalType" SG_ 1905 DTCI_HistStat_771 "BLN";
BA_ "PacketOrder" SG_ 1905 DTCI_HistStat_771 15;
BA_ "SignalLongName" SG_ 1905 DTCI_HistStat_771 "Diagnostic Trouble Code Information Extended : History Status";
BA_ "VNSigAllNodes" SG_ 1905 DTCI_HistStat_771 1;
BA_ "SignalType" SG_ 1905 DTCI_TstNPsdPwrUpSt_771 "BLN";
BA_ "PacketOrder" SG_ 1905 DTCI_TstNPsdPwrUpSt_771 14;
BA_ "SignalLongName" SG_ 1905 DTCI_TstNPsdPwrUpSt_771 "Diagnostic Trouble Code Information Extended : Test Not Passed Since Power Up Status";
BA_ "VNSigAllNodes" SG_ 1905 DTCI_TstNPsdPwrUpSt_771 1;
BA_ "SignalType" SG_ 1905 DTCI_TstFldPwrUpSt_771 "BLN";
BA_ "PacketOrder" SG_ 1905 DTCI_TstFldPwrUpSt_771 13;
BA_ "SignalLongName" SG_ 1905 DTCI_TstFldPwrUpSt_771 "Diagnostic Trouble Code Information Extended : Test Failed Since Power Up Status";
BA_ "VNSigAllNodes" SG_ 1905 DTCI_TstFldPwrUpSt_771 1;
BA_ "SignalType" SG_ 1905 DTCI_WrnIndRqdSt_771 "BLN";
BA_ "PacketOrder" SG_ 1905 DTCI_WrnIndRqdSt_771 12;
BA_ "SignalLongName" SG_ 1905 DTCI_WrnIndRqdSt_771 "Diagnostic Trouble Code Information Extended : Warning Indicator Requested Status";
BA_ "VNSigAllNodes" SG_ 1905 DTCI_WrnIndRqdSt_771 1;
BA_ "SignalType" SG_ 1905 DTCI_DTCFailType_771 "UNM";
BA_ "PacketOrder" SG_ 1905 DTCI_DTCFailType_771 11;
BA_ "SignalLongName" SG_ 1905 DTCI_DTCFailType_771 "Diagnostic Trouble Code Information Extended : Diagnostic Trouble Code Failure Type";
BA_ "VNSigAllNodes" SG_ 1905 DTCI_DTCFailType_771 1;
BA_ "SignalType" SG_ 1905 DTCI_DTCNumber_771 "UNM";
BA_ "PacketOrder" SG_ 1905 DTCI_DTCNumber_771 10;
BA_ "SignalLongName" SG_ 1905 DTCI_DTCNumber_771 "Diagnostic Trouble Code Information Extended : Diagnostic Trouble Code Number";
BA_ "VNSigAllNodes" SG_ 1905 DTCI_DTCNumber_771 1;
BA_ "SignalType" SG_ 1905 DTCI_DTCSource_771 "UNM";
BA_ "PacketOrder" SG_ 1905 DTCI_DTCSource_771 9;
BA_ "SignalLongName" SG_ 1905 DTCI_DTCSource_771 "Diagnostic Trouble Code Information Extended : Diagnostic Trouble Code Source";
BA_ "VNSigAllNodes" SG_ 1905 DTCI_DTCSource_771 1;
BA_ "SignalType" SG_ 1905 DTCI_DTCTriggered_771 "BLN";
BA_ "PacketOrder" SG_ 1905 DTCI_DTCTriggered_771 8;
BA_ "SignalLongName" SG_ 1905 DTCI_DTCTriggered_771 "Diagnostic Trouble Code Information Extended : Diagnostic Trouble Code Triggered";
BA_ "VNSigAllNodes" SG_ 1905 DTCI_DTCTriggered_771 1;
BA_ "SignalType" SG_ 1905 DTCIUnused7_771 "BLN";
BA_ "PacketOrder" SG_ 1905 DTCIUnused7_771 7;
BA_ "SignalLongName" SG_ 1905 DTCIUnused7_771 "Diagnostic Trouble Code Information Extended : Unused 7";
BA_ "VNSigAllNodes" SG_ 1905 DTCIUnused7_771 1;
BA_ "SignalType" SG_ 1905 DTCIUnused6_771 "BLN";
BA_ "PacketOrder" SG_ 1905 DTCIUnused6_771 6;
BA_ "SignalLongName" SG_ 1905 DTCIUnused6_771 "Diagnostic Trouble Code Information Extended : Unused 6";
BA_ "VNSigAllNodes" SG_ 1905 DTCIUnused6_771 1;
BA_ "SignalType" SG_ 1905 DTCIUnused5_771 "BLN";
BA_ "PacketOrder" SG_ 1905 DTCIUnused5_771 5;
BA_ "SignalLongName" SG_ 1905 DTCIUnused5_771 "Diagnostic Trouble Code Information Extended : Unused 5";
BA_ "VNSigAllNodes" SG_ 1905 DTCIUnused5_771 1;
BA_ "SignalType" SG_ 1905 DTCIUnused4_771 "BLN";
BA_ "PacketOrder" SG_ 1905 DTCIUnused4_771 4;
BA_ "SignalLongName" SG_ 1905 DTCIUnused4_771 "Diagnostic Trouble Code Information Extended : Unused 4";
BA_ "VNSigAllNodes" SG_ 1905 DTCIUnused4_771 1;
BA_ "SignalType" SG_ 1905 DTCIUnused3_771 "BLN";
BA_ "PacketOrder" SG_ 1905 DTCIUnused3_771 3;
BA_ "SignalLongName" SG_ 1905 DTCIUnused3_771 "Diagnostic Trouble Code Information Extended : Unused 3";
BA_ "VNSigAllNodes" SG_ 1905 DTCIUnused3_771 1;
BA_ "SignalType" SG_ 1905 DTCIUnused2_771 "BLN";
BA_ "PacketOrder" SG_ 1905 DTCIUnused2_771 2;
BA_ "SignalLongName" SG_ 1905 DTCIUnused2_771 "Diagnostic Trouble Code Information Extended : Unused 2";
BA_ "VNSigAllNodes" SG_ 1905 DTCIUnused2_771 1;
BA_ "SignalType" SG_ 1905 DTCIUnused1_771 "BLN";
BA_ "PacketOrder" SG_ 1905 DTCIUnused1_771 1;
BA_ "SignalLongName" SG_ 1905 DTCIUnused1_771 "Diagnostic Trouble Code Information Extended : Unused 1";
BA_ "VNSigAllNodes" SG_ 1905 DTCIUnused1_771 1;
BA_ "SignalType" SG_ 1935 DTCI_DTCSource_78F "UNM";
BA_ "PacketOrder" SG_ 1935 DTCI_DTCSource_78F 9;
BA_ "SignalLongName" SG_ 1935 DTCI_DTCSource_78F "Diagnostic Trouble Code Information Extended 78F : Diagnostic Trouble Code Source";
BA_ "VNSigAllNodes" SG_ 1935 DTCI_DTCSource_78F 1;
BA_ "SignalType" SG_ 1935 DTCI_DTCTriggered_78F "BLN";
BA_ "PacketOrder" SG_ 1935 DTCI_DTCTriggered_78F 8;
BA_ "SignalLongName" SG_ 1935 DTCI_DTCTriggered_78F "Diagnostic Trouble Code Information Extended 78F : Diagnostic Trouble Code Triggered";
BA_ "VNSigAllNodes" SG_ 1935 DTCI_DTCTriggered_78F 1;
BA_ "SignalType" SG_ 1935 DTCIUnused1_78F "BLN";
BA_ "PacketOrder" SG_ 1935 DTCIUnused1_78F 1;
BA_ "SignalLongName" SG_ 1935 DTCIUnused1_78F "Diagnostic Trouble Code Information Extended 78F : Unused 1";
BA_ "VNSigAllNodes" SG_ 1935 DTCIUnused1_78F 1;
BA_ "SignalType" SG_ 1935 DTCIUnused2_78F "BLN";
BA_ "PacketOrder" SG_ 1935 DTCIUnused2_78F 2;
BA_ "SignalLongName" SG_ 1935 DTCIUnused2_78F "Diagnostic Trouble Code Information Extended 78F : Unused 2";
BA_ "VNSigAllNodes" SG_ 1935 DTCIUnused2_78F 1;
BA_ "SignalType" SG_ 1935 DTCIUnused3_78F "BLN";
BA_ "PacketOrder" SG_ 1935 DTCIUnused3_78F 3;
BA_ "SignalLongName" SG_ 1935 DTCIUnused3_78F "Diagnostic Trouble Code Information Extended 78F : Unused 3";
BA_ "VNSigAllNodes" SG_ 1935 DTCIUnused3_78F 1;
BA_ "SignalType" SG_ 1935 DTCIUnused4_78F "BLN";
BA_ "PacketOrder" SG_ 1935 DTCIUnused4_78F 4;
BA_ "SignalLongName" SG_ 1935 DTCIUnused4_78F "Diagnostic Trouble Code Information Extended 78F : Unused 4";
BA_ "VNSigAllNodes" SG_ 1935 DTCIUnused4_78F 1;
BA_ "SignalType" SG_ 1935 DTCIUnused5_78F "BLN";
BA_ "PacketOrder" SG_ 1935 DTCIUnused5_78F 5;
BA_ "SignalLongName" SG_ 1935 DTCIUnused5_78F "Diagnostic Trouble Code Information Extended 78F : Unused 5";
BA_ "VNSigAllNodes" SG_ 1935 DTCIUnused5_78F 1;
BA_ "SignalType" SG_ 1935 DTCIUnused6_78F "BLN";
BA_ "PacketOrder" SG_ 1935 DTCIUnused6_78F 6;
BA_ "SignalLongName" SG_ 1935 DTCIUnused6_78F "Diagnostic Trouble Code Information Extended 78F : Unused 6";
BA_ "VNSigAllNodes" SG_ 1935 DTCIUnused6_78F 1;
BA_ "SignalType" SG_ 1935 DTCIUnused7_78F "BLN";
BA_ "PacketOrder" SG_ 1935 DTCIUnused7_78F 7;
BA_ "SignalLongName" SG_ 1935 DTCIUnused7_78F "Diagnostic Trouble Code Information Extended 78F : Unused 7";
BA_ "VNSigAllNodes" SG_ 1935 DTCIUnused7_78F 1;
BA_ "SignalType" SG_ 1935 DTCI_CodeSupported_78F "BLN";
BA_ "PacketOrder" SG_ 1935 DTCI_CodeSupported_78F 19;
BA_ "SignalLongName" SG_ 1935 DTCI_CodeSupported_78F "Diagnostic Trouble Code Information Extended 78F : Code Supported";
BA_ "VNSigAllNodes" SG_ 1935 DTCI_CodeSupported_78F 1;
BA_ "SignalType" SG_ 1935 DTCI_CurrentStatus_78F "BLN";
BA_ "PacketOrder" SG_ 1935 DTCI_CurrentStatus_78F 18;
BA_ "SignalLongName" SG_ 1935 DTCI_CurrentStatus_78F "Diagnostic Trouble Code Information Extended 78F : Current Status";
BA_ "VNSigAllNodes" SG_ 1935 DTCI_CurrentStatus_78F 1;
BA_ "SignalType" SG_ 1935 DTCI_DTCFaultType_78F "ENM";
BA_ "PacketOrder" SG_ 1935 DTCI_DTCFaultType_78F 20;
BA_ "SignalLongName" SG_ 1935 DTCI_DTCFaultType_78F "Diagnostic Trouble Code Information Extended 78F : Diagnostic Trouble Code Fault Type";
BA_ "VNSigAllNodes" SG_ 1935 DTCI_DTCFaultType_78F 1;
BA_ "SignalType" SG_ 1935 DTCI_TstFldCdClrdStat_78F "BLN";
BA_ "PacketOrder" SG_ 1935 DTCI_TstFldCdClrdStat_78F 16;
BA_ "SignalLongName" SG_ 1935 DTCI_TstFldCdClrdStat_78F "Diagnostic Trouble Code Information Extended 78F : Test Failed Since Code Cleared Status";
BA_ "VNSigAllNodes" SG_ 1935 DTCI_TstFldCdClrdStat_78F 1;
BA_ "SignalType" SG_ 1935 DTCI_TstNPsdCdClrdSt_78F "BLN";
BA_ "PacketOrder" SG_ 1935 DTCI_TstNPsdCdClrdSt_78F 17;
BA_ "SignalLongName" SG_ 1935 DTCI_TstNPsdCdClrdSt_78F "Diagnostic Trouble Code Information Extended 78F : Test Not Passed Since Code Cleared Status";
BA_ "VNSigAllNodes" SG_ 1935 DTCI_TstNPsdCdClrdSt_78F 1;
BA_ "SignalType" SG_ 1935 DTCI_HistStat_78F "BLN";
BA_ "PacketOrder" SG_ 1935 DTCI_HistStat_78F 15;
BA_ "SignalLongName" SG_ 1935 DTCI_HistStat_78F "Diagnostic Trouble Code Information Extended 78F : History Status";
BA_ "VNSigAllNodes" SG_ 1935 DTCI_HistStat_78F 1;
BA_ "SignalType" SG_ 1935 DTCI_TstNPsdPwrUpSt_78F "BLN";
BA_ "PacketOrder" SG_ 1935 DTCI_TstNPsdPwrUpSt_78F 14;
BA_ "SignalLongName" SG_ 1935 DTCI_TstNPsdPwrUpSt_78F "Diagnostic Trouble Code Information Extended 78F : Test Not Passed Since Power Up Status";
BA_ "VNSigAllNodes" SG_ 1935 DTCI_TstNPsdPwrUpSt_78F 1;
BA_ "SignalType" SG_ 1935 DTCI_TstFldPwrUpSt_78F "BLN";
BA_ "PacketOrder" SG_ 1935 DTCI_TstFldPwrUpSt_78F 13;
BA_ "SignalLongName" SG_ 1935 DTCI_TstFldPwrUpSt_78F "Diagnostic Trouble Code Information Extended 78F : Test Failed Since Power Up Status";
BA_ "VNSigAllNodes" SG_ 1935 DTCI_TstFldPwrUpSt_78F 1;
BA_ "SignalType" SG_ 1935 DTCI_WrnIndRqdSt_78F "BLN";
BA_ "PacketOrder" SG_ 1935 DTCI_WrnIndRqdSt_78F 12;
BA_ "SignalLongName" SG_ 1935 DTCI_WrnIndRqdSt_78F "Diagnostic Trouble Code Information Extended 78F : Warning Indicator Requested Status";
BA_ "VNSigAllNodes" SG_ 1935 DTCI_WrnIndRqdSt_78F 1;
BA_ "SignalType" SG_ 1935 DTCI_DTCFailType_78F "UNM";
BA_ "PacketOrder" SG_ 1935 DTCI_DTCFailType_78F 11;
BA_ "SignalLongName" SG_ 1935 DTCI_DTCFailType_78F "Diagnostic Trouble Code Information Extended 78F : Diagnostic Trouble Code Failure Type";
BA_ "VNSigAllNodes" SG_ 1935 DTCI_DTCFailType_78F 1;
BA_ "SignalType" SG_ 1935 DTCI_DTCNumber_78F "UNM";
BA_ "PacketOrder" SG_ 1935 DTCI_DTCNumber_78F 10;
BA_ "SignalLongName" SG_ 1935 DTCI_DTCNumber_78F "Diagnostic Trouble Code Information Extended 78F : Diagnostic Trouble Code Number";
BA_ "VNSigAllNodes" SG_ 1935 DTCI_DTCNumber_78F 1;
BA_ "SignalType" SG_ 1934 DTCI_CodeSupported_78E "BLN";
BA_ "PacketOrder" SG_ 1934 DTCI_CodeSupported_78E 19;
BA_ "SignalLongName" SG_ 1934 DTCI_CodeSupported_78E "Diagnostic Trouble Code Information Extended 78E : Code Supported";
BA_ "VNSigAllNodes" SG_ 1934 DTCI_CodeSupported_78E 1;
BA_ "SignalType" SG_ 1934 DTCI_CurrentStatus_78E "BLN";
BA_ "PacketOrder" SG_ 1934 DTCI_CurrentStatus_78E 18;
BA_ "SignalLongName" SG_ 1934 DTCI_CurrentStatus_78E "Diagnostic Trouble Code Information Extended 78E : Current Status";
BA_ "VNSigAllNodes" SG_ 1934 DTCI_CurrentStatus_78E 1;
BA_ "SignalType" SG_ 1934 DTCI_DTCFailType_78E "UNM";
BA_ "PacketOrder" SG_ 1934 DTCI_DTCFailType_78E 11;
BA_ "SignalLongName" SG_ 1934 DTCI_DTCFailType_78E "Diagnostic Trouble Code Information Extended 78E : Diagnostic Trouble Code Failure Type";
BA_ "VNSigAllNodes" SG_ 1934 DTCI_DTCFailType_78E 1;
BA_ "SignalType" SG_ 1934 DTCI_DTCFaultType_78E "ENM";
BA_ "PacketOrder" SG_ 1934 DTCI_DTCFaultType_78E 20;
BA_ "SignalLongName" SG_ 1934 DTCI_DTCFaultType_78E "Diagnostic Trouble Code Information Extended 78E : Diagnostic Trouble Code Fault Type";
BA_ "VNSigAllNodes" SG_ 1934 DTCI_DTCFaultType_78E 1;
BA_ "SignalType" SG_ 1934 DTCI_DTCNumber_78E "UNM";
BA_ "PacketOrder" SG_ 1934 DTCI_DTCNumber_78E 10;
BA_ "SignalLongName" SG_ 1934 DTCI_DTCNumber_78E "Diagnostic Trouble Code Information Extended 78E : Diagnostic Trouble Code Number";
BA_ "VNSigAllNodes" SG_ 1934 DTCI_DTCNumber_78E 1;
BA_ "SignalType" SG_ 1934 DTCI_DTCSource_78E "UNM";
BA_ "PacketOrder" SG_ 1934 DTCI_DTCSource_78E 9;
BA_ "SignalLongName" SG_ 1934 DTCI_DTCSource_78E "Diagnostic Trouble Code Information Extended 78E : Diagnostic Trouble Code Source";
BA_ "VNSigAllNodes" SG_ 1934 DTCI_DTCSource_78E 1;
BA_ "SignalType" SG_ 1934 DTCI_DTCTriggered_78E "BLN";
BA_ "PacketOrder" SG_ 1934 DTCI_DTCTriggered_78E 8;
BA_ "SignalLongName" SG_ 1934 DTCI_DTCTriggered_78E "Diagnostic Trouble Code Information Extended 78E : Diagnostic Trouble Code Triggered";
BA_ "VNSigAllNodes" SG_ 1934 DTCI_DTCTriggered_78E 1;
BA_ "SignalType" SG_ 1934 DTCI_HistStat_78E "BLN";
BA_ "PacketOrder" SG_ 1934 DTCI_HistStat_78E 15;
BA_ "SignalLongName" SG_ 1934 DTCI_HistStat_78E "Diagnostic Trouble Code Information Extended 78E : History Status";
BA_ "VNSigAllNodes" SG_ 1934 DTCI_HistStat_78E 1;
BA_ "SignalType" SG_ 1934 DTCI_TstFldCdClrdStat_78E "BLN";
BA_ "PacketOrder" SG_ 1934 DTCI_TstFldCdClrdStat_78E 16;
BA_ "SignalLongName" SG_ 1934 DTCI_TstFldCdClrdStat_78E "Diagnostic Trouble Code Information Extended 78E : Test Failed Since Code Cleared Status";
BA_ "VNSigAllNodes" SG_ 1934 DTCI_TstFldCdClrdStat_78E 1;
BA_ "SignalType" SG_ 1934 DTCI_TstFldPwrUpSt_78E "BLN";
BA_ "PacketOrder" SG_ 1934 DTCI_TstFldPwrUpSt_78E 13;
BA_ "SignalLongName" SG_ 1934 DTCI_TstFldPwrUpSt_78E "Diagnostic Trouble Code Information Extended 78E : Test Failed Since Power Up Status";
BA_ "VNSigAllNodes" SG_ 1934 DTCI_TstFldPwrUpSt_78E 1;
BA_ "SignalType" SG_ 1934 DTCI_TstNPsdCdClrdSt_78E "BLN";
BA_ "PacketOrder" SG_ 1934 DTCI_TstNPsdCdClrdSt_78E 17;
BA_ "SignalLongName" SG_ 1934 DTCI_TstNPsdCdClrdSt_78E "Diagnostic Trouble Code Information Extended 78E : Test Not Passed Since Code Cleared Status";
BA_ "VNSigAllNodes" SG_ 1934 DTCI_TstNPsdCdClrdSt_78E 1;
BA_ "SignalType" SG_ 1934 DTCI_TstNPsdPwrUpSt_78E "BLN";
BA_ "PacketOrder" SG_ 1934 DTCI_TstNPsdPwrUpSt_78E 14;
BA_ "SignalLongName" SG_ 1934 DTCI_TstNPsdPwrUpSt_78E "Diagnostic Trouble Code Information Extended 78E : Test Not Passed Since Power Up Status";
BA_ "VNSigAllNodes" SG_ 1934 DTCI_TstNPsdPwrUpSt_78E 1;
BA_ "SignalType" SG_ 1934 DTCIUnused1_78E "BLN";
BA_ "PacketOrder" SG_ 1934 DTCIUnused1_78E 1;
BA_ "SignalLongName" SG_ 1934 DTCIUnused1_78E "Diagnostic Trouble Code Information Extended 78E : Unused 1";
BA_ "VNSigAllNodes" SG_ 1934 DTCIUnused1_78E 1;
BA_ "SignalType" SG_ 1934 DTCIUnused2_78E "BLN";
BA_ "PacketOrder" SG_ 1934 DTCIUnused2_78E 2;
BA_ "SignalLongName" SG_ 1934 DTCIUnused2_78E "Diagnostic Trouble Code Information Extended 78E : Unused 2";
BA_ "VNSigAllNodes" SG_ 1934 DTCIUnused2_78E 1;
BA_ "SignalType" SG_ 1934 DTCIUnused3_78E "BLN";
BA_ "PacketOrder" SG_ 1934 DTCIUnused3_78E 3;
BA_ "SignalLongName" SG_ 1934 DTCIUnused3_78E "Diagnostic Trouble Code Information Extended 78E : Unused 3";
BA_ "VNSigAllNodes" SG_ 1934 DTCIUnused3_78E 1;
BA_ "SignalType" SG_ 1934 DTCIUnused4_78E "BLN";
BA_ "PacketOrder" SG_ 1934 DTCIUnused4_78E 4;
BA_ "SignalLongName" SG_ 1934 DTCIUnused4_78E "Diagnostic Trouble Code Information Extended 78E : Unused 4";
BA_ "VNSigAllNodes" SG_ 1934 DTCIUnused4_78E 1;
BA_ "SignalType" SG_ 1934 DTCIUnused5_78E "BLN";
BA_ "PacketOrder" SG_ 1934 DTCIUnused5_78E 5;
BA_ "SignalLongName" SG_ 1934 DTCIUnused5_78E "Diagnostic Trouble Code Information Extended 78E : Unused 5";
BA_ "VNSigAllNodes" SG_ 1934 DTCIUnused5_78E 1;
BA_ "SignalType" SG_ 1934 DTCIUnused6_78E "BLN";
BA_ "PacketOrder" SG_ 1934 DTCIUnused6_78E 6;
BA_ "SignalLongName" SG_ 1934 DTCIUnused6_78E "Diagnostic Trouble Code Information Extended 78E : Unused 6";
BA_ "VNSigAllNodes" SG_ 1934 DTCIUnused6_78E 1;
BA_ "SignalType" SG_ 1934 DTCIUnused7_78E "BLN";
BA_ "PacketOrder" SG_ 1934 DTCIUnused7_78E 7;
BA_ "SignalLongName" SG_ 1934 DTCIUnused7_78E "Diagnostic Trouble Code Information Extended 78E : Unused 7";
BA_ "VNSigAllNodes" SG_ 1934 DTCIUnused7_78E 1;
BA_ "SignalType" SG_ 1934 DTCI_WrnIndRqdSt_78E "BLN";
BA_ "PacketOrder" SG_ 1934 DTCI_WrnIndRqdSt_78E 12;
BA_ "SignalLongName" SG_ 1934 DTCI_WrnIndRqdSt_78E "Diagnostic Trouble Code Information Extended 78E : Warning Indicator Requested Status";
BA_ "VNSigAllNodes" SG_ 1934 DTCI_WrnIndRqdSt_78E 1;
BA_ "SignalType" SG_ 1933 DTCI_CodeSupported_78D "BLN";
BA_ "PacketOrder" SG_ 1933 DTCI_CodeSupported_78D 19;
BA_ "SignalLongName" SG_ 1933 DTCI_CodeSupported_78D "Diagnostic Trouble Code Information Extended 78D : Code Supported";
BA_ "VNSigAllNodes" SG_ 1933 DTCI_CodeSupported_78D 1;
BA_ "SignalType" SG_ 1933 DTCI_CurrentStatus_78D "BLN";
BA_ "PacketOrder" SG_ 1933 DTCI_CurrentStatus_78D 18;
BA_ "SignalLongName" SG_ 1933 DTCI_CurrentStatus_78D "Diagnostic Trouble Code Information Extended 78D : Current Status";
BA_ "VNSigAllNodes" SG_ 1933 DTCI_CurrentStatus_78D 1;
BA_ "SignalType" SG_ 1933 DTCI_DTCFailType_78D "UNM";
BA_ "PacketOrder" SG_ 1933 DTCI_DTCFailType_78D 11;
BA_ "SignalLongName" SG_ 1933 DTCI_DTCFailType_78D "Diagnostic Trouble Code Information Extended 78D : Diagnostic Trouble Code Failure Type";
BA_ "VNSigAllNodes" SG_ 1933 DTCI_DTCFailType_78D 1;
BA_ "SignalType" SG_ 1933 DTCI_DTCFaultType_78D "ENM";
BA_ "PacketOrder" SG_ 1933 DTCI_DTCFaultType_78D 20;
BA_ "SignalLongName" SG_ 1933 DTCI_DTCFaultType_78D "Diagnostic Trouble Code Information Extended 78D : Diagnostic Trouble Code Fault Type";
BA_ "VNSigAllNodes" SG_ 1933 DTCI_DTCFaultType_78D 1;
BA_ "SignalType" SG_ 1933 DTCI_DTCNumber_78D "UNM";
BA_ "PacketOrder" SG_ 1933 DTCI_DTCNumber_78D 10;
BA_ "SignalLongName" SG_ 1933 DTCI_DTCNumber_78D "Diagnostic Trouble Code Information Extended 78D : Diagnostic Trouble Code Number";
BA_ "VNSigAllNodes" SG_ 1933 DTCI_DTCNumber_78D 1;
BA_ "SignalType" SG_ 1933 DTCI_DTCSource_78D "UNM";
BA_ "PacketOrder" SG_ 1933 DTCI_DTCSource_78D 9;
BA_ "SignalLongName" SG_ 1933 DTCI_DTCSource_78D "Diagnostic Trouble Code Information Extended 78D : Diagnostic Trouble Code Source";
BA_ "VNSigAllNodes" SG_ 1933 DTCI_DTCSource_78D 1;
BA_ "SignalType" SG_ 1933 DTCI_DTCTriggered_78D "BLN";
BA_ "PacketOrder" SG_ 1933 DTCI_DTCTriggered_78D 8;
BA_ "SignalLongName" SG_ 1933 DTCI_DTCTriggered_78D "Diagnostic Trouble Code Information Extended 78D : Diagnostic Trouble Code Triggered";
BA_ "VNSigAllNodes" SG_ 1933 DTCI_DTCTriggered_78D 1;
BA_ "SignalType" SG_ 1933 DTCI_HistStat_78D "BLN";
BA_ "PacketOrder" SG_ 1933 DTCI_HistStat_78D 15;
BA_ "SignalLongName" SG_ 1933 DTCI_HistStat_78D "Diagnostic Trouble Code Information Extended 78D : History Status";
BA_ "VNSigAllNodes" SG_ 1933 DTCI_HistStat_78D 1;
BA_ "SignalType" SG_ 1933 DTCI_TstFldCdClrdStat_78D "BLN";
BA_ "PacketOrder" SG_ 1933 DTCI_TstFldCdClrdStat_78D 16;
BA_ "SignalLongName" SG_ 1933 DTCI_TstFldCdClrdStat_78D "Diagnostic Trouble Code Information Extended 78D : Test Failed Since Code Cleared Status";
BA_ "VNSigAllNodes" SG_ 1933 DTCI_TstFldCdClrdStat_78D 1;
BA_ "SignalType" SG_ 1933 DTCI_TstFldPwrUpSt_78D "BLN";
BA_ "PacketOrder" SG_ 1933 DTCI_TstFldPwrUpSt_78D 13;
BA_ "SignalLongName" SG_ 1933 DTCI_TstFldPwrUpSt_78D "Diagnostic Trouble Code Information Extended 78D : Test Failed Since Power Up Status";
BA_ "VNSigAllNodes" SG_ 1933 DTCI_TstFldPwrUpSt_78D 1;
BA_ "SignalType" SG_ 1933 DTCI_TstNPsdCdClrdSt_78D "BLN";
BA_ "PacketOrder" SG_ 1933 DTCI_TstNPsdCdClrdSt_78D 17;
BA_ "SignalLongName" SG_ 1933 DTCI_TstNPsdCdClrdSt_78D "Diagnostic Trouble Code Information Extended 78D : Test Not Passed Since Code Cleared Status";
BA_ "VNSigAllNodes" SG_ 1933 DTCI_TstNPsdCdClrdSt_78D 1;
BA_ "SignalType" SG_ 1933 DTCI_TstNPsdPwrUpSt_78D "BLN";
BA_ "PacketOrder" SG_ 1933 DTCI_TstNPsdPwrUpSt_78D 14;
BA_ "SignalLongName" SG_ 1933 DTCI_TstNPsdPwrUpSt_78D "Diagnostic Trouble Code Information Extended 78D : Test Not Passed Since Power Up Status";
BA_ "VNSigAllNodes" SG_ 1933 DTCI_TstNPsdPwrUpSt_78D 1;
BA_ "SignalType" SG_ 1933 DTCIUnused1_78D "BLN";
BA_ "PacketOrder" SG_ 1933 DTCIUnused1_78D 1;
BA_ "SignalLongName" SG_ 1933 DTCIUnused1_78D "Diagnostic Trouble Code Information Extended 78D : Unused 1";
BA_ "VNSigAllNodes" SG_ 1933 DTCIUnused1_78D 1;
BA_ "SignalType" SG_ 1933 DTCIUnused2_78D "BLN";
BA_ "PacketOrder" SG_ 1933 DTCIUnused2_78D 2;
BA_ "SignalLongName" SG_ 1933 DTCIUnused2_78D "Diagnostic Trouble Code Information Extended 78D : Unused 2";
BA_ "VNSigAllNodes" SG_ 1933 DTCIUnused2_78D 1;
BA_ "SignalType" SG_ 1933 DTCIUnused3_78D "BLN";
BA_ "PacketOrder" SG_ 1933 DTCIUnused3_78D 3;
BA_ "SignalLongName" SG_ 1933 DTCIUnused3_78D "Diagnostic Trouble Code Information Extended 78D : Unused 3";
BA_ "VNSigAllNodes" SG_ 1933 DTCIUnused3_78D 1;
BA_ "SignalType" SG_ 1933 DTCIUnused4_78D "BLN";
BA_ "PacketOrder" SG_ 1933 DTCIUnused4_78D 4;
BA_ "SignalLongName" SG_ 1933 DTCIUnused4_78D "Diagnostic Trouble Code Information Extended 78D : Unused 4";
BA_ "VNSigAllNodes" SG_ 1933 DTCIUnused4_78D 1;
BA_ "SignalType" SG_ 1933 DTCIUnused5_78D "BLN";
BA_ "PacketOrder" SG_ 1933 DTCIUnused5_78D 5;
BA_ "SignalLongName" SG_ 1933 DTCIUnused5_78D "Diagnostic Trouble Code Information Extended 78D : Unused 5";
BA_ "VNSigAllNodes" SG_ 1933 DTCIUnused5_78D 1;
BA_ "SignalType" SG_ 1933 DTCIUnused6_78D "BLN";
BA_ "PacketOrder" SG_ 1933 DTCIUnused6_78D 6;
BA_ "SignalLongName" SG_ 1933 DTCIUnused6_78D "Diagnostic Trouble Code Information Extended 78D : Unused 6";
BA_ "VNSigAllNodes" SG_ 1933 DTCIUnused6_78D 1;
BA_ "SignalType" SG_ 1933 DTCIUnused7_78D "BLN";
BA_ "PacketOrder" SG_ 1933 DTCIUnused7_78D 7;
BA_ "SignalLongName" SG_ 1933 DTCIUnused7_78D "Diagnostic Trouble Code Information Extended 78D : Unused 7";
BA_ "VNSigAllNodes" SG_ 1933 DTCIUnused7_78D 1;
BA_ "SignalType" SG_ 1933 DTCI_WrnIndRqdSt_78D "BLN";
BA_ "PacketOrder" SG_ 1933 DTCI_WrnIndRqdSt_78D 12;
BA_ "SignalLongName" SG_ 1933 DTCI_WrnIndRqdSt_78D "Diagnostic Trouble Code Information Extended 78D : Warning Indicator Requested Status";
BA_ "VNSigAllNodes" SG_ 1933 DTCI_WrnIndRqdSt_78D 1;
BA_ "SignalType" SG_ 1932 DTCI_CodeSupported_78C "BLN";
BA_ "PacketOrder" SG_ 1932 DTCI_CodeSupported_78C 19;
BA_ "SignalLongName" SG_ 1932 DTCI_CodeSupported_78C "Diagnostic Trouble Code Information Extended 78C : Code Supported";
BA_ "VNSigAllNodes" SG_ 1932 DTCI_CodeSupported_78C 1;
BA_ "SignalType" SG_ 1932 DTCI_CurrentStatus_78C "BLN";
BA_ "PacketOrder" SG_ 1932 DTCI_CurrentStatus_78C 18;
BA_ "SignalLongName" SG_ 1932 DTCI_CurrentStatus_78C "Diagnostic Trouble Code Information Extended 78C : Current Status";
BA_ "VNSigAllNodes" SG_ 1932 DTCI_CurrentStatus_78C 1;
BA_ "SignalType" SG_ 1932 DTCI_DTCFailType_78C "UNM";
BA_ "PacketOrder" SG_ 1932 DTCI_DTCFailType_78C 11;
BA_ "SignalLongName" SG_ 1932 DTCI_DTCFailType_78C "Diagnostic Trouble Code Information Extended 78C : Diagnostic Trouble Code Failure Type";
BA_ "VNSigAllNodes" SG_ 1932 DTCI_DTCFailType_78C 1;
BA_ "SignalType" SG_ 1932 DTCI_DTCFaultType_78C "ENM";
BA_ "PacketOrder" SG_ 1932 DTCI_DTCFaultType_78C 20;
BA_ "SignalLongName" SG_ 1932 DTCI_DTCFaultType_78C "Diagnostic Trouble Code Information Extended 78C : Diagnostic Trouble Code Fault Type";
BA_ "VNSigAllNodes" SG_ 1932 DTCI_DTCFaultType_78C 1;
BA_ "SignalType" SG_ 1932 DTCI_DTCNumber_78C "UNM";
BA_ "PacketOrder" SG_ 1932 DTCI_DTCNumber_78C 10;
BA_ "SignalLongName" SG_ 1932 DTCI_DTCNumber_78C "Diagnostic Trouble Code Information Extended 78C : Diagnostic Trouble Code Number";
BA_ "VNSigAllNodes" SG_ 1932 DTCI_DTCNumber_78C 1;
BA_ "SignalType" SG_ 1932 DTCI_DTCSource_78C "UNM";
BA_ "PacketOrder" SG_ 1932 DTCI_DTCSource_78C 9;
BA_ "SignalLongName" SG_ 1932 DTCI_DTCSource_78C "Diagnostic Trouble Code Information Extended 78C : Diagnostic Trouble Code Source";
BA_ "VNSigAllNodes" SG_ 1932 DTCI_DTCSource_78C 1;
BA_ "SignalType" SG_ 1932 DTCI_DTCTriggered_78C "BLN";
BA_ "PacketOrder" SG_ 1932 DTCI_DTCTriggered_78C 8;
BA_ "SignalLongName" SG_ 1932 DTCI_DTCTriggered_78C "Diagnostic Trouble Code Information Extended 78C : Diagnostic Trouble Code Triggered";
BA_ "VNSigAllNodes" SG_ 1932 DTCI_DTCTriggered_78C 1;
BA_ "SignalType" SG_ 1932 DTCI_HistStat_78C "BLN";
BA_ "PacketOrder" SG_ 1932 DTCI_HistStat_78C 15;
BA_ "SignalLongName" SG_ 1932 DTCI_HistStat_78C "Diagnostic Trouble Code Information Extended 78C : History Status";
BA_ "VNSigAllNodes" SG_ 1932 DTCI_HistStat_78C 1;
BA_ "SignalType" SG_ 1932 DTCI_TstFldCdClrdStat_78C "BLN";
BA_ "PacketOrder" SG_ 1932 DTCI_TstFldCdClrdStat_78C 16;
BA_ "SignalLongName" SG_ 1932 DTCI_TstFldCdClrdStat_78C "Diagnostic Trouble Code Information Extended 78C : Test Failed Since Code Cleared Status";
BA_ "VNSigAllNodes" SG_ 1932 DTCI_TstFldCdClrdStat_78C 1;
BA_ "SignalType" SG_ 1932 DTCI_TstFldPwrUpSt_78C "BLN";
BA_ "PacketOrder" SG_ 1932 DTCI_TstFldPwrUpSt_78C 14;
BA_ "SignalLongName" SG_ 1932 DTCI_TstFldPwrUpSt_78C "Diagnostic Trouble Code Information Extended 78C : Test Failed Since Power Up Status";
BA_ "VNSigAllNodes" SG_ 1932 DTCI_TstFldPwrUpSt_78C 1;
BA_ "SignalType" SG_ 1932 DTCI_TstNPsdCdClrdSt_78C "BLN";
BA_ "PacketOrder" SG_ 1932 DTCI_TstNPsdCdClrdSt_78C 17;
BA_ "SignalLongName" SG_ 1932 DTCI_TstNPsdCdClrdSt_78C "Diagnostic Trouble Code Information Extended 78C : Test Not Passed Since Code Cleared Status";
BA_ "VNSigAllNodes" SG_ 1932 DTCI_TstNPsdCdClrdSt_78C 1;
BA_ "SignalType" SG_ 1932 DTCI_TstNPsdPwrUpSt_78C "BLN";
BA_ "PacketOrder" SG_ 1932 DTCI_TstNPsdPwrUpSt_78C 13;
BA_ "SignalLongName" SG_ 1932 DTCI_TstNPsdPwrUpSt_78C "Diagnostic Trouble Code Information Extended 78C : Test Not Passed Since Power Up Status";
BA_ "VNSigAllNodes" SG_ 1932 DTCI_TstNPsdPwrUpSt_78C 1;
BA_ "SignalType" SG_ 1932 DTCIUnused1_78C "BLN";
BA_ "PacketOrder" SG_ 1932 DTCIUnused1_78C 1;
BA_ "SignalLongName" SG_ 1932 DTCIUnused1_78C "Diagnostic Trouble Code Information Extended 78C : Unused 1";
BA_ "VNSigAllNodes" SG_ 1932 DTCIUnused1_78C 1;
BA_ "SignalType" SG_ 1932 DTCIUnused2_78C "BLN";
BA_ "PacketOrder" SG_ 1932 DTCIUnused2_78C 2;
BA_ "SignalLongName" SG_ 1932 DTCIUnused2_78C "Diagnostic Trouble Code Information Extended 78C : Unused 2";
BA_ "VNSigAllNodes" SG_ 1932 DTCIUnused2_78C 1;
BA_ "SignalType" SG_ 1932 DTCIUnused3_78C "BLN";
BA_ "PacketOrder" SG_ 1932 DTCIUnused3_78C 3;
BA_ "SignalLongName" SG_ 1932 DTCIUnused3_78C "Diagnostic Trouble Code Information Extended 78C : Unused 3";
BA_ "VNSigAllNodes" SG_ 1932 DTCIUnused3_78C 1;
BA_ "SignalType" SG_ 1932 DTCIUnused4_78C "BLN";
BA_ "PacketOrder" SG_ 1932 DTCIUnused4_78C 4;
BA_ "SignalLongName" SG_ 1932 DTCIUnused4_78C "Diagnostic Trouble Code Information Extended 78C : Unused 4";
BA_ "VNSigAllNodes" SG_ 1932 DTCIUnused4_78C 1;
BA_ "SignalType" SG_ 1932 DTCIUnused5_78C "BLN";
BA_ "PacketOrder" SG_ 1932 DTCIUnused5_78C 5;
BA_ "SignalLongName" SG_ 1932 DTCIUnused5_78C "Diagnostic Trouble Code Information Extended 78C : Unused 5";
BA_ "VNSigAllNodes" SG_ 1932 DTCIUnused5_78C 1;
BA_ "SignalType" SG_ 1932 DTCIUnused6_78C "BLN";
BA_ "PacketOrder" SG_ 1932 DTCIUnused6_78C 6;
BA_ "SignalLongName" SG_ 1932 DTCIUnused6_78C "Diagnostic Trouble Code Information Extended 78C : Unused 6";
BA_ "VNSigAllNodes" SG_ 1932 DTCIUnused6_78C 1;
BA_ "SignalType" SG_ 1932 DTCIUnused7_78C "BLN";
BA_ "PacketOrder" SG_ 1932 DTCIUnused7_78C 7;
BA_ "SignalLongName" SG_ 1932 DTCIUnused7_78C "Diagnostic Trouble Code Information Extended 78C : Unused 7";
BA_ "VNSigAllNodes" SG_ 1932 DTCIUnused7_78C 1;
BA_ "SignalType" SG_ 1932 DTCI_WrnIndRqdSt_78C "BLN";
BA_ "PacketOrder" SG_ 1932 DTCI_WrnIndRqdSt_78C 12;
BA_ "SignalLongName" SG_ 1932 DTCI_WrnIndRqdSt_78C "Diagnostic Trouble Code Information Extended 78C : Warning Indicator Requested Status";
BA_ "VNSigAllNodes" SG_ 1932 DTCI_WrnIndRqdSt_78C 1;
BA_ "SignalType" SG_ 1931 DTCI_CodeSupported_78B "BLN";
BA_ "PacketOrder" SG_ 1931 DTCI_CodeSupported_78B 19;
BA_ "SignalLongName" SG_ 1931 DTCI_CodeSupported_78B "Diagnostic Trouble Code Information Extended 78B : Code Supported";
BA_ "VNSigAllNodes" SG_ 1931 DTCI_CodeSupported_78B 1;
BA_ "SignalType" SG_ 1931 DTCI_CurrentStatus_78B "BLN";
BA_ "PacketOrder" SG_ 1931 DTCI_CurrentStatus_78B 18;
BA_ "SignalLongName" SG_ 1931 DTCI_CurrentStatus_78B "Diagnostic Trouble Code Information Extended 78B : Current Status";
BA_ "VNSigAllNodes" SG_ 1931 DTCI_CurrentStatus_78B 1;
BA_ "SignalType" SG_ 1931 DTCI_DTCFailType_78B "UNM";
BA_ "PacketOrder" SG_ 1931 DTCI_DTCFailType_78B 11;
BA_ "SignalLongName" SG_ 1931 DTCI_DTCFailType_78B "Diagnostic Trouble Code Information Extended 78B : Diagnostic Trouble Code Failure Type";
BA_ "VNSigAllNodes" SG_ 1931 DTCI_DTCFailType_78B 1;
BA_ "SignalType" SG_ 1931 DTCI_DTCFaultType_78B "ENM";
BA_ "PacketOrder" SG_ 1931 DTCI_DTCFaultType_78B 20;
BA_ "SignalLongName" SG_ 1931 DTCI_DTCFaultType_78B "Diagnostic Trouble Code Information Extended 78B : Diagnostic Trouble Code Fault Type";
BA_ "VNSigAllNodes" SG_ 1931 DTCI_DTCFaultType_78B 1;
BA_ "SignalType" SG_ 1931 DTCI_DTCNumber_78B "UNM";
BA_ "PacketOrder" SG_ 1931 DTCI_DTCNumber_78B 10;
BA_ "SignalLongName" SG_ 1931 DTCI_DTCNumber_78B "Diagnostic Trouble Code Information Extended 78B : Diagnostic Trouble Code Number";
BA_ "VNSigAllNodes" SG_ 1931 DTCI_DTCNumber_78B 1;
BA_ "SignalType" SG_ 1931 DTCI_DTCSource_78B "UNM";
BA_ "PacketOrder" SG_ 1931 DTCI_DTCSource_78B 9;
BA_ "SignalLongName" SG_ 1931 DTCI_DTCSource_78B "Diagnostic Trouble Code Information Extended 78B : Diagnostic Trouble Code Source";
BA_ "VNSigAllNodes" SG_ 1931 DTCI_DTCSource_78B 1;
BA_ "SignalType" SG_ 1931 DTCI_DTCTriggered_78B "BLN";
BA_ "PacketOrder" SG_ 1931 DTCI_DTCTriggered_78B 8;
BA_ "SignalLongName" SG_ 1931 DTCI_DTCTriggered_78B "Diagnostic Trouble Code Information Extended 78B : Diagnostic Trouble Code Triggered";
BA_ "VNSigAllNodes" SG_ 1931 DTCI_DTCTriggered_78B 1;
BA_ "SignalType" SG_ 1931 DTCI_HistStat_78B "BLN";
BA_ "PacketOrder" SG_ 1931 DTCI_HistStat_78B 15;
BA_ "SignalLongName" SG_ 1931 DTCI_HistStat_78B "Diagnostic Trouble Code Information Extended 78B : History Status";
BA_ "VNSigAllNodes" SG_ 1931 DTCI_HistStat_78B 1;
BA_ "SignalType" SG_ 1931 DTCI_TstFldCdClrdStat_78B "BLN";
BA_ "PacketOrder" SG_ 1931 DTCI_TstFldCdClrdStat_78B 16;
BA_ "SignalLongName" SG_ 1931 DTCI_TstFldCdClrdStat_78B "Diagnostic Trouble Code Information Extended 78B : Test Failed Since Code Cleared Status";
BA_ "VNSigAllNodes" SG_ 1931 DTCI_TstFldCdClrdStat_78B 1;
BA_ "SignalType" SG_ 1931 DTCI_TstFldPwrUpSt_78B "BLN";
BA_ "PacketOrder" SG_ 1931 DTCI_TstFldPwrUpSt_78B 13;
BA_ "SignalLongName" SG_ 1931 DTCI_TstFldPwrUpSt_78B "Diagnostic Trouble Code Information Extended 78B : Test Failed Since Power Up Status";
BA_ "VNSigAllNodes" SG_ 1931 DTCI_TstFldPwrUpSt_78B 1;
BA_ "SignalType" SG_ 1931 DTCI_TstNPsdCdClrdSt_78B "BLN";
BA_ "PacketOrder" SG_ 1931 DTCI_TstNPsdCdClrdSt_78B 17;
BA_ "SignalLongName" SG_ 1931 DTCI_TstNPsdCdClrdSt_78B "Diagnostic Trouble Code Information Extended 78B : Test Not Passed Since Code Cleared Status";
BA_ "VNSigAllNodes" SG_ 1931 DTCI_TstNPsdCdClrdSt_78B 1;
BA_ "SignalType" SG_ 1931 DTCI_TstNPsdPwrUpSt_78B "BLN";
BA_ "PacketOrder" SG_ 1931 DTCI_TstNPsdPwrUpSt_78B 14;
BA_ "SignalLongName" SG_ 1931 DTCI_TstNPsdPwrUpSt_78B "Diagnostic Trouble Code Information Extended 78B : Test Not Passed Since Power Up Status";
BA_ "VNSigAllNodes" SG_ 1931 DTCI_TstNPsdPwrUpSt_78B 1;
BA_ "SignalType" SG_ 1931 DTCIUnused1_78B "BLN";
BA_ "PacketOrder" SG_ 1931 DTCIUnused1_78B 1;
BA_ "SignalLongName" SG_ 1931 DTCIUnused1_78B "Diagnostic Trouble Code Information Extended 78B : Unused 1";
BA_ "VNSigAllNodes" SG_ 1931 DTCIUnused1_78B 1;
BA_ "SignalType" SG_ 1931 DTCIUnused2_78B "BLN";
BA_ "PacketOrder" SG_ 1931 DTCIUnused2_78B 2;
BA_ "SignalLongName" SG_ 1931 DTCIUnused2_78B "Diagnostic Trouble Code Information Extended 78B : Unused 2";
BA_ "VNSigAllNodes" SG_ 1931 DTCIUnused2_78B 1;
BA_ "SignalType" SG_ 1931 DTCIUnused3_78B "BLN";
BA_ "PacketOrder" SG_ 1931 DTCIUnused3_78B 3;
BA_ "SignalLongName" SG_ 1931 DTCIUnused3_78B "Diagnostic Trouble Code Information Extended 78B : Unused 3";
BA_ "VNSigAllNodes" SG_ 1931 DTCIUnused3_78B 1;
BA_ "SignalType" SG_ 1931 DTCIUnused4_78B "BLN";
BA_ "PacketOrder" SG_ 1931 DTCIUnused4_78B 4;
BA_ "SignalLongName" SG_ 1931 DTCIUnused4_78B "Diagnostic Trouble Code Information Extended 78B : Unused 4";
BA_ "VNSigAllNodes" SG_ 1931 DTCIUnused4_78B 1;
BA_ "SignalType" SG_ 1931 DTCIUnused5_78B "BLN";
BA_ "PacketOrder" SG_ 1931 DTCIUnused5_78B 5;
BA_ "SignalLongName" SG_ 1931 DTCIUnused5_78B "Diagnostic Trouble Code Information Extended 78B : Unused 5";
BA_ "VNSigAllNodes" SG_ 1931 DTCIUnused5_78B 1;
BA_ "SignalType" SG_ 1931 DTCIUnused6_78B "BLN";
BA_ "PacketOrder" SG_ 1931 DTCIUnused6_78B 6;
BA_ "SignalLongName" SG_ 1931 DTCIUnused6_78B "Diagnostic Trouble Code Information Extended 78B : Unused 6";
BA_ "VNSigAllNodes" SG_ 1931 DTCIUnused6_78B 1;
BA_ "SignalType" SG_ 1931 DTCIUnused7_78B "BLN";
BA_ "PacketOrder" SG_ 1931 DTCIUnused7_78B 7;
BA_ "SignalLongName" SG_ 1931 DTCIUnused7_78B "Diagnostic Trouble Code Information Extended 78B : Unused 7";
BA_ "VNSigAllNodes" SG_ 1931 DTCIUnused7_78B 1;
BA_ "SignalType" SG_ 1931 DTCI_WrnIndRqdSt_78B "BLN";
BA_ "PacketOrder" SG_ 1931 DTCI_WrnIndRqdSt_78B 12;
BA_ "SignalLongName" SG_ 1931 DTCI_WrnIndRqdSt_78B "Diagnostic Trouble Code Information Extended 78B : Warning Indicator Requested Status";
BA_ "VNSigAllNodes" SG_ 1931 DTCI_WrnIndRqdSt_78B 1;
BA_ "SignalType" SG_ 1930 DTCI_CodeSupported_78A "BLN";
BA_ "PacketOrder" SG_ 1930 DTCI_CodeSupported_78A 19;
BA_ "SignalLongName" SG_ 1930 DTCI_CodeSupported_78A "Diagnostic Trouble Code Information Extended 78A : Code Supported";
BA_ "VNSigAllNodes" SG_ 1930 DTCI_CodeSupported_78A 1;
BA_ "SignalType" SG_ 1930 DTCI_CurrentStatus_78A "BLN";
BA_ "PacketOrder" SG_ 1930 DTCI_CurrentStatus_78A 18;
BA_ "SignalLongName" SG_ 1930 DTCI_CurrentStatus_78A "Diagnostic Trouble Code Information Extended 78A : Current Status";
BA_ "VNSigAllNodes" SG_ 1930 DTCI_CurrentStatus_78A 1;
BA_ "SignalType" SG_ 1930 DTCI_DTCFailType_78A "UNM";
BA_ "PacketOrder" SG_ 1930 DTCI_DTCFailType_78A 11;
BA_ "SignalLongName" SG_ 1930 DTCI_DTCFailType_78A "Diagnostic Trouble Code Information Extended 78A : Diagnostic Trouble Code Failure Type";
BA_ "VNSigAllNodes" SG_ 1930 DTCI_DTCFailType_78A 1;
BA_ "SignalType" SG_ 1930 DTCI_DTCFaultType_78A "ENM";
BA_ "PacketOrder" SG_ 1930 DTCI_DTCFaultType_78A 20;
BA_ "SignalLongName" SG_ 1930 DTCI_DTCFaultType_78A "Diagnostic Trouble Code Information Extended 78A : Diagnostic Trouble Code Fault Type";
BA_ "VNSigAllNodes" SG_ 1930 DTCI_DTCFaultType_78A 1;
BA_ "SignalType" SG_ 1930 DTCI_DTCNumber_78A "UNM";
BA_ "PacketOrder" SG_ 1930 DTCI_DTCNumber_78A 10;
BA_ "SignalLongName" SG_ 1930 DTCI_DTCNumber_78A "Diagnostic Trouble Code Information Extended 78A : Diagnostic Trouble Code Number";
BA_ "VNSigAllNodes" SG_ 1930 DTCI_DTCNumber_78A 1;
BA_ "SignalType" SG_ 1930 DTCI_DTCSource_78A "UNM";
BA_ "PacketOrder" SG_ 1930 DTCI_DTCSource_78A 9;
BA_ "SignalLongName" SG_ 1930 DTCI_DTCSource_78A "Diagnostic Trouble Code Information Extended 78A : Diagnostic Trouble Code Source";
BA_ "VNSigAllNodes" SG_ 1930 DTCI_DTCSource_78A 1;
BA_ "SignalType" SG_ 1930 DTCI_DTCTriggered_78A "BLN";
BA_ "PacketOrder" SG_ 1930 DTCI_DTCTriggered_78A 8;
BA_ "SignalLongName" SG_ 1930 DTCI_DTCTriggered_78A "Diagnostic Trouble Code Information Extended 78A : Diagnostic Trouble Code Triggered";
BA_ "VNSigAllNodes" SG_ 1930 DTCI_DTCTriggered_78A 1;
BA_ "SignalType" SG_ 1930 DTCI_HistStat_78A "BLN";
BA_ "PacketOrder" SG_ 1930 DTCI_HistStat_78A 15;
BA_ "SignalLongName" SG_ 1930 DTCI_HistStat_78A "Diagnostic Trouble Code Information Extended 78A : History Status";
BA_ "VNSigAllNodes" SG_ 1930 DTCI_HistStat_78A 1;
BA_ "SignalType" SG_ 1930 DTCI_TstFldCdClrdStat_78A "BLN";
BA_ "PacketOrder" SG_ 1930 DTCI_TstFldCdClrdStat_78A 16;
BA_ "SignalLongName" SG_ 1930 DTCI_TstFldCdClrdStat_78A "Diagnostic Trouble Code Information Extended 78A : Test Failed Since Code Cleared Status";
BA_ "VNSigAllNodes" SG_ 1930 DTCI_TstFldCdClrdStat_78A 1;
BA_ "SignalType" SG_ 1930 DTCI_TstFldPwrUpSt_78A "BLN";
BA_ "PacketOrder" SG_ 1930 DTCI_TstFldPwrUpSt_78A 13;
BA_ "SignalLongName" SG_ 1930 DTCI_TstFldPwrUpSt_78A "Diagnostic Trouble Code Information Extended 78A : Test Failed Since Power Up Status";
BA_ "VNSigAllNodes" SG_ 1930 DTCI_TstFldPwrUpSt_78A 1;
BA_ "SignalType" SG_ 1930 DTCI_TstNPsdCdClrdSt_78A "BLN";
BA_ "PacketOrder" SG_ 1930 DTCI_TstNPsdCdClrdSt_78A 17;
BA_ "SignalLongName" SG_ 1930 DTCI_TstNPsdCdClrdSt_78A "Diagnostic Trouble Code Information Extended 78A : Test Not Passed Since Code Cleared Status";
BA_ "VNSigAllNodes" SG_ 1930 DTCI_TstNPsdCdClrdSt_78A 1;
BA_ "SignalType" SG_ 1930 DTCI_TstNPsdPwrUpSt_78A "BLN";
BA_ "PacketOrder" SG_ 1930 DTCI_TstNPsdPwrUpSt_78A 14;
BA_ "SignalLongName" SG_ 1930 DTCI_TstNPsdPwrUpSt_78A "Diagnostic Trouble Code Information Extended 78A : Test Not Passed Since Power Up Status";
BA_ "VNSigAllNodes" SG_ 1930 DTCI_TstNPsdPwrUpSt_78A 1;
BA_ "SignalType" SG_ 1930 DTCIUnused1_78A "BLN";
BA_ "PacketOrder" SG_ 1930 DTCIUnused1_78A 1;
BA_ "SignalLongName" SG_ 1930 DTCIUnused1_78A "Diagnostic Trouble Code Information Extended 78A : Unused 1";
BA_ "VNSigAllNodes" SG_ 1930 DTCIUnused1_78A 1;
BA_ "SignalType" SG_ 1930 DTCIUnused2_78A "BLN";
BA_ "PacketOrder" SG_ 1930 DTCIUnused2_78A 2;
BA_ "SignalLongName" SG_ 1930 DTCIUnused2_78A "Diagnostic Trouble Code Information Extended 78A : Unused 2";
BA_ "VNSigAllNodes" SG_ 1930 DTCIUnused2_78A 1;
BA_ "SignalType" SG_ 1930 DTCIUnused3_78A "BLN";
BA_ "PacketOrder" SG_ 1930 DTCIUnused3_78A 3;
BA_ "SignalLongName" SG_ 1930 DTCIUnused3_78A "Diagnostic Trouble Code Information Extended 78A : Unused 3";
BA_ "VNSigAllNodes" SG_ 1930 DTCIUnused3_78A 1;
BA_ "SignalType" SG_ 1930 DTCIUnused4_78A "BLN";
BA_ "PacketOrder" SG_ 1930 DTCIUnused4_78A 4;
BA_ "SignalLongName" SG_ 1930 DTCIUnused4_78A "Diagnostic Trouble Code Information Extended 78A : Unused 4";
BA_ "VNSigAllNodes" SG_ 1930 DTCIUnused4_78A 1;
BA_ "SignalType" SG_ 1930 DTCIUnused5_78A "BLN";
BA_ "PacketOrder" SG_ 1930 DTCIUnused5_78A 5;
BA_ "SignalLongName" SG_ 1930 DTCIUnused5_78A "Diagnostic Trouble Code Information Extended 78A : Unused 5";
BA_ "VNSigAllNodes" SG_ 1930 DTCIUnused5_78A 1;
BA_ "SignalType" SG_ 1930 DTCIUnused6_78A "BLN";
BA_ "PacketOrder" SG_ 1930 DTCIUnused6_78A 6;
BA_ "SignalLongName" SG_ 1930 DTCIUnused6_78A "Diagnostic Trouble Code Information Extended 78A : Unused 6";
BA_ "VNSigAllNodes" SG_ 1930 DTCIUnused6_78A 1;
BA_ "SignalType" SG_ 1930 DTCIUnused7_78A "BLN";
BA_ "PacketOrder" SG_ 1930 DTCIUnused7_78A 7;
BA_ "SignalLongName" SG_ 1930 DTCIUnused7_78A "Diagnostic Trouble Code Information Extended 78A : Unused 7";
BA_ "VNSigAllNodes" SG_ 1930 DTCIUnused7_78A 1;
BA_ "SignalType" SG_ 1930 DTCI_WrnIndRqdSt_78A "BLN";
BA_ "PacketOrder" SG_ 1930 DTCI_WrnIndRqdSt_78A 12;
BA_ "SignalLongName" SG_ 1930 DTCI_WrnIndRqdSt_78A "Diagnostic Trouble Code Information Extended 78A : Warning Indicator Requested Status";
BA_ "VNSigAllNodes" SG_ 1930 DTCI_WrnIndRqdSt_78A 1;
BA_ "SignalType" SG_ 1929 DTCI_CodeSupported_789 "BLN";
BA_ "PacketOrder" SG_ 1929 DTCI_CodeSupported_789 19;
BA_ "SignalLongName" SG_ 1929 DTCI_CodeSupported_789 "Diagnostic Trouble Code Information Extended 789 : Code Supported";
BA_ "VNSigAllNodes" SG_ 1929 DTCI_CodeSupported_789 1;
BA_ "SignalType" SG_ 1929 DTCI_CurrentStatus_789 "BLN";
BA_ "PacketOrder" SG_ 1929 DTCI_CurrentStatus_789 18;
BA_ "SignalLongName" SG_ 1929 DTCI_CurrentStatus_789 "Diagnostic Trouble Code Information Extended 789 : Current Status";
BA_ "VNSigAllNodes" SG_ 1929 DTCI_CurrentStatus_789 1;
BA_ "SignalType" SG_ 1929 DTCI_DTCFailType_789 "UNM";
BA_ "PacketOrder" SG_ 1929 DTCI_DTCFailType_789 11;
BA_ "SignalLongName" SG_ 1929 DTCI_DTCFailType_789 "Diagnostic Trouble Code Information Extended 789 : Diagnostic Trouble Code Failure Type";
BA_ "VNSigAllNodes" SG_ 1929 DTCI_DTCFailType_789 1;
BA_ "SignalType" SG_ 1929 DTCI_DTCFaultType_789 "ENM";
BA_ "PacketOrder" SG_ 1929 DTCI_DTCFaultType_789 20;
BA_ "SignalLongName" SG_ 1929 DTCI_DTCFaultType_789 "Diagnostic Trouble Code Information Extended 789 : Diagnostic Trouble Code Fault Type";
BA_ "VNSigAllNodes" SG_ 1929 DTCI_DTCFaultType_789 1;
BA_ "SignalType" SG_ 1929 DTCI_DTCNumber_789 "UNM";
BA_ "PacketOrder" SG_ 1929 DTCI_DTCNumber_789 10;
BA_ "SignalLongName" SG_ 1929 DTCI_DTCNumber_789 "Diagnostic Trouble Code Information Extended 789 : Diagnostic Trouble Code Number";
BA_ "VNSigAllNodes" SG_ 1929 DTCI_DTCNumber_789 1;
BA_ "SignalType" SG_ 1929 DTCI_DTCSource_789 "UNM";
BA_ "PacketOrder" SG_ 1929 DTCI_DTCSource_789 9;
BA_ "SignalLongName" SG_ 1929 DTCI_DTCSource_789 "Diagnostic Trouble Code Information Extended 789 : Diagnostic Trouble Code Source";
BA_ "VNSigAllNodes" SG_ 1929 DTCI_DTCSource_789 1;
BA_ "SignalType" SG_ 1929 DTCI_DTCTriggered_789 "BLN";
BA_ "PacketOrder" SG_ 1929 DTCI_DTCTriggered_789 8;
BA_ "SignalLongName" SG_ 1929 DTCI_DTCTriggered_789 "Diagnostic Trouble Code Information Extended 789 : Diagnostic Trouble Code Triggered";
BA_ "VNSigAllNodes" SG_ 1929 DTCI_DTCTriggered_789 1;
BA_ "SignalType" SG_ 1929 DTCI_HistStat_789 "BLN";
BA_ "PacketOrder" SG_ 1929 DTCI_HistStat_789 15;
BA_ "SignalLongName" SG_ 1929 DTCI_HistStat_789 "Diagnostic Trouble Code Information Extended 789 : History Status";
BA_ "VNSigAllNodes" SG_ 1929 DTCI_HistStat_789 1;
BA_ "SignalType" SG_ 1929 DTCI_TstFldCdClrdStat_789 "BLN";
BA_ "PacketOrder" SG_ 1929 DTCI_TstFldCdClrdStat_789 16;
BA_ "SignalLongName" SG_ 1929 DTCI_TstFldCdClrdStat_789 "Diagnostic Trouble Code Information Extended 789 : Test Failed Since Code Cleared Status";
BA_ "VNSigAllNodes" SG_ 1929 DTCI_TstFldCdClrdStat_789 1;
BA_ "SignalType" SG_ 1929 DTCI_TstFldPwrUpSt_789 "BLN";
BA_ "PacketOrder" SG_ 1929 DTCI_TstFldPwrUpSt_789 13;
BA_ "SignalLongName" SG_ 1929 DTCI_TstFldPwrUpSt_789 "Diagnostic Trouble Code Information Extended 789 : Test Failed Since Power Up Status";
BA_ "VNSigAllNodes" SG_ 1929 DTCI_TstFldPwrUpSt_789 1;
BA_ "SignalType" SG_ 1929 DTCI_TstNPsdCdClrdSt_789 "BLN";
BA_ "PacketOrder" SG_ 1929 DTCI_TstNPsdCdClrdSt_789 17;
BA_ "SignalLongName" SG_ 1929 DTCI_TstNPsdCdClrdSt_789 "Diagnostic Trouble Code Information Extended 789 : Test Not Passed Since Code Cleared Status";
BA_ "VNSigAllNodes" SG_ 1929 DTCI_TstNPsdCdClrdSt_789 1;
BA_ "SignalType" SG_ 1929 DTCI_TstNPsdPwrUpSt_789 "BLN";
BA_ "PacketOrder" SG_ 1929 DTCI_TstNPsdPwrUpSt_789 14;
BA_ "SignalLongName" SG_ 1929 DTCI_TstNPsdPwrUpSt_789 "Diagnostic Trouble Code Information Extended 789 : Test Not Passed Since Power Up Status";
BA_ "VNSigAllNodes" SG_ 1929 DTCI_TstNPsdPwrUpSt_789 1;
BA_ "SignalType" SG_ 1929 DTCIUnused1_789 "BLN";
BA_ "PacketOrder" SG_ 1929 DTCIUnused1_789 1;
BA_ "SignalLongName" SG_ 1929 DTCIUnused1_789 "Diagnostic Trouble Code Information Extended 789 : Unused 1";
BA_ "VNSigAllNodes" SG_ 1929 DTCIUnused1_789 1;
BA_ "SignalType" SG_ 1929 DTCIUnused2_789 "BLN";
BA_ "PacketOrder" SG_ 1929 DTCIUnused2_789 2;
BA_ "SignalLongName" SG_ 1929 DTCIUnused2_789 "Diagnostic Trouble Code Information Extended 789 : Unused 2";
BA_ "VNSigAllNodes" SG_ 1929 DTCIUnused2_789 1;
BA_ "SignalType" SG_ 1929 DTCIUnused3_789 "BLN";
BA_ "PacketOrder" SG_ 1929 DTCIUnused3_789 3;
BA_ "SignalLongName" SG_ 1929 DTCIUnused3_789 "Diagnostic Trouble Code Information Extended 789 : Unused 3";
BA_ "VNSigAllNodes" SG_ 1929 DTCIUnused3_789 1;
BA_ "SignalType" SG_ 1929 DTCIUnused4_789 "BLN";
BA_ "PacketOrder" SG_ 1929 DTCIUnused4_789 4;
BA_ "SignalLongName" SG_ 1929 DTCIUnused4_789 "Diagnostic Trouble Code Information Extended 789 : Unused 4";
BA_ "VNSigAllNodes" SG_ 1929 DTCIUnused4_789 1;
BA_ "SignalType" SG_ 1929 DTCIUnused5_789 "BLN";
BA_ "PacketOrder" SG_ 1929 DTCIUnused5_789 5;
BA_ "SignalLongName" SG_ 1929 DTCIUnused5_789 "Diagnostic Trouble Code Information Extended 789 : Unused 5";
BA_ "VNSigAllNodes" SG_ 1929 DTCIUnused5_789 1;
BA_ "SignalType" SG_ 1929 DTCIUnused6_789 "BLN";
BA_ "PacketOrder" SG_ 1929 DTCIUnused6_789 6;
BA_ "SignalLongName" SG_ 1929 DTCIUnused6_789 "Diagnostic Trouble Code Information Extended 789 : Unused 6";
BA_ "VNSigAllNodes" SG_ 1929 DTCIUnused6_789 1;
BA_ "SignalType" SG_ 1929 DTCIUnused7_789 "BLN";
BA_ "PacketOrder" SG_ 1929 DTCIUnused7_789 7;
BA_ "SignalLongName" SG_ 1929 DTCIUnused7_789 "Diagnostic Trouble Code Information Extended 789 : Unused 7";
BA_ "VNSigAllNodes" SG_ 1929 DTCIUnused7_789 1;
BA_ "SignalType" SG_ 1929 DTCI_WrnIndRqdSt_789 "BLN";
BA_ "PacketOrder" SG_ 1929 DTCI_WrnIndRqdSt_789 12;
BA_ "SignalLongName" SG_ 1929 DTCI_WrnIndRqdSt_789 "Diagnostic Trouble Code Information Extended 789 : Warning Indicator Requested Status";
BA_ "VNSigAllNodes" SG_ 1929 DTCI_WrnIndRqdSt_789 1;
BA_ "SignalType" SG_ 1928 DTCI_CodeSupported_788 "BLN";
BA_ "PacketOrder" SG_ 1928 DTCI_CodeSupported_788 19;
BA_ "SignalLongName" SG_ 1928 DTCI_CodeSupported_788 "Diagnostic Trouble Code Information Extended 788 : Code Supported";
BA_ "VNSigAllNodes" SG_ 1928 DTCI_CodeSupported_788 1;
BA_ "SignalType" SG_ 1928 DTCI_CurrentStatus_788 "BLN";
BA_ "PacketOrder" SG_ 1928 DTCI_CurrentStatus_788 18;
BA_ "SignalLongName" SG_ 1928 DTCI_CurrentStatus_788 "Diagnostic Trouble Code Information Extended 788 : Current Status";
BA_ "VNSigAllNodes" SG_ 1928 DTCI_CurrentStatus_788 1;
BA_ "SignalType" SG_ 1928 DTCI_DTCFailType_788 "UNM";
BA_ "PacketOrder" SG_ 1928 DTCI_DTCFailType_788 11;
BA_ "SignalLongName" SG_ 1928 DTCI_DTCFailType_788 "Diagnostic Trouble Code Information Extended 788 : Diagnostic Trouble Code Failure Type";
BA_ "VNSigAllNodes" SG_ 1928 DTCI_DTCFailType_788 1;
BA_ "SignalType" SG_ 1928 DTCI_DTCFaultType_788 "ENM";
BA_ "PacketOrder" SG_ 1928 DTCI_DTCFaultType_788 20;
BA_ "SignalLongName" SG_ 1928 DTCI_DTCFaultType_788 "Diagnostic Trouble Code Information Extended 788 : Diagnostic Trouble Code Fault Type";
BA_ "VNSigAllNodes" SG_ 1928 DTCI_DTCFaultType_788 1;
BA_ "SignalType" SG_ 1928 DTCI_DTCNumber_788 "UNM";
BA_ "PacketOrder" SG_ 1928 DTCI_DTCNumber_788 10;
BA_ "SignalLongName" SG_ 1928 DTCI_DTCNumber_788 "Diagnostic Trouble Code Information Extended 788 : Diagnostic Trouble Code Number";
BA_ "VNSigAllNodes" SG_ 1928 DTCI_DTCNumber_788 1;
BA_ "SignalType" SG_ 1928 DTCI_DTCSource_788 "UNM";
BA_ "PacketOrder" SG_ 1928 DTCI_DTCSource_788 9;
BA_ "SignalLongName" SG_ 1928 DTCI_DTCSource_788 "Diagnostic Trouble Code Information Extended 788 : Diagnostic Trouble Code Source";
BA_ "VNSigAllNodes" SG_ 1928 DTCI_DTCSource_788 1;
BA_ "SignalType" SG_ 1928 DTCI_DTCTriggered_788 "BLN";
BA_ "PacketOrder" SG_ 1928 DTCI_DTCTriggered_788 8;
BA_ "SignalLongName" SG_ 1928 DTCI_DTCTriggered_788 "Diagnostic Trouble Code Information Extended 788 : Diagnostic Trouble Code Triggered";
BA_ "VNSigAllNodes" SG_ 1928 DTCI_DTCTriggered_788 1;
BA_ "SignalType" SG_ 1928 DTCI_HistStat_788 "BLN";
BA_ "PacketOrder" SG_ 1928 DTCI_HistStat_788 15;
BA_ "SignalLongName" SG_ 1928 DTCI_HistStat_788 "Diagnostic Trouble Code Information Extended 788 : History Status";
BA_ "VNSigAllNodes" SG_ 1928 DTCI_HistStat_788 1;
BA_ "SignalType" SG_ 1928 DTCI_TstFldCdClrdStat_788 "BLN";
BA_ "PacketOrder" SG_ 1928 DTCI_TstFldCdClrdStat_788 17;
BA_ "SignalLongName" SG_ 1928 DTCI_TstFldCdClrdStat_788 "Diagnostic Trouble Code Information Extended 788 : Test Failed Since Code Cleared Status";
BA_ "VNSigAllNodes" SG_ 1928 DTCI_TstFldCdClrdStat_788 1;
BA_ "SignalType" SG_ 1928 DTCI_TstFldPwrUpSt_788 "BLN";
BA_ "PacketOrder" SG_ 1928 DTCI_TstFldPwrUpSt_788 13;
BA_ "SignalLongName" SG_ 1928 DTCI_TstFldPwrUpSt_788 "Diagnostic Trouble Code Information Extended 788 : Test Failed Since Power Up Status";
BA_ "VNSigAllNodes" SG_ 1928 DTCI_TstFldPwrUpSt_788 1;
BA_ "SignalType" SG_ 1928 DTCI_TstNPsdCdClrdSt_788 "BLN";
BA_ "PacketOrder" SG_ 1928 DTCI_TstNPsdCdClrdSt_788 16;
BA_ "SignalLongName" SG_ 1928 DTCI_TstNPsdCdClrdSt_788 "Diagnostic Trouble Code Information Extended 788 : Test Not Passed Since Code Cleared Status";
BA_ "VNSigAllNodes" SG_ 1928 DTCI_TstNPsdCdClrdSt_788 1;
BA_ "SignalType" SG_ 1928 DTCI_TstNPsdPwrUpSt_788 "BLN";
BA_ "PacketOrder" SG_ 1928 DTCI_TstNPsdPwrUpSt_788 14;
BA_ "SignalLongName" SG_ 1928 DTCI_TstNPsdPwrUpSt_788 "Diagnostic Trouble Code Information Extended 788 : Test Not Passed Since Power Up Status";
BA_ "VNSigAllNodes" SG_ 1928 DTCI_TstNPsdPwrUpSt_788 1;
BA_ "SignalType" SG_ 1928 DTCIUnused1_788 "BLN";
BA_ "PacketOrder" SG_ 1928 DTCIUnused1_788 1;
BA_ "SignalLongName" SG_ 1928 DTCIUnused1_788 "Diagnostic Trouble Code Information Extended 788 : Unused 1";
BA_ "VNSigAllNodes" SG_ 1928 DTCIUnused1_788 1;
BA_ "SignalType" SG_ 1928 DTCIUnused2_788 "BLN";
BA_ "PacketOrder" SG_ 1928 DTCIUnused2_788 2;
BA_ "SignalLongName" SG_ 1928 DTCIUnused2_788 "Diagnostic Trouble Code Information Extended 788 : Unused 2";
BA_ "VNSigAllNodes" SG_ 1928 DTCIUnused2_788 1;
BA_ "SignalType" SG_ 1928 DTCIUnused3_788 "BLN";
BA_ "PacketOrder" SG_ 1928 DTCIUnused3_788 3;
BA_ "SignalLongName" SG_ 1928 DTCIUnused3_788 "Diagnostic Trouble Code Information Extended 788 : Unused 3";
BA_ "VNSigAllNodes" SG_ 1928 DTCIUnused3_788 1;
BA_ "SignalType" SG_ 1928 DTCIUnused4_788 "BLN";
BA_ "PacketOrder" SG_ 1928 DTCIUnused4_788 4;
BA_ "SignalLongName" SG_ 1928 DTCIUnused4_788 "Diagnostic Trouble Code Information Extended 788 : Unused 4";
BA_ "VNSigAllNodes" SG_ 1928 DTCIUnused4_788 1;
BA_ "SignalType" SG_ 1928 DTCIUnused5_788 "BLN";
BA_ "PacketOrder" SG_ 1928 DTCIUnused5_788 5;
BA_ "SignalLongName" SG_ 1928 DTCIUnused5_788 "Diagnostic Trouble Code Information Extended 788 : Unused 5";
BA_ "VNSigAllNodes" SG_ 1928 DTCIUnused5_788 1;
BA_ "SignalType" SG_ 1928 DTCIUnused6_788 "BLN";
BA_ "PacketOrder" SG_ 1928 DTCIUnused6_788 6;
BA_ "SignalLongName" SG_ 1928 DTCIUnused6_788 "Diagnostic Trouble Code Information Extended 788 : Unused 6";
BA_ "VNSigAllNodes" SG_ 1928 DTCIUnused6_788 1;
BA_ "SignalType" SG_ 1928 DTCIUnused7_788 "BLN";
BA_ "PacketOrder" SG_ 1928 DTCIUnused7_788 7;
BA_ "SignalLongName" SG_ 1928 DTCIUnused7_788 "Diagnostic Trouble Code Information Extended 788 : Unused 7";
BA_ "VNSigAllNodes" SG_ 1928 DTCIUnused7_788 1;
BA_ "SignalType" SG_ 1928 DTCI_WrnIndRqdSt_788 "BLN";
BA_ "PacketOrder" SG_ 1928 DTCI_WrnIndRqdSt_788 12;
BA_ "SignalLongName" SG_ 1928 DTCI_WrnIndRqdSt_788 "Diagnostic Trouble Code Information Extended 788 : Warning Indicator Requested Status";
BA_ "VNSigAllNodes" SG_ 1928 DTCI_WrnIndRqdSt_788 1;
BA_ "SignalType" SG_ 1927 DTCI_CodeSupported_787 "BLN";
BA_ "PacketOrder" SG_ 1927 DTCI_CodeSupported_787 19;
BA_ "SignalLongName" SG_ 1927 DTCI_CodeSupported_787 "Diagnostic Trouble Code Information Extended 787 : Code Supported";
BA_ "VNSigAllNodes" SG_ 1927 DTCI_CodeSupported_787 1;
BA_ "SignalType" SG_ 1927 DTCI_CurrentStatus_787 "BLN";
BA_ "PacketOrder" SG_ 1927 DTCI_CurrentStatus_787 18;
BA_ "SignalLongName" SG_ 1927 DTCI_CurrentStatus_787 "Diagnostic Trouble Code Information Extended 787 : Current Status";
BA_ "VNSigAllNodes" SG_ 1927 DTCI_CurrentStatus_787 1;
BA_ "SignalType" SG_ 1927 DTCI_DTCFailType_787 "UNM";
BA_ "PacketOrder" SG_ 1927 DTCI_DTCFailType_787 11;
BA_ "SignalLongName" SG_ 1927 DTCI_DTCFailType_787 "Diagnostic Trouble Code Information Extended 787 : Diagnostic Trouble Code Failure Type";
BA_ "VNSigAllNodes" SG_ 1927 DTCI_DTCFailType_787 1;
BA_ "SignalType" SG_ 1927 DTCI_DTCFaultType_787 "ENM";
BA_ "PacketOrder" SG_ 1927 DTCI_DTCFaultType_787 20;
BA_ "SignalLongName" SG_ 1927 DTCI_DTCFaultType_787 "Diagnostic Trouble Code Information Extended 787 : Diagnostic Trouble Code Fault Type";
BA_ "VNSigAllNodes" SG_ 1927 DTCI_DTCFaultType_787 1;
BA_ "SignalType" SG_ 1927 DTCI_DTCNumber_787 "UNM";
BA_ "PacketOrder" SG_ 1927 DTCI_DTCNumber_787 10;
BA_ "SignalLongName" SG_ 1927 DTCI_DTCNumber_787 "Diagnostic Trouble Code Information Extended 787 : Diagnostic Trouble Code Number";
BA_ "VNSigAllNodes" SG_ 1927 DTCI_DTCNumber_787 1;
BA_ "SignalType" SG_ 1927 DTCI_DTCSource_787 "UNM";
BA_ "PacketOrder" SG_ 1927 DTCI_DTCSource_787 9;
BA_ "SignalLongName" SG_ 1927 DTCI_DTCSource_787 "Diagnostic Trouble Code Information Extended 787 : Diagnostic Trouble Code Source";
BA_ "VNSigAllNodes" SG_ 1927 DTCI_DTCSource_787 1;
BA_ "SignalType" SG_ 1927 DTCI_DTCTriggered_787 "BLN";
BA_ "PacketOrder" SG_ 1927 DTCI_DTCTriggered_787 8;
BA_ "SignalLongName" SG_ 1927 DTCI_DTCTriggered_787 "Diagnostic Trouble Code Information Extended 787 : Diagnostic Trouble Code Triggered";
BA_ "VNSigAllNodes" SG_ 1927 DTCI_DTCTriggered_787 1;
BA_ "SignalType" SG_ 1927 DTCI_HistStat_787 "BLN";
BA_ "PacketOrder" SG_ 1927 DTCI_HistStat_787 15;
BA_ "SignalLongName" SG_ 1927 DTCI_HistStat_787 "Diagnostic Trouble Code Information Extended 787 : History Status";
BA_ "VNSigAllNodes" SG_ 1927 DTCI_HistStat_787 1;
BA_ "SignalType" SG_ 1927 DTCI_TstFldCdClrdStat_787 "BLN";
BA_ "PacketOrder" SG_ 1927 DTCI_TstFldCdClrdStat_787 16;
BA_ "SignalLongName" SG_ 1927 DTCI_TstFldCdClrdStat_787 "Diagnostic Trouble Code Information Extended 787 : Test Failed Since Code Cleared Status";
BA_ "VNSigAllNodes" SG_ 1927 DTCI_TstFldCdClrdStat_787 1;
BA_ "SignalType" SG_ 1927 DTCI_TstFldPwrUpSt_787 "BLN";
BA_ "PacketOrder" SG_ 1927 DTCI_TstFldPwrUpSt_787 13;
BA_ "SignalLongName" SG_ 1927 DTCI_TstFldPwrUpSt_787 "Diagnostic Trouble Code Information Extended 787 : Test Failed Since Power Up Status";
BA_ "VNSigAllNodes" SG_ 1927 DTCI_TstFldPwrUpSt_787 1;
BA_ "SignalType" SG_ 1927 DTCI_TstNPsdCdClrdSt_787 "BLN";
BA_ "PacketOrder" SG_ 1927 DTCI_TstNPsdCdClrdSt_787 17;
BA_ "SignalLongName" SG_ 1927 DTCI_TstNPsdCdClrdSt_787 "Diagnostic Trouble Code Information Extended 787 : Test Not Passed Since Code Cleared Status";
BA_ "VNSigAllNodes" SG_ 1927 DTCI_TstNPsdCdClrdSt_787 1;
BA_ "SignalType" SG_ 1927 DTCI_TstNPsdPwrUpSt_787 "BLN";
BA_ "PacketOrder" SG_ 1927 DTCI_TstNPsdPwrUpSt_787 14;
BA_ "SignalLongName" SG_ 1927 DTCI_TstNPsdPwrUpSt_787 "Diagnostic Trouble Code Information Extended 787 : Test Not Passed Since Power Up Status";
BA_ "VNSigAllNodes" SG_ 1927 DTCI_TstNPsdPwrUpSt_787 1;
BA_ "SignalType" SG_ 1927 DTCIUnused1_787 "BLN";
BA_ "PacketOrder" SG_ 1927 DTCIUnused1_787 1;
BA_ "SignalLongName" SG_ 1927 DTCIUnused1_787 "Diagnostic Trouble Code Information Extended 787 : Unused 1";
BA_ "VNSigAllNodes" SG_ 1927 DTCIUnused1_787 1;
BA_ "SignalType" SG_ 1927 DTCIUnused2_787 "BLN";
BA_ "PacketOrder" SG_ 1927 DTCIUnused2_787 2;
BA_ "SignalLongName" SG_ 1927 DTCIUnused2_787 "Diagnostic Trouble Code Information Extended 787 : Unused 2";
BA_ "VNSigAllNodes" SG_ 1927 DTCIUnused2_787 1;
BA_ "SignalType" SG_ 1927 DTCIUnused3_787 "BLN";
BA_ "PacketOrder" SG_ 1927 DTCIUnused3_787 3;
BA_ "SignalLongName" SG_ 1927 DTCIUnused3_787 "Diagnostic Trouble Code Information Extended 787 : Unused 3";
BA_ "VNSigAllNodes" SG_ 1927 DTCIUnused3_787 1;
BA_ "SignalType" SG_ 1927 DTCIUnused4_787 "BLN";
BA_ "PacketOrder" SG_ 1927 DTCIUnused4_787 4;
BA_ "SignalLongName" SG_ 1927 DTCIUnused4_787 "Diagnostic Trouble Code Information Extended 787 : Unused 4";
BA_ "VNSigAllNodes" SG_ 1927 DTCIUnused4_787 1;
BA_ "SignalType" SG_ 1927 DTCIUnused5_787 "BLN";
BA_ "PacketOrder" SG_ 1927 DTCIUnused5_787 5;
BA_ "SignalLongName" SG_ 1927 DTCIUnused5_787 "Diagnostic Trouble Code Information Extended 787 : Unused 5";
BA_ "VNSigAllNodes" SG_ 1927 DTCIUnused5_787 1;
BA_ "SignalType" SG_ 1927 DTCIUnused6_787 "BLN";
BA_ "PacketOrder" SG_ 1927 DTCIUnused6_787 6;
BA_ "SignalLongName" SG_ 1927 DTCIUnused6_787 "Diagnostic Trouble Code Information Extended 787 : Unused 6";
BA_ "VNSigAllNodes" SG_ 1927 DTCIUnused6_787 1;
BA_ "SignalType" SG_ 1927 DTCIUnused7_787 "BLN";
BA_ "PacketOrder" SG_ 1927 DTCIUnused7_787 7;
BA_ "SignalLongName" SG_ 1927 DTCIUnused7_787 "Diagnostic Trouble Code Information Extended 787 : Unused 7";
BA_ "VNSigAllNodes" SG_ 1927 DTCIUnused7_787 1;
BA_ "SignalType" SG_ 1927 DTCI_WrnIndRqdSt_787 "BLN";
BA_ "PacketOrder" SG_ 1927 DTCI_WrnIndRqdSt_787 12;
BA_ "SignalLongName" SG_ 1927 DTCI_WrnIndRqdSt_787 "Diagnostic Trouble Code Information Extended 787 : Warning Indicator Requested Status";
BA_ "VNSigAllNodes" SG_ 1927 DTCI_WrnIndRqdSt_787 1;
BA_ "SignalType" SG_ 1926 DTCI_CodeSupported_786 "BLN";
BA_ "PacketOrder" SG_ 1926 DTCI_CodeSupported_786 19;
BA_ "SignalLongName" SG_ 1926 DTCI_CodeSupported_786 "Diagnostic Trouble Code Information Extended 786 : Code Supported";
BA_ "VNSigAllNodes" SG_ 1926 DTCI_CodeSupported_786 1;
BA_ "SignalType" SG_ 1926 DTCI_CurrentStatus_786 "BLN";
BA_ "PacketOrder" SG_ 1926 DTCI_CurrentStatus_786 18;
BA_ "SignalLongName" SG_ 1926 DTCI_CurrentStatus_786 "Diagnostic Trouble Code Information Extended 786 : Current Status";
BA_ "VNSigAllNodes" SG_ 1926 DTCI_CurrentStatus_786 1;
BA_ "SignalType" SG_ 1926 DTCI_DTCFailType_786 "UNM";
BA_ "PacketOrder" SG_ 1926 DTCI_DTCFailType_786 11;
BA_ "SignalLongName" SG_ 1926 DTCI_DTCFailType_786 "Diagnostic Trouble Code Information Extended 786 : Diagnostic Trouble Code Failure Type";
BA_ "VNSigAllNodes" SG_ 1926 DTCI_DTCFailType_786 1;
BA_ "SignalType" SG_ 1926 DTCI_DTCFaultType_786 "ENM";
BA_ "PacketOrder" SG_ 1926 DTCI_DTCFaultType_786 20;
BA_ "SignalLongName" SG_ 1926 DTCI_DTCFaultType_786 "Diagnostic Trouble Code Information Extended 786 : Diagnostic Trouble Code Fault Type";
BA_ "VNSigAllNodes" SG_ 1926 DTCI_DTCFaultType_786 1;
BA_ "SignalType" SG_ 1926 DTCI_DTCNumber_786 "UNM";
BA_ "PacketOrder" SG_ 1926 DTCI_DTCNumber_786 10;
BA_ "SignalLongName" SG_ 1926 DTCI_DTCNumber_786 "Diagnostic Trouble Code Information Extended 786 : Diagnostic Trouble Code Number";
BA_ "VNSigAllNodes" SG_ 1926 DTCI_DTCNumber_786 1;
BA_ "SignalType" SG_ 1926 DTCI_DTCSource_786 "UNM";
BA_ "PacketOrder" SG_ 1926 DTCI_DTCSource_786 9;
BA_ "SignalLongName" SG_ 1926 DTCI_DTCSource_786 "Diagnostic Trouble Code Information Extended 786 : Diagnostic Trouble Code Source";
BA_ "VNSigAllNodes" SG_ 1926 DTCI_DTCSource_786 1;
BA_ "SignalType" SG_ 1926 DTCI_DTCTriggered_786 "BLN";
BA_ "PacketOrder" SG_ 1926 DTCI_DTCTriggered_786 8;
BA_ "SignalLongName" SG_ 1926 DTCI_DTCTriggered_786 "Diagnostic Trouble Code Information Extended 786 : Diagnostic Trouble Code Triggered";
BA_ "VNSigAllNodes" SG_ 1926 DTCI_DTCTriggered_786 1;
BA_ "SignalType" SG_ 1926 DTCI_HistStat_786 "BLN";
BA_ "PacketOrder" SG_ 1926 DTCI_HistStat_786 15;
BA_ "SignalLongName" SG_ 1926 DTCI_HistStat_786 "Diagnostic Trouble Code Information Extended 786 : History Status";
BA_ "VNSigAllNodes" SG_ 1926 DTCI_HistStat_786 1;
BA_ "SignalType" SG_ 1926 DTCI_TstFldCdClrdStat_786 "BLN";
BA_ "PacketOrder" SG_ 1926 DTCI_TstFldCdClrdStat_786 16;
BA_ "SignalLongName" SG_ 1926 DTCI_TstFldCdClrdStat_786 "Diagnostic Trouble Code Information Extended 786 : Test Failed Since Code Cleared Status";
BA_ "VNSigAllNodes" SG_ 1926 DTCI_TstFldCdClrdStat_786 1;
BA_ "SignalType" SG_ 1926 DTCI_TstFldPwrUpSt_786 "BLN";
BA_ "PacketOrder" SG_ 1926 DTCI_TstFldPwrUpSt_786 13;
BA_ "SignalLongName" SG_ 1926 DTCI_TstFldPwrUpSt_786 "Diagnostic Trouble Code Information Extended 786 : Test Failed Since Power Up Status";
BA_ "VNSigAllNodes" SG_ 1926 DTCI_TstFldPwrUpSt_786 1;
BA_ "SignalType" SG_ 1926 DTCI_TstNPsdCdClrdSt_786 "BLN";
BA_ "PacketOrder" SG_ 1926 DTCI_TstNPsdCdClrdSt_786 17;
BA_ "SignalLongName" SG_ 1926 DTCI_TstNPsdCdClrdSt_786 "Diagnostic Trouble Code Information Extended 786 : Test Not Passed Since Code Cleared Status";
BA_ "VNSigAllNodes" SG_ 1926 DTCI_TstNPsdCdClrdSt_786 1;
BA_ "SignalType" SG_ 1926 DTCI_TstNPsdPwrUpSt_786 "BLN";
BA_ "PacketOrder" SG_ 1926 DTCI_TstNPsdPwrUpSt_786 14;
BA_ "SignalLongName" SG_ 1926 DTCI_TstNPsdPwrUpSt_786 "Diagnostic Trouble Code Information Extended 786 : Test Not Passed Since Power Up Status";
BA_ "VNSigAllNodes" SG_ 1926 DTCI_TstNPsdPwrUpSt_786 1;
BA_ "SignalType" SG_ 1926 DTCIUnused1_786 "BLN";
BA_ "PacketOrder" SG_ 1926 DTCIUnused1_786 1;
BA_ "SignalLongName" SG_ 1926 DTCIUnused1_786 "Diagnostic Trouble Code Information Extended 786 : Unused 1";
BA_ "VNSigAllNodes" SG_ 1926 DTCIUnused1_786 1;
BA_ "SignalType" SG_ 1926 DTCIUnused2_786 "BLN";
BA_ "PacketOrder" SG_ 1926 DTCIUnused2_786 2;
BA_ "SignalLongName" SG_ 1926 DTCIUnused2_786 "Diagnostic Trouble Code Information Extended 786 : Unused 2";
BA_ "VNSigAllNodes" SG_ 1926 DTCIUnused2_786 1;
BA_ "SignalType" SG_ 1926 DTCIUnused3_786 "BLN";
BA_ "PacketOrder" SG_ 1926 DTCIUnused3_786 3;
BA_ "SignalLongName" SG_ 1926 DTCIUnused3_786 "Diagnostic Trouble Code Information Extended 786 : Unused 3";
BA_ "VNSigAllNodes" SG_ 1926 DTCIUnused3_786 1;
BA_ "SignalType" SG_ 1926 DTCIUnused4_786 "BLN";
BA_ "PacketOrder" SG_ 1926 DTCIUnused4_786 4;
BA_ "SignalLongName" SG_ 1926 DTCIUnused4_786 "Diagnostic Trouble Code Information Extended 786 : Unused 4";
BA_ "VNSigAllNodes" SG_ 1926 DTCIUnused4_786 1;
BA_ "SignalType" SG_ 1926 DTCIUnused5_786 "BLN";
BA_ "PacketOrder" SG_ 1926 DTCIUnused5_786 5;
BA_ "SignalLongName" SG_ 1926 DTCIUnused5_786 "Diagnostic Trouble Code Information Extended 786 : Unused 5";
BA_ "VNSigAllNodes" SG_ 1926 DTCIUnused5_786 1;
BA_ "SignalType" SG_ 1926 DTCIUnused6_786 "BLN";
BA_ "PacketOrder" SG_ 1926 DTCIUnused6_786 6;
BA_ "SignalLongName" SG_ 1926 DTCIUnused6_786 "Diagnostic Trouble Code Information Extended 786 : Unused 6";
BA_ "VNSigAllNodes" SG_ 1926 DTCIUnused6_786 1;
BA_ "SignalType" SG_ 1926 DTCIUnused7_786 "BLN";
BA_ "PacketOrder" SG_ 1926 DTCIUnused7_786 7;
BA_ "SignalLongName" SG_ 1926 DTCIUnused7_786 "Diagnostic Trouble Code Information Extended 786 : Unused 7";
BA_ "VNSigAllNodes" SG_ 1926 DTCIUnused7_786 1;
BA_ "SignalType" SG_ 1926 DTCI_WrnIndRqdSt_786 "BLN";
BA_ "PacketOrder" SG_ 1926 DTCI_WrnIndRqdSt_786 12;
BA_ "SignalLongName" SG_ 1926 DTCI_WrnIndRqdSt_786 "Diagnostic Trouble Code Information Extended 786 : Warning Indicator Requested Status";
BA_ "VNSigAllNodes" SG_ 1926 DTCI_WrnIndRqdSt_786 1;
BA_ "SignalType" SG_ 1925 DTCI_CodeSupported_785 "BLN";
BA_ "PacketOrder" SG_ 1925 DTCI_CodeSupported_785 19;
BA_ "SignalLongName" SG_ 1925 DTCI_CodeSupported_785 "Diagnostic Trouble Code Information Extended 785 : Code Supported";
BA_ "VNSigAllNodes" SG_ 1925 DTCI_CodeSupported_785 1;
BA_ "SignalType" SG_ 1925 DTCI_CurrentStatus_785 "BLN";
BA_ "PacketOrder" SG_ 1925 DTCI_CurrentStatus_785 18;
BA_ "SignalLongName" SG_ 1925 DTCI_CurrentStatus_785 "Diagnostic Trouble Code Information Extended 785 : Current Status";
BA_ "VNSigAllNodes" SG_ 1925 DTCI_CurrentStatus_785 1;
BA_ "SignalType" SG_ 1925 DTCI_DTCFailType_785 "UNM";
BA_ "PacketOrder" SG_ 1925 DTCI_DTCFailType_785 11;
BA_ "SignalLongName" SG_ 1925 DTCI_DTCFailType_785 "Diagnostic Trouble Code Information Extended 785 : Diagnostic Trouble Code Failure Type";
BA_ "VNSigAllNodes" SG_ 1925 DTCI_DTCFailType_785 1;
BA_ "SignalType" SG_ 1925 DTCI_DTCFaultType_785 "ENM";
BA_ "PacketOrder" SG_ 1925 DTCI_DTCFaultType_785 20;
BA_ "SignalLongName" SG_ 1925 DTCI_DTCFaultType_785 "Diagnostic Trouble Code Information Extended 785 : Diagnostic Trouble Code Fault Type";
BA_ "VNSigAllNodes" SG_ 1925 DTCI_DTCFaultType_785 1;
BA_ "SignalType" SG_ 1925 DTCI_DTCNumber_785 "UNM";
BA_ "PacketOrder" SG_ 1925 DTCI_DTCNumber_785 10;
BA_ "SignalLongName" SG_ 1925 DTCI_DTCNumber_785 "Diagnostic Trouble Code Information Extended 785 : Diagnostic Trouble Code Number";
BA_ "VNSigAllNodes" SG_ 1925 DTCI_DTCNumber_785 1;
BA_ "SignalType" SG_ 1925 DTCI_DTCSource_785 "UNM";
BA_ "PacketOrder" SG_ 1925 DTCI_DTCSource_785 9;
BA_ "SignalLongName" SG_ 1925 DTCI_DTCSource_785 "Diagnostic Trouble Code Information Extended 785 : Diagnostic Trouble Code Source";
BA_ "VNSigAllNodes" SG_ 1925 DTCI_DTCSource_785 1;
BA_ "SignalType" SG_ 1925 DTCI_DTCTriggered_785 "BLN";
BA_ "PacketOrder" SG_ 1925 DTCI_DTCTriggered_785 8;
BA_ "SignalLongName" SG_ 1925 DTCI_DTCTriggered_785 "Diagnostic Trouble Code Information Extended 785 : Diagnostic Trouble Code Triggered";
BA_ "VNSigAllNodes" SG_ 1925 DTCI_DTCTriggered_785 1;
BA_ "SignalType" SG_ 1925 DTCI_HistStat_785 "BLN";
BA_ "PacketOrder" SG_ 1925 DTCI_HistStat_785 15;
BA_ "SignalLongName" SG_ 1925 DTCI_HistStat_785 "Diagnostic Trouble Code Information Extended 785 : History Status";
BA_ "VNSigAllNodes" SG_ 1925 DTCI_HistStat_785 1;
BA_ "SignalType" SG_ 1925 DTCI_TstFldCdClrdStat_785 "BLN";
BA_ "PacketOrder" SG_ 1925 DTCI_TstFldCdClrdStat_785 16;
BA_ "SignalLongName" SG_ 1925 DTCI_TstFldCdClrdStat_785 "Diagnostic Trouble Code Information Extended 785 : Test Failed Since Code Cleared Status";
BA_ "VNSigAllNodes" SG_ 1925 DTCI_TstFldCdClrdStat_785 1;
BA_ "SignalType" SG_ 1925 DTCI_TstFldPwrUpSt_785 "BLN";
BA_ "PacketOrder" SG_ 1925 DTCI_TstFldPwrUpSt_785 13;
BA_ "SignalLongName" SG_ 1925 DTCI_TstFldPwrUpSt_785 "Diagnostic Trouble Code Information Extended 785 : Test Failed Since Power Up Status";
BA_ "VNSigAllNodes" SG_ 1925 DTCI_TstFldPwrUpSt_785 1;
BA_ "SignalType" SG_ 1925 DTCI_TstNPsdCdClrdSt_785 "BLN";
BA_ "PacketOrder" SG_ 1925 DTCI_TstNPsdCdClrdSt_785 17;
BA_ "SignalLongName" SG_ 1925 DTCI_TstNPsdCdClrdSt_785 "Diagnostic Trouble Code Information Extended 785 : Test Not Passed Since Code Cleared Status";
BA_ "VNSigAllNodes" SG_ 1925 DTCI_TstNPsdCdClrdSt_785 1;
BA_ "SignalType" SG_ 1925 DTCI_TstNPsdPwrUpSt_785 "BLN";
BA_ "PacketOrder" SG_ 1925 DTCI_TstNPsdPwrUpSt_785 14;
BA_ "SignalLongName" SG_ 1925 DTCI_TstNPsdPwrUpSt_785 "Diagnostic Trouble Code Information Extended 785 : Test Not Passed Since Power Up Status";
BA_ "VNSigAllNodes" SG_ 1925 DTCI_TstNPsdPwrUpSt_785 1;
BA_ "SignalType" SG_ 1925 DTCIUnused1_785 "BLN";
BA_ "PacketOrder" SG_ 1925 DTCIUnused1_785 1;
BA_ "SignalLongName" SG_ 1925 DTCIUnused1_785 "Diagnostic Trouble Code Information Extended 785 : Unused 1";
BA_ "VNSigAllNodes" SG_ 1925 DTCIUnused1_785 1;
BA_ "SignalType" SG_ 1925 DTCIUnused2_785 "BLN";
BA_ "PacketOrder" SG_ 1925 DTCIUnused2_785 2;
BA_ "SignalLongName" SG_ 1925 DTCIUnused2_785 "Diagnostic Trouble Code Information Extended 785 : Unused 2";
BA_ "VNSigAllNodes" SG_ 1925 DTCIUnused2_785 1;
BA_ "SignalType" SG_ 1925 DTCIUnused3_785 "BLN";
BA_ "PacketOrder" SG_ 1925 DTCIUnused3_785 3;
BA_ "SignalLongName" SG_ 1925 DTCIUnused3_785 "Diagnostic Trouble Code Information Extended 785 : Unused 3";
BA_ "VNSigAllNodes" SG_ 1925 DTCIUnused3_785 1;
BA_ "SignalType" SG_ 1925 DTCIUnused4_785 "BLN";
BA_ "PacketOrder" SG_ 1925 DTCIUnused4_785 4;
BA_ "SignalLongName" SG_ 1925 DTCIUnused4_785 "Diagnostic Trouble Code Information Extended 785 : Unused 4";
BA_ "VNSigAllNodes" SG_ 1925 DTCIUnused4_785 1;
BA_ "SignalType" SG_ 1925 DTCIUnused5_785 "BLN";
BA_ "PacketOrder" SG_ 1925 DTCIUnused5_785 5;
BA_ "SignalLongName" SG_ 1925 DTCIUnused5_785 "Diagnostic Trouble Code Information Extended 785 : Unused 5";
BA_ "VNSigAllNodes" SG_ 1925 DTCIUnused5_785 1;
BA_ "SignalType" SG_ 1925 DTCIUnused6_785 "BLN";
BA_ "PacketOrder" SG_ 1925 DTCIUnused6_785 6;
BA_ "SignalLongName" SG_ 1925 DTCIUnused6_785 "Diagnostic Trouble Code Information Extended 785 : Unused 6";
BA_ "VNSigAllNodes" SG_ 1925 DTCIUnused6_785 1;
BA_ "SignalType" SG_ 1925 DTCIUnused7_785 "BLN";
BA_ "PacketOrder" SG_ 1925 DTCIUnused7_785 7;
BA_ "SignalLongName" SG_ 1925 DTCIUnused7_785 "Diagnostic Trouble Code Information Extended 785 : Unused 7";
BA_ "VNSigAllNodes" SG_ 1925 DTCIUnused7_785 1;
BA_ "SignalType" SG_ 1925 DTCI_WrnIndRqdSt_785 "BLN";
BA_ "PacketOrder" SG_ 1925 DTCI_WrnIndRqdSt_785 12;
BA_ "SignalLongName" SG_ 1925 DTCI_WrnIndRqdSt_785 "Diagnostic Trouble Code Information Extended 785 : Warning Indicator Requested Status";
BA_ "VNSigAllNodes" SG_ 1925 DTCI_WrnIndRqdSt_785 1;
BA_ "SignalType" SG_ 1924 DTCI_HistStat_784 "BLN";
BA_ "PacketOrder" SG_ 1924 DTCI_HistStat_784 15;
BA_ "SignalLongName" SG_ 1924 DTCI_HistStat_784 "Diagnostic Trouble Code Information Extended 784 : History Status";
BA_ "VNSigAllNodes" SG_ 1924 DTCI_HistStat_784 1;
BA_ "SignalType" SG_ 1924 DTCI_TstFldCdClrdStat_784 "BLN";
BA_ "PacketOrder" SG_ 1924 DTCI_TstFldCdClrdStat_784 16;
BA_ "SignalLongName" SG_ 1924 DTCI_TstFldCdClrdStat_784 "Diagnostic Trouble Code Information Extended 784 : Test Failed Since Code Cleared Status";
BA_ "VNSigAllNodes" SG_ 1924 DTCI_TstFldCdClrdStat_784 1;
BA_ "SignalType" SG_ 1924 DTCI_TstFldPwrUpSt_784 "BLN";
BA_ "PacketOrder" SG_ 1924 DTCI_TstFldPwrUpSt_784 13;
BA_ "SignalLongName" SG_ 1924 DTCI_TstFldPwrUpSt_784 "Diagnostic Trouble Code Information Extended 784 : Test Failed Since Power Up Status";
BA_ "VNSigAllNodes" SG_ 1924 DTCI_TstFldPwrUpSt_784 1;
BA_ "SignalType" SG_ 1924 DTCI_TstNPsdCdClrdSt_784 "BLN";
BA_ "PacketOrder" SG_ 1924 DTCI_TstNPsdCdClrdSt_784 17;
BA_ "SignalLongName" SG_ 1924 DTCI_TstNPsdCdClrdSt_784 "Diagnostic Trouble Code Information Extended 784 : Test Not Passed Since Code Cleared Status";
BA_ "VNSigAllNodes" SG_ 1924 DTCI_TstNPsdCdClrdSt_784 1;
BA_ "SignalType" SG_ 1924 DTCI_TstNPsdPwrUpSt_784 "BLN";
BA_ "PacketOrder" SG_ 1924 DTCI_TstNPsdPwrUpSt_784 14;
BA_ "SignalLongName" SG_ 1924 DTCI_TstNPsdPwrUpSt_784 "Diagnostic Trouble Code Information Extended 784 : Test Not Passed Since Power Up Status";
BA_ "VNSigAllNodes" SG_ 1924 DTCI_TstNPsdPwrUpSt_784 1;
BA_ "SignalType" SG_ 1924 DTCIUnused1_784 "BLN";
BA_ "PacketOrder" SG_ 1924 DTCIUnused1_784 1;
BA_ "SignalLongName" SG_ 1924 DTCIUnused1_784 "Diagnostic Trouble Code Information Extended 784 : Unused 1";
BA_ "VNSigAllNodes" SG_ 1924 DTCIUnused1_784 1;
BA_ "SignalType" SG_ 1924 DTCIUnused2_784 "BLN";
BA_ "PacketOrder" SG_ 1924 DTCIUnused2_784 2;
BA_ "SignalLongName" SG_ 1924 DTCIUnused2_784 "Diagnostic Trouble Code Information Extended 784 : Unused 2";
BA_ "VNSigAllNodes" SG_ 1924 DTCIUnused2_784 1;
BA_ "SignalType" SG_ 1924 DTCIUnused3_784 "BLN";
BA_ "PacketOrder" SG_ 1924 DTCIUnused3_784 3;
BA_ "SignalLongName" SG_ 1924 DTCIUnused3_784 "Diagnostic Trouble Code Information Extended 784 : Unused 3";
BA_ "VNSigAllNodes" SG_ 1924 DTCIUnused3_784 1;
BA_ "SignalType" SG_ 1924 DTCIUnused4_784 "BLN";
BA_ "PacketOrder" SG_ 1924 DTCIUnused4_784 4;
BA_ "SignalLongName" SG_ 1924 DTCIUnused4_784 "Diagnostic Trouble Code Information Extended 784 : Unused 4";
BA_ "VNSigAllNodes" SG_ 1924 DTCIUnused4_784 1;
BA_ "SignalType" SG_ 1924 DTCIUnused5_784 "BLN";
BA_ "PacketOrder" SG_ 1924 DTCIUnused5_784 5;
BA_ "SignalLongName" SG_ 1924 DTCIUnused5_784 "Diagnostic Trouble Code Information Extended 784 : Unused 5";
BA_ "VNSigAllNodes" SG_ 1924 DTCIUnused5_784 1;
BA_ "SignalType" SG_ 1924 DTCIUnused6_784 "BLN";
BA_ "PacketOrder" SG_ 1924 DTCIUnused6_784 6;
BA_ "SignalLongName" SG_ 1924 DTCIUnused6_784 "Diagnostic Trouble Code Information Extended 784 : Unused 6";
BA_ "VNSigAllNodes" SG_ 1924 DTCIUnused6_784 1;
BA_ "SignalType" SG_ 1924 DTCIUnused7_784 "BLN";
BA_ "PacketOrder" SG_ 1924 DTCIUnused7_784 7;
BA_ "SignalLongName" SG_ 1924 DTCIUnused7_784 "Diagnostic Trouble Code Information Extended 784 : Unused 7";
BA_ "VNSigAllNodes" SG_ 1924 DTCIUnused7_784 1;
BA_ "SignalType" SG_ 1924 DTCI_WrnIndRqdSt_784 "BLN";
BA_ "PacketOrder" SG_ 1924 DTCI_WrnIndRqdSt_784 12;
BA_ "SignalLongName" SG_ 1924 DTCI_WrnIndRqdSt_784 "Diagnostic Trouble Code Information Extended 784 : Warning Indicator Requested Status";
BA_ "VNSigAllNodes" SG_ 1924 DTCI_WrnIndRqdSt_784 1;
BA_ "SignalType" SG_ 1924 DTCI_CodeSupported_784 "BLN";
BA_ "PacketOrder" SG_ 1924 DTCI_CodeSupported_784 19;
BA_ "SignalLongName" SG_ 1924 DTCI_CodeSupported_784 "Diagnostic Trouble Code Information Extended 784 : Code Supported";
BA_ "VNSigAllNodes" SG_ 1924 DTCI_CodeSupported_784 1;
BA_ "SignalType" SG_ 1924 DTCI_CurrentStatus_784 "BLN";
BA_ "PacketOrder" SG_ 1924 DTCI_CurrentStatus_784 18;
BA_ "SignalLongName" SG_ 1924 DTCI_CurrentStatus_784 "Diagnostic Trouble Code Information Extended 784 : Current Status";
BA_ "VNSigAllNodes" SG_ 1924 DTCI_CurrentStatus_784 1;
BA_ "SignalType" SG_ 1924 DTCI_DTCFailType_784 "UNM";
BA_ "PacketOrder" SG_ 1924 DTCI_DTCFailType_784 11;
BA_ "SignalLongName" SG_ 1924 DTCI_DTCFailType_784 "Diagnostic Trouble Code Information Extended 784 : Diagnostic Trouble Code Failure Type";
BA_ "VNSigAllNodes" SG_ 1924 DTCI_DTCFailType_784 1;
BA_ "SignalType" SG_ 1924 DTCI_DTCFaultType_784 "ENM";
BA_ "PacketOrder" SG_ 1924 DTCI_DTCFaultType_784 20;
BA_ "SignalLongName" SG_ 1924 DTCI_DTCFaultType_784 "Diagnostic Trouble Code Information Extended 784 : Diagnostic Trouble Code Fault Type";
BA_ "VNSigAllNodes" SG_ 1924 DTCI_DTCFaultType_784 1;
BA_ "SignalType" SG_ 1924 DTCI_DTCNumber_784 "UNM";
BA_ "PacketOrder" SG_ 1924 DTCI_DTCNumber_784 10;
BA_ "SignalLongName" SG_ 1924 DTCI_DTCNumber_784 "Diagnostic Trouble Code Information Extended 784 : Diagnostic Trouble Code Number";
BA_ "VNSigAllNodes" SG_ 1924 DTCI_DTCNumber_784 1;
BA_ "SignalType" SG_ 1924 DTCI_DTCSource_784 "UNM";
BA_ "PacketOrder" SG_ 1924 DTCI_DTCSource_784 9;
BA_ "SignalLongName" SG_ 1924 DTCI_DTCSource_784 "Diagnostic Trouble Code Information Extended 784 : Diagnostic Trouble Code Source";
BA_ "VNSigAllNodes" SG_ 1924 DTCI_DTCSource_784 1;
BA_ "SignalType" SG_ 1924 DTCI_DTCTriggered_784 "BLN";
BA_ "PacketOrder" SG_ 1924 DTCI_DTCTriggered_784 8;
BA_ "SignalLongName" SG_ 1924 DTCI_DTCTriggered_784 "Diagnostic Trouble Code Information Extended 784 : Diagnostic Trouble Code Triggered";
BA_ "VNSigAllNodes" SG_ 1924 DTCI_DTCTriggered_784 1;
BA_ "SignalType" SG_ 1923 DTCI_WrnIndRqdSt_783 "BLN";
BA_ "PacketOrder" SG_ 1923 DTCI_WrnIndRqdSt_783 12;
BA_ "SignalLongName" SG_ 1923 DTCI_WrnIndRqdSt_783 "Diagnostic Trouble Code Information Extended 783 : Warning Indicator Requested Status";
BA_ "VNSigAllNodes" SG_ 1923 DTCI_WrnIndRqdSt_783 1;
BA_ "SignalType" SG_ 1923 DTCI_TstNPsdPwrUpSt_783 "BLN";
BA_ "PacketOrder" SG_ 1923 DTCI_TstNPsdPwrUpSt_783 14;
BA_ "SignalLongName" SG_ 1923 DTCI_TstNPsdPwrUpSt_783 "Diagnostic Trouble Code Information Extended 783 : Test Not Passed Since Power Up Status";
BA_ "VNSigAllNodes" SG_ 1923 DTCI_TstNPsdPwrUpSt_783 1;
BA_ "SignalType" SG_ 1923 DTCI_TstNPsdCdClrdSt_783 "BLN";
BA_ "PacketOrder" SG_ 1923 DTCI_TstNPsdCdClrdSt_783 17;
BA_ "SignalLongName" SG_ 1923 DTCI_TstNPsdCdClrdSt_783 "Diagnostic Trouble Code Information Extended 783 : Test Not Passed Since Code Cleared Status";
BA_ "VNSigAllNodes" SG_ 1923 DTCI_TstNPsdCdClrdSt_783 1;
BA_ "SignalType" SG_ 1923 DTCI_TstFldPwrUpSt_783 "BLN";
BA_ "PacketOrder" SG_ 1923 DTCI_TstFldPwrUpSt_783 13;
BA_ "SignalLongName" SG_ 1923 DTCI_TstFldPwrUpSt_783 "Diagnostic Trouble Code Information Extended 783 : Test Failed Since Power Up Status";
BA_ "VNSigAllNodes" SG_ 1923 DTCI_TstFldPwrUpSt_783 1;
BA_ "SignalType" SG_ 1923 DTCI_TstFldCdClrdStat_783 "BLN";
BA_ "PacketOrder" SG_ 1923 DTCI_TstFldCdClrdStat_783 16;
BA_ "SignalLongName" SG_ 1923 DTCI_TstFldCdClrdStat_783 "Diagnostic Trouble Code Information Extended 783 : Test Failed Since Code Cleared Status";
BA_ "VNSigAllNodes" SG_ 1923 DTCI_TstFldCdClrdStat_783 1;
BA_ "SignalType" SG_ 1923 DTCI_HistStat_783 "BLN";
BA_ "PacketOrder" SG_ 1923 DTCI_HistStat_783 15;
BA_ "SignalLongName" SG_ 1923 DTCI_HistStat_783 "Diagnostic Trouble Code Information Extended 783 : History Status";
BA_ "VNSigAllNodes" SG_ 1923 DTCI_HistStat_783 1;
BA_ "SignalType" SG_ 1923 DTCI_DTCTriggered_783 "BLN";
BA_ "PacketOrder" SG_ 1923 DTCI_DTCTriggered_783 8;
BA_ "SignalLongName" SG_ 1923 DTCI_DTCTriggered_783 "Diagnostic Trouble Code Information Extended 783 : Diagnostic Trouble Code Triggered";
BA_ "VNSigAllNodes" SG_ 1923 DTCI_DTCTriggered_783 1;
BA_ "SignalType" SG_ 1923 DTCI_DTCSource_783 "UNM";
BA_ "PacketOrder" SG_ 1923 DTCI_DTCSource_783 9;
BA_ "SignalLongName" SG_ 1923 DTCI_DTCSource_783 "Diagnostic Trouble Code Information Extended 783 : Diagnostic Trouble Code Source";
BA_ "VNSigAllNodes" SG_ 1923 DTCI_DTCSource_783 1;
BA_ "SignalType" SG_ 1923 DTCI_DTCNumber_783 "UNM";
BA_ "PacketOrder" SG_ 1923 DTCI_DTCNumber_783 10;
BA_ "SignalLongName" SG_ 1923 DTCI_DTCNumber_783 "Diagnostic Trouble Code Information Extended 783 : Diagnostic Trouble Code Number";
BA_ "VNSigAllNodes" SG_ 1923 DTCI_DTCNumber_783 1;
BA_ "SignalType" SG_ 1923 DTCI_DTCFaultType_783 "ENM";
BA_ "PacketOrder" SG_ 1923 DTCI_DTCFaultType_783 20;
BA_ "SignalLongName" SG_ 1923 DTCI_DTCFaultType_783 "Diagnostic Trouble Code Information Extended 783 : Diagnostic Trouble Code Fault Type";
BA_ "VNSigAllNodes" SG_ 1923 DTCI_DTCFaultType_783 1;
BA_ "SignalType" SG_ 1923 DTCI_DTCFailType_783 "UNM";
BA_ "PacketOrder" SG_ 1923 DTCI_DTCFailType_783 11;
BA_ "SignalLongName" SG_ 1923 DTCI_DTCFailType_783 "Diagnostic Trouble Code Information Extended 783 : Diagnostic Trouble Code Failure Type";
BA_ "VNSigAllNodes" SG_ 1923 DTCI_DTCFailType_783 1;
BA_ "SignalType" SG_ 1923 DTCI_CurrentStatus_783 "BLN";
BA_ "PacketOrder" SG_ 1923 DTCI_CurrentStatus_783 18;
BA_ "SignalLongName" SG_ 1923 DTCI_CurrentStatus_783 "Diagnostic Trouble Code Information Extended 783 : Current Status";
BA_ "VNSigAllNodes" SG_ 1923 DTCI_CurrentStatus_783 1;
BA_ "SignalType" SG_ 1923 DTCI_CodeSupported_783 "BLN";
BA_ "PacketOrder" SG_ 1923 DTCI_CodeSupported_783 19;
BA_ "SignalLongName" SG_ 1923 DTCI_CodeSupported_783 "Diagnostic Trouble Code Information Extended 783 : Code Supported";
BA_ "VNSigAllNodes" SG_ 1923 DTCI_CodeSupported_783 1;
BA_ "SignalType" SG_ 1923 DTCIUnused7_783 "BLN";
BA_ "PacketOrder" SG_ 1923 DTCIUnused7_783 7;
BA_ "SignalLongName" SG_ 1923 DTCIUnused7_783 "Diagnostic Trouble Code Information Extended 783 : Unused 7";
BA_ "VNSigAllNodes" SG_ 1923 DTCIUnused7_783 1;
BA_ "SignalType" SG_ 1923 DTCIUnused6_783 "BLN";
BA_ "PacketOrder" SG_ 1923 DTCIUnused6_783 6;
BA_ "SignalLongName" SG_ 1923 DTCIUnused6_783 "Diagnostic Trouble Code Information Extended 783 : Unused 6";
BA_ "VNSigAllNodes" SG_ 1923 DTCIUnused6_783 1;
BA_ "SignalType" SG_ 1923 DTCIUnused5_783 "BLN";
BA_ "PacketOrder" SG_ 1923 DTCIUnused5_783 5;
BA_ "SignalLongName" SG_ 1923 DTCIUnused5_783 "Diagnostic Trouble Code Information Extended 783 : Unused 5";
BA_ "VNSigAllNodes" SG_ 1923 DTCIUnused5_783 1;
BA_ "SignalType" SG_ 1923 DTCIUnused4_783 "BLN";
BA_ "PacketOrder" SG_ 1923 DTCIUnused4_783 4;
BA_ "SignalLongName" SG_ 1923 DTCIUnused4_783 "Diagnostic Trouble Code Information Extended 783 : Unused 4";
BA_ "VNSigAllNodes" SG_ 1923 DTCIUnused4_783 1;
BA_ "SignalType" SG_ 1923 DTCIUnused3_783 "BLN";
BA_ "PacketOrder" SG_ 1923 DTCIUnused3_783 3;
BA_ "SignalLongName" SG_ 1923 DTCIUnused3_783 "Diagnostic Trouble Code Information Extended 783 : Unused 3";
BA_ "VNSigAllNodes" SG_ 1923 DTCIUnused3_783 1;
BA_ "SignalType" SG_ 1923 DTCIUnused2_783 "BLN";
BA_ "PacketOrder" SG_ 1923 DTCIUnused2_783 2;
BA_ "SignalLongName" SG_ 1923 DTCIUnused2_783 "Diagnostic Trouble Code Information Extended 783 : Unused 2";
BA_ "VNSigAllNodes" SG_ 1923 DTCIUnused2_783 1;
BA_ "SignalType" SG_ 1923 DTCIUnused1_783 "BLN";
BA_ "PacketOrder" SG_ 1923 DTCIUnused1_783 1;
BA_ "SignalLongName" SG_ 1923 DTCIUnused1_783 "Diagnostic Trouble Code Information Extended 783 : Unused 1";
BA_ "VNSigAllNodes" SG_ 1923 DTCIUnused1_783 1;
BA_ "VNSigSLHSSharedDiagnostic" SG_ 1363 DgnInf_HS553 1;
BA_ "SignalType" SG_ 1363 DgnInf_HS553 "UNM";
BA_ "SignalLongName" SG_ 1363 DgnInf_HS553 "Diagnostic Information HS553";
BA_ "VNSigAllNodes" SG_ 1363 DgnInf_HS553 1;
BA_ "VNSigSLHSSharedDiagnostic" SG_ 607 DgnInf 1;
BA_ "SignalType" SG_ 607 DgnInf "UNM";
BA_ "SignalLongName" SG_ 607 DgnInf "Diagnostic Information";
BA_ "VNSigAllNodes" SG_ 607 DgnInf 1;
BA_ "VNSigSLHSSharedDiagnostic" SG_ 1630 DgnInf 1;
BA_ "SignalType" SG_ 1630 DgnInf "UNM";
BA_ "SignalLongName" SG_ 1630 DgnInf "Diagnostic Information";
BA_ "VNSigAllNodes" SG_ 1630 DgnInf 1;
BA_ "VNSigSLHSSharedDiagnostic" SG_ 1629 DgnInf 1;
BA_ "SignalType" SG_ 1629 DgnInf "UNM";
BA_ "SignalLongName" SG_ 1629 DgnInf "Diagnostic Information";
BA_ "VNSigAllNodes" SG_ 1629 DgnInf 1;
BA_ "VNSigSLHSSharedDiagnostic" SG_ 606 DgnInf 1;
BA_ "SignalType" SG_ 606 DgnInf "UNM";
BA_ "SignalLongName" SG_ 606 DgnInf "Diagnostic Information";
BA_ "VNSigAllNodes" SG_ 606 DgnInf 1;
BA_ "VNSigSLHSSharedDiagnostic" SG_ 605 DgnInf 1;
BA_ "SignalType" SG_ 605 DgnInf "UNM";
BA_ "SignalLongName" SG_ 605 DgnInf "Diagnostic Information";
BA_ "VNSigAllNodes" SG_ 605 DgnInf 1;
BA_ "VNSigSLHSSharedDiagnostic" SG_ 604 DgnInf 1;
BA_ "SignalType" SG_ 604 DgnInf "UNM";
BA_ "SignalLongName" SG_ 604 DgnInf "Diagnostic Information";
BA_ "VNSigAllNodes" SG_ 604 DgnInf 1;
BA_ "VNSigSLHSSharedDiagnostic" SG_ 603 DgnInf 1;
BA_ "SignalType" SG_ 603 DgnInf "UNM";
BA_ "SignalLongName" SG_ 603 DgnInf "Diagnostic Information";
BA_ "VNSigAllNodes" SG_ 603 DgnInf 1;
BA_ "VNSigSLHSSharedDiagnostic" SG_ 602 DgnInf 1;
BA_ "SignalType" SG_ 602 DgnInf "UNM";
BA_ "SignalLongName" SG_ 602 DgnInf "Diagnostic Information";
BA_ "VNSigAllNodes" SG_ 602 DgnInf 1;
BA_ "VNSigSLHSSharedDiagnostic" SG_ 1631 DgnInf 1;
BA_ "SignalType" SG_ 1631 DgnInf "UNM";
BA_ "SignalLongName" SG_ 1631 DgnInf "Diagnostic Information";
BA_ "VNSigAllNodes" SG_ 1631 DgnInf 1;
BA_ "VNSigSLHSSharedDiagnostic" SG_ 1375 DgnInf_HS55F 1;
BA_ "SignalType" SG_ 1375 DgnInf_HS55F "UNM";
BA_ "SignalLongName" SG_ 1375 DgnInf_HS55F "Diagnostic Information HS55F";
BA_ "VNSigAllNodes" SG_ 1375 DgnInf_HS55F 1;
BA_ "VNSigSLHSSharedDiagnostic" SG_ 1374 DgnInf_HS55E 1;
BA_ "SignalType" SG_ 1374 DgnInf_HS55E "UNM";
BA_ "SignalLongName" SG_ 1374 DgnInf_HS55E "Diagnostic Information HS55E";
BA_ "VNSigAllNodes" SG_ 1374 DgnInf_HS55E 1;
BA_REL_ "GenSigRxStartValue" BU_SG_REL_ ECM_HS SG_ 1005 EnhSvVehTopSpdLmR "$0 - No Action";
BA_REL_ "GenSigSuprvResp" BU_SG_REL_ ECM_HS SG_ 688 StrtrGenSpd 1;
BA_REL_ "GenSigTimeoutMsg" BU_SG_REL_ ECM_HS SG_ 688 StrtrGenSpd 688;
BA_REL_ "GenSigTimeoutTime" BU_SG_REL_ ECM_HS SG_ 688 StrtrGenSpd 250;
BA_REL_ "GenSigSuprvResp" BU_SG_REL_ EBCM_OBD_HS SG_ 688 StrtrGenSpd 1;
BA_REL_ "GenSigTimeoutMsg" BU_SG_REL_ EBCM_OBD_HS SG_ 688 StrtrGenSpd 688;
BA_REL_ "GenSigTimeoutTime" BU_SG_REL_ EBCM_OBD_HS SG_ 688 StrtrGenSpd 250;
BA_REL_ "GenSigSuprvResp" BU_SG_REL_ EBCM_HS SG_ 688 StrtrGenSpd 1;
BA_REL_ "GenSigTimeoutMsg" BU_SG_REL_ EBCM_HS SG_ 688 StrtrGenSpd 688;
BA_REL_ "GenSigTimeoutTime" BU_SG_REL_ EBCM_HS SG_ 688 StrtrGenSpd 250;
BA_REL_ "GenSigSuprvResp" BU_SG_REL_ ONSTAR_HS SG_ 993 HybVehHiVltSysDisbld 1;
BA_REL_ "GenSigTimeoutMsg" BU_SG_REL_ ONSTAR_HS SG_ 993 HybVehHiVltSysDisbld 993;
BA_REL_ "GenSigTimeoutTime" BU_SG_REL_ ONSTAR_HS SG_ 993 HybVehHiVltSysDisbld 250;
BA_REL_ "GenSigSuprvResp" BU_SG_REL_ BCM_HS SG_ 993 SvcHybridSysIO 1;
BA_REL_ "GenSigTimeoutMsg" BU_SG_REL_ BCM_HS SG_ 993 SvcHybridSysIO 993;
BA_REL_ "GenSigTimeoutTime" BU_SG_REL_ BCM_HS SG_ 993 SvcHybridSysIO 250;
BA_REL_ "GenSigSuprvResp" BU_SG_REL_ BCM_HS SG_ 490 SrvcFlSysPrkInOpnArIO 1;
BA_REL_ "GenSigTimeoutMsg" BU_SG_REL_ BCM_HS SG_ 490 SrvcFlSysPrkInOpnArIO 490;
BA_REL_ "GenSigTimeoutTime" BU_SG_REL_ BCM_HS SG_ 490 SrvcFlSysPrkInOpnArIO 250;
BA_REL_ "GenSigSuprvResp" BU_SG_REL_ BCM_HS SG_ 490 FuelSysNEmsRltMalfAct 1;
BA_REL_ "GenSigTimeoutMsg" BU_SG_REL_ BCM_HS SG_ 490 FuelSysNEmsRltMalfAct 490;
BA_REL_ "GenSigTimeoutTime" BU_SG_REL_ BCM_HS SG_ 490 FuelSysNEmsRltMalfAct 250;
BA_REL_ "GenSigSuprvResp" BU_SG_REL_ BCM_HS SG_ 490 InActFuelMdFuelLvlIO 1;
BA_REL_ "GenSigTimeoutMsg" BU_SG_REL_ BCM_HS SG_ 490 InActFuelMdFuelLvlIO 490;
BA_REL_ "GenSigTimeoutTime" BU_SG_REL_ BCM_HS SG_ 490 InActFuelMdFuelLvlIO 250;
BA_REL_ "GenSigSuprvResp" BU_SG_REL_ ECM_HS SG_ 431 TransVehTopSpdLim 1;
BA_REL_ "GenSigTimeoutMsg" BU_SG_REL_ ECM_HS SG_ 431 TransVehTopSpdLim 431;
BA_REL_ "GenSigTimeoutTime" BU_SG_REL_ ECM_HS SG_ 431 TransVehTopSpdLim 250;
BA_REL_ "GenSigSuprvResp" BU_SG_REL_ ECM_HS SG_ 431 TransMinVoltReq 1;
BA_REL_ "GenSigTimeoutMsg" BU_SG_REL_ ECM_HS SG_ 431 TransMinVoltReq 431;
BA_REL_ "GenSigTimeoutTime" BU_SG_REL_ ECM_HS SG_ 431 TransMinVoltReq 250;
BA_REL_ "GenSigSuprvResp" BU_SG_REL_ ECM_HS SG_ 431 TDslPrtFltrIdlRgtnMdAtv 1;
BA_REL_ "GenSigTimeoutMsg" BU_SG_REL_ ECM_HS SG_ 431 TDslPrtFltrIdlRgtnMdAtv 431;
BA_REL_ "GenSigTimeoutTime" BU_SG_REL_ ECM_HS SG_ 431 TDslPrtFltrIdlRgtnMdAtv 250;
BA_REL_ "GenSigSuprvResp" BU_SG_REL_ ECM_HS SG_ 431 DrvlneTrqStabStat 1;
BA_REL_ "GenSigTimeoutMsg" BU_SG_REL_ ECM_HS SG_ 431 DrvlneTrqStabStat 431;
BA_REL_ "GenSigTimeoutTime" BU_SG_REL_ ECM_HS SG_ 431 DrvlneTrqStabStat 250;
BA_REL_ "GenSigSuprvResp" BU_SG_REL_ ECM_HS SG_ 431 TrnsTrqCnvCltDsrSlp 1;
BA_REL_ "GenSigTimeoutMsg" BU_SG_REL_ ECM_HS SG_ 431 TrnsTrqCnvCltDsrSlp 431;
BA_REL_ "GenSigTimeoutTime" BU_SG_REL_ ECM_HS SG_ 431 TrnsTrqCnvCltDsrSlp 250;
BA_REL_ "GenSigSuprvResp" BU_SG_REL_ ECM_HS SG_ 431 TrnsStWntrMdOvrd 1;
BA_REL_ "GenSigTimeoutMsg" BU_SG_REL_ ECM_HS SG_ 431 TrnsStWntrMdOvrd 431;
BA_REL_ "GenSigTimeoutTime" BU_SG_REL_ ECM_HS SG_ 431 TrnsStWntrMdOvrd 250;
BA_REL_ "GenSigSuprvResp" BU_SG_REL_ ECM_HS SG_ 431 TrnsStTwHaulMdOvrd 1;
BA_REL_ "GenSigTimeoutMsg" BU_SG_REL_ ECM_HS SG_ 431 TrnsStTwHaulMdOvrd 431;
BA_REL_ "GenSigTimeoutTime" BU_SG_REL_ ECM_HS SG_ 431 TrnsStTwHaulMdOvrd 250;
BA_REL_ "GenSigSuprvResp" BU_SG_REL_ ECM_HS SG_ 431 TrnsStSprtMdOvrd 1;
BA_REL_ "GenSigTimeoutMsg" BU_SG_REL_ ECM_HS SG_ 431 TrnsStSprtMdOvrd 431;
BA_REL_ "GenSigTimeoutTime" BU_SG_REL_ ECM_HS SG_ 431 TrnsStSprtMdOvrd 250;
BA_REL_ "GenSigSuprvResp" BU_SG_REL_ ECM_HS SG_ 431 TrnsStEconMdOvrd 1;
BA_REL_ "GenSigTimeoutMsg" BU_SG_REL_ ECM_HS SG_ 431 TrnsStEconMdOvrd 431;
BA_REL_ "GenSigTimeoutTime" BU_SG_REL_ ECM_HS SG_ 431 TrnsStEconMdOvrd 250;
BA_REL_ "GenSigSuprvResp" BU_SG_REL_ ECM_HS SG_ 715 ACCATC_SplREngInpR 1;
BA_REL_ "GenSigTimeoutTime" BU_SG_REL_ ECM_HS SG_ 715 ACCATC_SplREngInpR 250;
BA_REL_ "GenSigSuprvResp" BU_SG_REL_ ECM_HS SG_ 715 ACCATC_DrvAstdGoSt 1;
BA_REL_ "GenSigTimeoutTime" BU_SG_REL_ ECM_HS SG_ 715 ACCATC_DrvAstdGoSt 250;
BA_REL_ "GenSigSuprvResp" BU_SG_REL_ ECM_HS SG_ 715 ACCATC_AxlTrqRq 1;
BA_REL_ "GenSigTimeoutTime" BU_SG_REL_ ECM_HS SG_ 715 ACCATC_AxlTrqRq 250;
BA_REL_ "GenSigSuprvResp" BU_SG_REL_ ECM_HS SG_ 715 ACCATC_ACCTyp 1;
BA_REL_ "GenSigTimeoutTime" BU_SG_REL_ ECM_HS SG_ 715 ACCATC_ACCTyp 250;
BA_REL_ "GenSigSuprvResp" BU_SG_REL_ ECM_HS SG_ 715 ACCATC_ACCAct 1;
BA_REL_ "GenSigTimeoutTime" BU_SG_REL_ ECM_HS SG_ 715 ACCATC_ACCAct 250;
BA_REL_ "GenSigSuprvResp" BU_SG_REL_ ECM_HS SG_ 715 ACCAxlTrqCmdProt 1;
BA_REL_ "GenSigTimeoutTime" BU_SG_REL_ ECM_HS SG_ 715 ACCAxlTrqCmdProt 250;
BA_REL_ "GenSigSuprvResp" BU_SG_REL_ ECM_HS SG_ 715 ACCCmndAlvRlgCnt 1;
BA_REL_ "GenSigTimeoutTime" BU_SG_REL_ ECM_HS SG_ 715 ACCCmndAlvRlgCnt 250;
BA_REL_ "GenSigSuprvResp" BU_SG_REL_ CGM_HS SG_ 1267 VehMassNom 1;
BA_REL_ "GenSigTimeoutMsg" BU_SG_REL_ CGM_HS SG_ 1267 VehMassNom 1267;
BA_REL_ "GenSigTimeoutTime" BU_SG_REL_ CGM_HS SG_ 1267 VehMassNom 2500;
BA_REL_ "GenSigSuprvResp" BU_SG_REL_ EOCM_F_HS SG_ 1267 VehMassNom 1;
BA_REL_ "GenSigTimeoutMsg" BU_SG_REL_ EOCM_F_HS SG_ 1267 VehMassNom 1267;
BA_REL_ "GenSigTimeoutTime" BU_SG_REL_ EOCM_F_HS SG_ 1267 VehMassNom 2500;
BA_REL_ "GenSigSuprvResp" BU_SG_REL_ ACC_HS SG_ 1267 VehMassNom 1;
BA_REL_ "GenSigTimeoutMsg" BU_SG_REL_ ACC_HS SG_ 1267 VehMassNom 1267;
BA_REL_ "GenSigTimeoutTime" BU_SG_REL_ ACC_HS SG_ 1267 VehMassNom 5000;
BA_REL_ "GenSigSuprvResp" BU_SG_REL_ FCM_HS SG_ 1267 VehMassNom 1;
BA_REL_ "GenSigTimeoutMsg" BU_SG_REL_ FCM_HS SG_ 1267 VehMassNom 1267;
BA_REL_ "GenSigTimeoutTime" BU_SG_REL_ FCM_HS SG_ 1267 VehMassNom 2500;
BA_REL_ "GenSigSuprvResp" BU_SG_REL_ CGM_HS SG_ 453 DrvIntndAxlTrqMin 1;
BA_REL_ "GenSigTimeoutMsg" BU_SG_REL_ CGM_HS SG_ 453 DrvIntndAxlTrqMin 453;
BA_REL_ "GenSigTimeoutTime" BU_SG_REL_ CGM_HS SG_ 453 DrvIntndAxlTrqMin 250;
BA_REL_ "GenSigSuprvResp" BU_SG_REL_ FCM_HS SG_ 453 DrvIntndAxlTrqMin 1;
BA_REL_ "GenSigTimeoutMsg" BU_SG_REL_ FCM_HS SG_ 453 DrvIntndAxlTrqMin 453;
BA_REL_ "GenSigTimeoutTime" BU_SG_REL_ FCM_HS SG_ 453 DrvIntndAxlTrqMin 250;
BA_REL_ "GenSigSuprvResp" BU_SG_REL_ HCP_B_HS SG_ 453 DrvIntndAxlTrqMin 1;
BA_REL_ "GenSigTimeoutMsg" BU_SG_REL_ HCP_B_HS SG_ 453 DrvIntndAxlTrqMin 453;
BA_REL_ "GenSigTimeoutTime" BU_SG_REL_ HCP_B_HS SG_ 453 DrvIntndAxlTrqMin 250;
BA_REL_ "GenSigSuprvResp" BU_SG_REL_ EOCM_F_HS SG_ 453 DrvIntndAxlTrqMin 1;
BA_REL_ "GenSigTimeoutTime" BU_SG_REL_ EOCM_F_HS SG_ 453 DrvIntndAxlTrqMin 120;
BA_REL_ "GenSigSuprvResp" BU_SG_REL_ ACC_HS SG_ 453 DrvIntndAxlTrqMin 1;
BA_REL_ "GenSigTimeoutMsg" BU_SG_REL_ ACC_HS SG_ 453 DrvIntndAxlTrqMin 453;
BA_REL_ "GenSigTimeoutTime" BU_SG_REL_ ACC_HS SG_ 453 DrvIntndAxlTrqMin 125;
BA_REL_ "GenSigSuprvResp" BU_SG_REL_ CGM_HS SG_ 453 DrvIntndAxlTrqMax 1;
BA_REL_ "GenSigTimeoutMsg" BU_SG_REL_ CGM_HS SG_ 453 DrvIntndAxlTrqMax 453;
BA_REL_ "GenSigTimeoutTime" BU_SG_REL_ CGM_HS SG_ 453 DrvIntndAxlTrqMax 250;
BA_REL_ "GenSigSuprvResp" BU_SG_REL_ FCM_HS SG_ 453 DrvIntndAxlTrqMax 1;
BA_REL_ "GenSigTimeoutMsg" BU_SG_REL_ FCM_HS SG_ 453 DrvIntndAxlTrqMax 453;
BA_REL_ "GenSigTimeoutTime" BU_SG_REL_ FCM_HS SG_ 453 DrvIntndAxlTrqMax 250;
BA_REL_ "GenSigSuprvResp" BU_SG_REL_ EOCM_F_HS SG_ 453 DrvIntndAxlTrqMax 1;
BA_REL_ "GenSigTimeoutTime" BU_SG_REL_ EOCM_F_HS SG_ 453 DrvIntndAxlTrqMax 120;
BA_REL_ "GenSigSuprvResp" BU_SG_REL_ ACC_HS SG_ 453 DrvIntndAxlTrqMax 1;
BA_REL_ "GenSigTimeoutMsg" BU_SG_REL_ ACC_HS SG_ 453 DrvIntndAxlTrqMax 453;
BA_REL_ "GenSigTimeoutTime" BU_SG_REL_ ACC_HS SG_ 453 DrvIntndAxlTrqMax 125;
BA_REL_ "GenSigSuprvResp" BU_SG_REL_ CGM_HS SG_ 453 DrvIntndAxlTrq 1;
BA_REL_ "GenSigTimeoutMsg" BU_SG_REL_ CGM_HS SG_ 453 DrvIntndAxlTrq 453;
BA_REL_ "GenSigTimeoutTime" BU_SG_REL_ CGM_HS SG_ 453 DrvIntndAxlTrq 250;
BA_REL_ "GenSigSuprvResp" BU_SG_REL_ FCM_HS SG_ 453 DrvIntndAxlTrq 1;
BA_REL_ "GenSigTimeoutMsg" BU_SG_REL_ FCM_HS SG_ 453 DrvIntndAxlTrq 453;
BA_REL_ "GenSigTimeoutTime" BU_SG_REL_ FCM_HS SG_ 453 DrvIntndAxlTrq 250;
BA_REL_ "GenSigSuprvResp" BU_SG_REL_ BSM_HS SG_ 453 DrvIntndAxlTrq 1;
BA_REL_ "GenSigTimeoutMsg" BU_SG_REL_ BSM_HS SG_ 453 DrvIntndAxlTrq 453;
BA_REL_ "GenSigTimeoutTime" BU_SG_REL_ BSM_HS SG_ 453 DrvIntndAxlTrq 250;
BA_REL_ "GenSigSuprvResp" BU_SG_REL_ VICM_HS SG_ 453 DrvIntndAxlTrq 1;
BA_REL_ "GenSigTimeoutMsg" BU_SG_REL_ VICM_HS SG_ 453 DrvIntndAxlTrq 453;
BA_REL_ "GenSigTimeoutTime" BU_SG_REL_ VICM_HS SG_ 453 DrvIntndAxlTrq 250;
BA_REL_ "GenSigSuprvResp" BU_SG_REL_ EOCM_F_HS SG_ 453 DrvIntndAxlTrq 1;
BA_REL_ "GenSigTimeoutTime" BU_SG_REL_ EOCM_F_HS SG_ 453 DrvIntndAxlTrq 120;
BA_REL_ "GenSigVBitResp" BU_SG_REL_ ACC_HS SG_ 453 DrvIntndAxlTrq 1;
BA_REL_ "GenSigRxStartValue" BU_SG_REL_ ACC_HS SG_ 453 DrvIntndAxlTrq "0";
BA_REL_ "GenSigSuprvResp" BU_SG_REL_ ACC_HS SG_ 453 DrvIntndAxlTrq 1;
BA_REL_ "GenSigTimeoutMsg" BU_SG_REL_ ACC_HS SG_ 453 DrvIntndAxlTrq 453;
BA_REL_ "GenSigTimeoutTime" BU_SG_REL_ ACC_HS SG_ 453 DrvIntndAxlTrq 125;
BA_REL_ "GenSigSuprvResp" BU_SG_REL_ FCM_HS SG_ 452 AutBrkAccActPsStRC 1;
BA_REL_ "GenSigTimeoutMsg" BU_SG_REL_ FCM_HS SG_ 452 AutBrkAccActPsStRC 452;
BA_REL_ "GenSigTimeoutTime" BU_SG_REL_ FCM_HS SG_ 452 AutBrkAccActPsStRC 250;
BA_REL_ "GenSigSuprvResp" BU_SG_REL_ EPB_HS SG_ 452 AutBrkAccActPsStRC 1;
BA_REL_ "GenSigTimeoutMsg" BU_SG_REL_ EPB_HS SG_ 452 AutBrkAccActPsStRC 452;
BA_REL_ "GenSigTimeoutTime" BU_SG_REL_ EPB_HS SG_ 452 AutBrkAccActPsStRC 250;
BA_REL_ "GenSigTimeoutMsg" BU_SG_REL_ EOCM_F_HS SG_ 452 AutBrkAccActPsStRC 452;
BA_REL_ "GenSigTimeoutMsg" BU_SG_REL_ ACC_HS SG_ 452 AutBrkAccActPsStRC 452;
BA_REL_ "GenSigSuprvResp" BU_SG_REL_ EBCM_OBD_HS SG_ 452 AutBrkAccActPsStRC 1;
BA_REL_ "GenSigTimeoutMsg" BU_SG_REL_ EBCM_OBD_HS SG_ 452 AutBrkAccActPsStRC 452;
BA_REL_ "GenSigTimeoutTime" BU_SG_REL_ EBCM_OBD_HS SG_ 452 AutBrkAccActPsStRC 250;
BA_REL_ "GenSigSuprvResp" BU_SG_REL_ EBCM_OBD_HS SG_ 452 AutBrkAccActPsStRC 1;
BA_REL_ "GenSigTimeoutMsg" BU_SG_REL_ EBCM_OBD_HS SG_ 452 AutBrkAccActPsStRC 452;
BA_REL_ "GenSigTimeoutTime" BU_SG_REL_ EBCM_OBD_HS SG_ 452 AutBrkAccActPsStRC 250;
BA_REL_ "GenSigSuprvResp" BU_SG_REL_ EBCM_OBD_HS SG_ 452 AutBrkAccActPsStRC 1;
BA_REL_ "GenSigTimeoutMsg" BU_SG_REL_ EBCM_OBD_HS SG_ 452 AutBrkAccActPsStRC 452;
BA_REL_ "GenSigTimeoutTime" BU_SG_REL_ EBCM_OBD_HS SG_ 452 AutBrkAccActPsStRC 250;
BA_REL_ "GenSigSuprvResp" BU_SG_REL_ EBCM_OBD_HS SG_ 452 AutBrkAccActPsStRC 1;
BA_REL_ "GenSigTimeoutMsg" BU_SG_REL_ EBCM_OBD_HS SG_ 452 AutBrkAccActPsStRC 452;
BA_REL_ "GenSigTimeoutTime" BU_SG_REL_ EBCM_OBD_HS SG_ 452 AutBrkAccActPsStRC 250;
BA_REL_ "GenSigSuprvResp" BU_SG_REL_ EBCM_OBD_HS SG_ 452 AutBrkAccActPsStRC 1;
BA_REL_ "GenSigTimeoutMsg" BU_SG_REL_ EBCM_OBD_HS SG_ 452 AutBrkAccActPsStRC 452;
BA_REL_ "GenSigTimeoutTime" BU_SG_REL_ EBCM_OBD_HS SG_ 452 AutBrkAccActPsStRC 250;
BA_REL_ "GenSigSuprvResp" BU_SG_REL_ EBCM_OBD_HS SG_ 452 AutBrkAccActPsStRC 1;
BA_REL_ "GenSigTimeoutMsg" BU_SG_REL_ EBCM_OBD_HS SG_ 452 AutBrkAccActPsStRC 452;
BA_REL_ "GenSigTimeoutTime" BU_SG_REL_ EBCM_OBD_HS SG_ 452 AutBrkAccActPsStRC 250;
BA_REL_ "GenSigSuprvResp" BU_SG_REL_ EBCM_HS SG_ 452 AutBrkAccActPsStRC 1;
BA_REL_ "GenSigTimeoutMsg" BU_SG_REL_ EBCM_HS SG_ 452 AutBrkAccActPsStRC 452;
BA_REL_ "GenSigTimeoutTime" BU_SG_REL_ EBCM_HS SG_ 452 AutBrkAccActPsStRC 250;
BA_REL_ "GenSigSuprvResp" BU_SG_REL_ EBCM_HS SG_ 452 AutBrkAccActPsStRC 1;
BA_REL_ "GenSigTimeoutMsg" BU_SG_REL_ EBCM_HS SG_ 452 AutBrkAccActPsStRC 452;
BA_REL_ "GenSigTimeoutTime" BU_SG_REL_ EBCM_HS SG_ 452 AutBrkAccActPsStRC 250;
BA_REL_ "GenSigSuprvResp" BU_SG_REL_ EBCM_HS SG_ 452 AutBrkAccActPsStRC 1;
BA_REL_ "GenSigTimeoutMsg" BU_SG_REL_ EBCM_HS SG_ 452 AutBrkAccActPsStRC 452;
BA_REL_ "GenSigTimeoutTime" BU_SG_REL_ EBCM_HS SG_ 452 AutBrkAccActPsStRC 250;
BA_REL_ "GenSigSuprvResp" BU_SG_REL_ EBCM_HS SG_ 452 AutBrkAccActPsStRC 1;
BA_REL_ "GenSigTimeoutMsg" BU_SG_REL_ EBCM_HS SG_ 452 AutBrkAccActPsStRC 452;
BA_REL_ "GenSigTimeoutTime" BU_SG_REL_ EBCM_HS SG_ 452 AutBrkAccActPsStRC 250;
BA_REL_ "GenSigSuprvResp" BU_SG_REL_ EBCM_HS SG_ 452 AutBrkAccActPsStRC 1;
BA_REL_ "GenSigTimeoutMsg" BU_SG_REL_ EBCM_HS SG_ 452 AutBrkAccActPsStRC 452;
BA_REL_ "GenSigTimeoutTime" BU_SG_REL_ EBCM_HS SG_ 452 AutBrkAccActPsStRC 250;
BA_REL_ "GenSigSuprvResp" BU_SG_REL_ EBCM_HS SG_ 452 AutBrkAccActPsStRC 1;
BA_REL_ "GenSigTimeoutMsg" BU_SG_REL_ EBCM_HS SG_ 452 AutBrkAccActPsStRC 452;
BA_REL_ "GenSigTimeoutTime" BU_SG_REL_ EBCM_HS SG_ 452 AutBrkAccActPsStRC 250;
BA_REL_ "GenSigSuprvResp" BU_SG_REL_ FCM_HS SG_ 452 AutBrkAccActPsStPVal 1;
BA_REL_ "GenSigTimeoutMsg" BU_SG_REL_ FCM_HS SG_ 452 AutBrkAccActPsStPVal 452;
BA_REL_ "GenSigTimeoutTime" BU_SG_REL_ FCM_HS SG_ 452 AutBrkAccActPsStPVal 250;
BA_REL_ "GenSigSuprvResp" BU_SG_REL_ EPB_HS SG_ 452 AutBrkAccActPsStPVal 1;
BA_REL_ "GenSigTimeoutMsg" BU_SG_REL_ EPB_HS SG_ 452 AutBrkAccActPsStPVal 452;
BA_REL_ "GenSigTimeoutTime" BU_SG_REL_ EPB_HS SG_ 452 AutBrkAccActPsStPVal 250;
BA_REL_ "GenSigTimeoutMsg" BU_SG_REL_ EOCM_F_HS SG_ 452 AutBrkAccActPsStPVal 452;
BA_REL_ "GenSigTimeoutMsg" BU_SG_REL_ ACC_HS SG_ 452 AutBrkAccActPsStPVal 452;
BA_REL_ "GenSigSuprvResp" BU_SG_REL_ EBCM_OBD_HS SG_ 452 AutBrkAccActPsStPVal 1;
BA_REL_ "GenSigTimeoutMsg" BU_SG_REL_ EBCM_OBD_HS SG_ 452 AutBrkAccActPsStPVal 452;
BA_REL_ "GenSigTimeoutTime" BU_SG_REL_ EBCM_OBD_HS SG_ 452 AutBrkAccActPsStPVal 250;
BA_REL_ "GenSigSuprvResp" BU_SG_REL_ EBCM_OBD_HS SG_ 452 AutBrkAccActPsStPVal 1;
BA_REL_ "GenSigTimeoutMsg" BU_SG_REL_ EBCM_OBD_HS SG_ 452 AutBrkAccActPsStPVal 452;
BA_REL_ "GenSigTimeoutTime" BU_SG_REL_ EBCM_OBD_HS SG_ 452 AutBrkAccActPsStPVal 250;
BA_REL_ "GenSigSuprvResp" BU_SG_REL_ EBCM_OBD_HS SG_ 452 AutBrkAccActPsStPVal 1;
BA_REL_ "GenSigTimeoutMsg" BU_SG_REL_ EBCM_OBD_HS SG_ 452 AutBrkAccActPsStPVal 452;
BA_REL_ "GenSigTimeoutTime" BU_SG_REL_ EBCM_OBD_HS SG_ 452 AutBrkAccActPsStPVal 250;
BA_REL_ "GenSigSuprvResp" BU_SG_REL_ EBCM_OBD_HS SG_ 452 AutBrkAccActPsStPVal 1;
BA_REL_ "GenSigTimeoutMsg" BU_SG_REL_ EBCM_OBD_HS SG_ 452 AutBrkAccActPsStPVal 452;
BA_REL_ "GenSigTimeoutTime" BU_SG_REL_ EBCM_OBD_HS SG_ 452 AutBrkAccActPsStPVal 250;
BA_REL_ "GenSigSuprvResp" BU_SG_REL_ EBCM_OBD_HS SG_ 452 AutBrkAccActPsStPVal 1;
BA_REL_ "GenSigTimeoutMsg" BU_SG_REL_ EBCM_OBD_HS SG_ 452 AutBrkAccActPsStPVal 452;
BA_REL_ "GenSigTimeoutTime" BU_SG_REL_ EBCM_OBD_HS SG_ 452 AutBrkAccActPsStPVal 250;
BA_REL_ "GenSigSuprvResp" BU_SG_REL_ EBCM_OBD_HS SG_ 452 AutBrkAccActPsStPVal 1;
BA_REL_ "GenSigTimeoutMsg" BU_SG_REL_ EBCM_OBD_HS SG_ 452 AutBrkAccActPsStPVal 452;
BA_REL_ "GenSigTimeoutTime" BU_SG_REL_ EBCM_OBD_HS SG_ 452 AutBrkAccActPsStPVal 250;
BA_REL_ "GenSigSuprvResp" BU_SG_REL_ EBCM_HS SG_ 452 AutBrkAccActPsStPVal 1;
BA_REL_ "GenSigTimeoutMsg" BU_SG_REL_ EBCM_HS SG_ 452 AutBrkAccActPsStPVal 452;
BA_REL_ "GenSigTimeoutTime" BU_SG_REL_ EBCM_HS SG_ 452 AutBrkAccActPsStPVal 250;
BA_REL_ "GenSigSuprvResp" BU_SG_REL_ EBCM_HS SG_ 452 AutBrkAccActPsStPVal 1;
BA_REL_ "GenSigTimeoutMsg" BU_SG_REL_ EBCM_HS SG_ 452 AutBrkAccActPsStPVal 452;
BA_REL_ "GenSigTimeoutTime" BU_SG_REL_ EBCM_HS SG_ 452 AutBrkAccActPsStPVal 250;
BA_REL_ "GenSigSuprvResp" BU_SG_REL_ EBCM_HS SG_ 452 AutBrkAccActPsStPVal 1;
BA_REL_ "GenSigTimeoutMsg" BU_SG_REL_ EBCM_HS SG_ 452 AutBrkAccActPsStPVal 452;
BA_REL_ "GenSigTimeoutTime" BU_SG_REL_ EBCM_HS SG_ 452 AutBrkAccActPsStPVal 250;
BA_REL_ "GenSigSuprvResp" BU_SG_REL_ EBCM_HS SG_ 452 AutBrkAccActPsStPVal 1;
BA_REL_ "GenSigTimeoutMsg" BU_SG_REL_ EBCM_HS SG_ 452 AutBrkAccActPsStPVal 452;
BA_REL_ "GenSigTimeoutTime" BU_SG_REL_ EBCM_HS SG_ 452 AutBrkAccActPsStPVal 250;
BA_REL_ "GenSigSuprvResp" BU_SG_REL_ EBCM_HS SG_ 452 AutBrkAccActPsStPVal 1;
BA_REL_ "GenSigTimeoutMsg" BU_SG_REL_ EBCM_HS SG_ 452 AutBrkAccActPsStPVal 452;
BA_REL_ "GenSigTimeoutTime" BU_SG_REL_ EBCM_HS SG_ 452 AutBrkAccActPsStPVal 250;
BA_REL_ "GenSigSuprvResp" BU_SG_REL_ EBCM_HS SG_ 452 AutBrkAccActPsStPVal 1;
BA_REL_ "GenSigTimeoutMsg" BU_SG_REL_ EBCM_HS SG_ 452 AutBrkAccActPsStPVal 452;
BA_REL_ "GenSigTimeoutTime" BU_SG_REL_ EBCM_HS SG_ 452 AutBrkAccActPsStPVal 250;
BA_REL_ "GenSigSuprvResp" BU_SG_REL_ FCM_HS SG_ 452 ABAAPS_AccPos 1;
BA_REL_ "GenSigTimeoutMsg" BU_SG_REL_ FCM_HS SG_ 452 ABAAPS_AccPos 452;
BA_REL_ "GenSigTimeoutTime" BU_SG_REL_ FCM_HS SG_ 452 ABAAPS_AccPos 250;
BA_REL_ "GenSigSuprvResp" BU_SG_REL_ EPB_HS SG_ 452 ABAAPS_AccPos 1;
BA_REL_ "GenSigTimeoutMsg" BU_SG_REL_ EPB_HS SG_ 452 ABAAPS_AccPos 452;
BA_REL_ "GenSigTimeoutTime" BU_SG_REL_ EPB_HS SG_ 452 ABAAPS_AccPos 250;
BA_REL_ "GenSigSuprvResp" BU_SG_REL_ EBCM_OBD_HS SG_ 452 ABAAPS_AccPos 1;
BA_REL_ "GenSigTimeoutMsg" BU_SG_REL_ EBCM_OBD_HS SG_ 452 ABAAPS_AccPos 452;
BA_REL_ "GenSigTimeoutTime" BU_SG_REL_ EBCM_OBD_HS SG_ 452 ABAAPS_AccPos 250;
BA_REL_ "GenSigSuprvResp" BU_SG_REL_ EBCM_OBD_HS SG_ 452 ABAAPS_AccPos 1;
BA_REL_ "GenSigTimeoutMsg" BU_SG_REL_ EBCM_OBD_HS SG_ 452 ABAAPS_AccPos 452;
BA_REL_ "GenSigTimeoutTime" BU_SG_REL_ EBCM_OBD_HS SG_ 452 ABAAPS_AccPos 250;
BA_REL_ "GenSigSuprvResp" BU_SG_REL_ EBCM_OBD_HS SG_ 452 ABAAPS_AccPos 1;
BA_REL_ "GenSigTimeoutMsg" BU_SG_REL_ EBCM_OBD_HS SG_ 452 ABAAPS_AccPos 452;
BA_REL_ "GenSigTimeoutTime" BU_SG_REL_ EBCM_OBD_HS SG_ 452 ABAAPS_AccPos 250;
BA_REL_ "GenSigSuprvResp" BU_SG_REL_ EBCM_OBD_HS SG_ 452 ABAAPS_AccPos 1;
BA_REL_ "GenSigTimeoutMsg" BU_SG_REL_ EBCM_OBD_HS SG_ 452 ABAAPS_AccPos 452;
BA_REL_ "GenSigTimeoutTime" BU_SG_REL_ EBCM_OBD_HS SG_ 452 ABAAPS_AccPos 250;
BA_REL_ "GenSigSuprvResp" BU_SG_REL_ EBCM_OBD_HS SG_ 452 ABAAPS_AccPos 1;
BA_REL_ "GenSigTimeoutMsg" BU_SG_REL_ EBCM_OBD_HS SG_ 452 ABAAPS_AccPos 452;
BA_REL_ "GenSigTimeoutTime" BU_SG_REL_ EBCM_OBD_HS SG_ 452 ABAAPS_AccPos 250;
BA_REL_ "GenSigSuprvResp" BU_SG_REL_ EBCM_OBD_HS SG_ 452 ABAAPS_AccPos 1;
BA_REL_ "GenSigTimeoutMsg" BU_SG_REL_ EBCM_OBD_HS SG_ 452 ABAAPS_AccPos 452;
BA_REL_ "GenSigTimeoutTime" BU_SG_REL_ EBCM_OBD_HS SG_ 452 ABAAPS_AccPos 250;
BA_REL_ "GenSigSuprvResp" BU_SG_REL_ EBCM_HS SG_ 452 ABAAPS_AccPos 1;
BA_REL_ "GenSigTimeoutMsg" BU_SG_REL_ EBCM_HS SG_ 452 ABAAPS_AccPos 452;
BA_REL_ "GenSigTimeoutTime" BU_SG_REL_ EBCM_HS SG_ 452 ABAAPS_AccPos 250;
BA_REL_ "GenSigSuprvResp" BU_SG_REL_ EBCM_HS SG_ 452 ABAAPS_AccPos 1;
BA_REL_ "GenSigTimeoutMsg" BU_SG_REL_ EBCM_HS SG_ 452 ABAAPS_AccPos 452;
BA_REL_ "GenSigTimeoutTime" BU_SG_REL_ EBCM_HS SG_ 452 ABAAPS_AccPos 250;
BA_REL_ "GenSigSuprvResp" BU_SG_REL_ EBCM_HS SG_ 452 ABAAPS_AccPos 1;
BA_REL_ "GenSigTimeoutMsg" BU_SG_REL_ EBCM_HS SG_ 452 ABAAPS_AccPos 452;
BA_REL_ "GenSigTimeoutTime" BU_SG_REL_ EBCM_HS SG_ 452 ABAAPS_AccPos 250;
BA_REL_ "GenSigSuprvResp" BU_SG_REL_ EBCM_HS SG_ 452 ABAAPS_AccPos 1;
BA_REL_ "GenSigTimeoutMsg" BU_SG_REL_ EBCM_HS SG_ 452 ABAAPS_AccPos 452;
BA_REL_ "GenSigTimeoutTime" BU_SG_REL_ EBCM_HS SG_ 452 ABAAPS_AccPos 250;
BA_REL_ "GenSigSuprvResp" BU_SG_REL_ EBCM_HS SG_ 452 ABAAPS_AccPos 1;
BA_REL_ "GenSigTimeoutMsg" BU_SG_REL_ EBCM_HS SG_ 452 ABAAPS_AccPos 452;
BA_REL_ "GenSigTimeoutTime" BU_SG_REL_ EBCM_HS SG_ 452 ABAAPS_AccPos 250;
BA_REL_ "GenSigSuprvResp" BU_SG_REL_ EBCM_HS SG_ 452 ABAAPS_AccPos 1;
BA_REL_ "GenSigTimeoutMsg" BU_SG_REL_ EBCM_HS SG_ 452 ABAAPS_AccPos 452;
BA_REL_ "GenSigTimeoutTime" BU_SG_REL_ EBCM_HS SG_ 452 ABAAPS_AccPos 250;
BA_REL_ "GenSigSuprvResp" BU_SG_REL_ ACC_HS SG_ 452 ABAAPS_AccPos 1;
BA_REL_ "GenSigTimeoutMsg" BU_SG_REL_ ACC_HS SG_ 452 ABAAPS_AccPos 452;
BA_REL_ "GenSigTimeoutTime" BU_SG_REL_ ACC_HS SG_ 452 ABAAPS_AccPos 250;
BA_REL_ "GenSigSuprvResp" BU_SG_REL_ FCM_HS SG_ 452 ABAAPS_AccPosV 1;
BA_REL_ "GenSigTimeoutMsg" BU_SG_REL_ FCM_HS SG_ 452 ABAAPS_AccPosV 452;
BA_REL_ "GenSigTimeoutTime" BU_SG_REL_ FCM_HS SG_ 452 ABAAPS_AccPosV 250;
BA_REL_ "GenSigSuprvResp" BU_SG_REL_ EPB_HS SG_ 452 ABAAPS_AccPosV 1;
BA_REL_ "GenSigTimeoutMsg" BU_SG_REL_ EPB_HS SG_ 452 ABAAPS_AccPosV 452;
BA_REL_ "GenSigTimeoutTime" BU_SG_REL_ EPB_HS SG_ 452 ABAAPS_AccPosV 250;
BA_REL_ "GenSigSuprvResp" BU_SG_REL_ EBCM_OBD_HS SG_ 452 ABAAPS_AccPosV 1;
BA_REL_ "GenSigTimeoutMsg" BU_SG_REL_ EBCM_OBD_HS SG_ 452 ABAAPS_AccPosV 452;
BA_REL_ "GenSigTimeoutTime" BU_SG_REL_ EBCM_OBD_HS SG_ 452 ABAAPS_AccPosV 250;
BA_REL_ "GenSigSuprvResp" BU_SG_REL_ EBCM_OBD_HS SG_ 452 ABAAPS_AccPosV 1;
BA_REL_ "GenSigTimeoutMsg" BU_SG_REL_ EBCM_OBD_HS SG_ 452 ABAAPS_AccPosV 452;
BA_REL_ "GenSigTimeoutTime" BU_SG_REL_ EBCM_OBD_HS SG_ 452 ABAAPS_AccPosV 250;
BA_REL_ "GenSigSuprvResp" BU_SG_REL_ EBCM_OBD_HS SG_ 452 ABAAPS_AccPosV 1;
BA_REL_ "GenSigTimeoutMsg" BU_SG_REL_ EBCM_OBD_HS SG_ 452 ABAAPS_AccPosV 452;
BA_REL_ "GenSigTimeoutTime" BU_SG_REL_ EBCM_OBD_HS SG_ 452 ABAAPS_AccPosV 250;
BA_REL_ "GenSigSuprvResp" BU_SG_REL_ EBCM_OBD_HS SG_ 452 ABAAPS_AccPosV 1;
BA_REL_ "GenSigTimeoutMsg" BU_SG_REL_ EBCM_OBD_HS SG_ 452 ABAAPS_AccPosV 452;
BA_REL_ "GenSigTimeoutTime" BU_SG_REL_ EBCM_OBD_HS SG_ 452 ABAAPS_AccPosV 250;
BA_REL_ "GenSigSuprvResp" BU_SG_REL_ EBCM_OBD_HS SG_ 452 ABAAPS_AccPosV 1;
BA_REL_ "GenSigTimeoutMsg" BU_SG_REL_ EBCM_OBD_HS SG_ 452 ABAAPS_AccPosV 452;
BA_REL_ "GenSigTimeoutTime" BU_SG_REL_ EBCM_OBD_HS SG_ 452 ABAAPS_AccPosV 250;
BA_REL_ "GenSigSuprvResp" BU_SG_REL_ EBCM_OBD_HS SG_ 452 ABAAPS_AccPosV 1;
BA_REL_ "GenSigTimeoutMsg" BU_SG_REL_ EBCM_OBD_HS SG_ 452 ABAAPS_AccPosV 452;
BA_REL_ "GenSigTimeoutTime" BU_SG_REL_ EBCM_OBD_HS SG_ 452 ABAAPS_AccPosV 250;
BA_REL_ "GenSigSuprvResp" BU_SG_REL_ EBCM_HS SG_ 452 ABAAPS_AccPosV 1;
BA_REL_ "GenSigTimeoutMsg" BU_SG_REL_ EBCM_HS SG_ 452 ABAAPS_AccPosV 452;
BA_REL_ "GenSigTimeoutTime" BU_SG_REL_ EBCM_HS SG_ 452 ABAAPS_AccPosV 250;
BA_REL_ "GenSigSuprvResp" BU_SG_REL_ EBCM_HS SG_ 452 ABAAPS_AccPosV 1;
BA_REL_ "GenSigTimeoutMsg" BU_SG_REL_ EBCM_HS SG_ 452 ABAAPS_AccPosV 452;
BA_REL_ "GenSigTimeoutTime" BU_SG_REL_ EBCM_HS SG_ 452 ABAAPS_AccPosV 250;
BA_REL_ "GenSigSuprvResp" BU_SG_REL_ EBCM_HS SG_ 452 ABAAPS_AccPosV 1;
BA_REL_ "GenSigTimeoutMsg" BU_SG_REL_ EBCM_HS SG_ 452 ABAAPS_AccPosV 452;
BA_REL_ "GenSigTimeoutTime" BU_SG_REL_ EBCM_HS SG_ 452 ABAAPS_AccPosV 250;
BA_REL_ "GenSigSuprvResp" BU_SG_REL_ EBCM_HS SG_ 452 ABAAPS_AccPosV 1;
BA_REL_ "GenSigTimeoutMsg" BU_SG_REL_ EBCM_HS SG_ 452 ABAAPS_AccPosV 452;
BA_REL_ "GenSigTimeoutTime" BU_SG_REL_ EBCM_HS SG_ 452 ABAAPS_AccPosV 250;
BA_REL_ "GenSigSuprvResp" BU_SG_REL_ EBCM_HS SG_ 452 ABAAPS_AccPosV 1;
BA_REL_ "GenSigTimeoutMsg" BU_SG_REL_ EBCM_HS SG_ 452 ABAAPS_AccPosV 452;
BA_REL_ "GenSigTimeoutTime" BU_SG_REL_ EBCM_HS SG_ 452 ABAAPS_AccPosV 250;
BA_REL_ "GenSigSuprvResp" BU_SG_REL_ EBCM_HS SG_ 452 ABAAPS_AccPosV 1;
BA_REL_ "GenSigTimeoutMsg" BU_SG_REL_ EBCM_HS SG_ 452 ABAAPS_AccPosV 452;
BA_REL_ "GenSigTimeoutTime" BU_SG_REL_ EBCM_HS SG_ 452 ABAAPS_AccPosV 250;
BA_REL_ "GenSigSuprvResp" BU_SG_REL_ ACC_HS SG_ 452 ABAAPS_AccPosV 1;
BA_REL_ "GenSigTimeoutMsg" BU_SG_REL_ ACC_HS SG_ 452 ABAAPS_AccPosV 452;
BA_REL_ "GenSigTimeoutTime" BU_SG_REL_ ACC_HS SG_ 452 ABAAPS_AccPosV 250;
BA_REL_ "GenSigSuprvResp" BU_SG_REL_ HCP_B_HS SG_ 452 ACCATCS_LmtgStat 1;
BA_REL_ "GenSigTimeoutMsg" BU_SG_REL_ HCP_B_HS SG_ 452 ACCATCS_LmtgStat 452;
BA_REL_ "GenSigTimeoutTime" BU_SG_REL_ HCP_B_HS SG_ 452 ACCATCS_LmtgStat 250;
BA_REL_ "GenSigRxStartValue" BU_SG_REL_ ACC_HS SG_ 452 ACCATCS_LmtgStat "0";
BA_REL_ "GenSigSuprvResp" BU_SG_REL_ ACC_HS SG_ 452 ACCATCS_LmtgStat 1;
BA_REL_ "GenSigTimeoutMsg" BU_SG_REL_ ACC_HS SG_ 452 ACCATCS_LmtgStat 452;
BA_REL_ "GenSigTimeoutTime" BU_SG_REL_ ACC_HS SG_ 452 ACCATCS_LmtgStat 125;
BA_REL_ "GenSigSuprvResp" BU_SG_REL_ HCP_B_HS SG_ 452 ACCATCS_RqStat 1;
BA_REL_ "GenSigTimeoutMsg" BU_SG_REL_ HCP_B_HS SG_ 452 ACCATCS_RqStat 452;
BA_REL_ "GenSigTimeoutTime" BU_SG_REL_ HCP_B_HS SG_ 452 ACCATCS_RqStat 250;
BA_REL_ "GenSigRxStartValue" BU_SG_REL_ ACC_HS SG_ 452 ACCATCS_RqStat "0";
BA_REL_ "GenSigSuprvResp" BU_SG_REL_ ACC_HS SG_ 452 ACCATCS_RqStat 1;
BA_REL_ "GenSigTimeoutMsg" BU_SG_REL_ ACC_HS SG_ 452 ACCATCS_RqStat 452;
BA_REL_ "GenSigTimeoutTime" BU_SG_REL_ ACC_HS SG_ 452 ACCATCS_RqStat 125;
BA_REL_ "GenSigSuprvResp" BU_SG_REL_ EOCM_F_HS SG_ 452 RdLdNomAxlTrq 1;
BA_REL_ "GenSigTimeoutTime" BU_SG_REL_ EOCM_F_HS SG_ 452 RdLdNomAxlTrq 120;
BA_REL_ "GenSigSuprvResp" BU_SG_REL_ ACC_HS SG_ 452 RdLdNomAxlTrq 1;
BA_REL_ "GenSigTimeoutMsg" BU_SG_REL_ ACC_HS SG_ 452 RdLdNomAxlTrq 452;
BA_REL_ "GenSigTimeoutTime" BU_SG_REL_ ACC_HS SG_ 452 RdLdNomAxlTrq 125;
BA_REL_ "GenSigSuprvResp" BU_SG_REL_ FCM_HS SG_ 452 AccPdlOvrrdAtvProtVal 1;
BA_REL_ "GenSigTimeoutMsg" BU_SG_REL_ FCM_HS SG_ 452 AccPdlOvrrdAtvProtVal 452;
BA_REL_ "GenSigTimeoutTime" BU_SG_REL_ FCM_HS SG_ 452 AccPdlOvrrdAtvProtVal 250;
BA_REL_ "GenSigSuprvResp" BU_SG_REL_ PTO_HS SG_ 452 AccPdlOvrrdAtvProtVal 1;
BA_REL_ "GenSigTimeoutMsg" BU_SG_REL_ PTO_HS SG_ 452 AccPdlOvrrdAtvProtVal 452;
BA_REL_ "GenSigTimeoutTime" BU_SG_REL_ PTO_HS SG_ 452 AccPdlOvrrdAtvProtVal 250;
BA_REL_ "GenSigSuprvResp" BU_SG_REL_ FCM_HS SG_ 452 AccPdlOvrrdAtvARC 1;
BA_REL_ "GenSigTimeoutMsg" BU_SG_REL_ FCM_HS SG_ 452 AccPdlOvrrdAtvARC 452;
BA_REL_ "GenSigTimeoutTime" BU_SG_REL_ FCM_HS SG_ 452 AccPdlOvrrdAtvARC 250;
BA_REL_ "GenSigSuprvResp" BU_SG_REL_ EOCM_F_HS SG_ 452 AccPdlOvrrdAtvARC 1;
BA_REL_ "GenSigTimeoutTime" BU_SG_REL_ EOCM_F_HS SG_ 452 AccPdlOvrrdAtvARC 120;
BA_REL_ "GenSigSuprvResp" BU_SG_REL_ PTO_HS SG_ 452 AccPdlOvrrdAtvARC 1;
BA_REL_ "GenSigTimeoutMsg" BU_SG_REL_ PTO_HS SG_ 452 AccPdlOvrrdAtvARC 452;
BA_REL_ "GenSigTimeoutTime" BU_SG_REL_ PTO_HS SG_ 452 AccPdlOvrrdAtvARC 250;
BA_REL_ "GenSigSuprvResp" BU_SG_REL_ FCM_HS SG_ 452 AccPdlOvrrdAtv 1;
BA_REL_ "GenSigTimeoutMsg" BU_SG_REL_ FCM_HS SG_ 452 AccPdlOvrrdAtv 452;
BA_REL_ "GenSigTimeoutTime" BU_SG_REL_ FCM_HS SG_ 452 AccPdlOvrrdAtv 250;
BA_REL_ "GenSigRxStartValue" BU_SG_REL_ ACC_HS SG_ 452 AccPdlOvrrdAtv "0";
BA_REL_ "GenSigSuprvResp" BU_SG_REL_ ACC_HS SG_ 452 AccPdlOvrrdAtv 1;
BA_REL_ "GenSigTimeoutMsg" BU_SG_REL_ ACC_HS SG_ 452 AccPdlOvrrdAtv 452;
BA_REL_ "GenSigTimeoutTime" BU_SG_REL_ ACC_HS SG_ 452 AccPdlOvrrdAtv 125;
BA_REL_ "GenSigSuprvResp" BU_SG_REL_ PTO_HS SG_ 452 AccPdlOvrrdAtv 1;
BA_REL_ "GenSigTimeoutMsg" BU_SG_REL_ PTO_HS SG_ 452 AccPdlOvrrdAtv 452;
BA_REL_ "GenSigTimeoutTime" BU_SG_REL_ PTO_HS SG_ 452 AccPdlOvrrdAtv 250;
BA_REL_ "GenSigSuprvResp" BU_SG_REL_ FCM_HS SG_ 452 CPSATCS_ReqStatus 1;
BA_REL_ "GenSigTimeoutMsg" BU_SG_REL_ FCM_HS SG_ 452 CPSATCS_ReqStatus 452;
BA_REL_ "GenSigTimeoutTime" BU_SG_REL_ FCM_HS SG_ 452 CPSATCS_ReqStatus 250;
BA_REL_ "GenSigSuprvResp" BU_SG_REL_ EOCM_F_HS SG_ 452 CPSATCS_ReqStatus 1;
BA_REL_ "GenSigTimeoutTime" BU_SG_REL_ EOCM_F_HS SG_ 452 CPSATCS_ReqStatus 120;
BA_REL_ "GenSigSuprvResp" BU_SG_REL_ FCM_HS SG_ 452 CPSATCS_LmtngStatus 1;
BA_REL_ "GenSigTimeoutMsg" BU_SG_REL_ FCM_HS SG_ 452 CPSATCS_LmtngStatus 452;
BA_REL_ "GenSigTimeoutTime" BU_SG_REL_ FCM_HS SG_ 452 CPSATCS_LmtngStatus 250;
BA_REL_ "GenSigSuprvResp" BU_SG_REL_ EOCM_F_HS SG_ 452 CPSATCS_LmtngStatus 1;
BA_REL_ "GenSigTimeoutTime" BU_SG_REL_ EOCM_F_HS SG_ 452 CPSATCS_LmtngStatus 120;
BA_REL_ "GenSigSuprvResp" BU_SG_REL_ EOCM_F_HS SG_ 452 RVBATCS_ReqStat 1;
BA_REL_ "GenSigTimeoutMsg" BU_SG_REL_ EOCM_F_HS SG_ 452 RVBATCS_ReqStat 452;
BA_REL_ "GenSigTimeoutTime" BU_SG_REL_ EOCM_F_HS SG_ 452 RVBATCS_ReqStat 120;
BA_REL_ "GenSigSuprvResp" BU_SG_REL_ EOCM_F_HS SG_ 452 RVBATCS_LmtngStat 1;
BA_REL_ "GenSigTimeoutMsg" BU_SG_REL_ EOCM_F_HS SG_ 452 RVBATCS_LmtngStat 452;
BA_REL_ "GenSigTimeoutTime" BU_SG_REL_ EOCM_F_HS SG_ 452 RVBATCS_LmtngStat 120;
VAL_ 1005 EnhSvVehTopSpdLmR 2 "Inactive" 1 "Active" 0 "No Action" ;
VAL_ 688 StrtrGenSpdV 1 "Invalid" 0 "Valid" ;
VAL_ 993 CstmrUsblSOCV 1 "Invalid" 0 "Valid" ;
VAL_ 993 JmpStrtStat 0 "Inactive" 1 "In Progress" 2 "Complete" 3 "Power Mode" 4 "Disabled" ;
VAL_ 993 HybVehHiVltSysDisbld 1 "true" 0 "false" ;
VAL_ 993 SvcHybridSysIO 1 "true" 0 "false" ;
VAL_ 993 HybMdDisp 15 "Engine Charging Battery While Idle" 14 "Engine Charging Battery Moving" 13 "Engine Power Load Sharing" 12 "Battery Power Load Sharing" 11 "Undetermined" 10 "Charging With Engine On" 9 "Charging With Engine Off" 8 "Hybrid Power 4WD" 7 "Hybrid Power 2WD" 6 "Engine Power 4WD" 5 "Engine Power 2WD" 4 "Battery Power 4WD" 3 "Battery Power 2WD" 2 "Auto Stop" 1 "Engine Idle" 0 "Default / Accessory" ;
VAL_ 490 SrvcFlSysPrkInOpnArIO 1 "true" 0 "false" ;
VAL_ 490 FuelSysNEmsRltMalfAct 1 "true" 0 "false" ;
VAL_ 490 InActFuelMdFuelLvlIO 1 "true" 0 "false" ;
VAL_ 490 FlLvlTank2PctV 1 "Invalid" 0 "Valid" ;
VAL_ 490 AltFuelPHeatAct 1 "true" 0 "false" ;
VAL_ 490 AltFuelMdReqDndIO 1 "true" 0 "false" ;
VAL_ 490 AltFuelLvlLo 1 "true" 0 "false" ;
VAL_ 490 AltFuelAccWrnngAct 1 "true" 0 "false" ;
VAL_ 490 FuelMdStat 3 "Alternative Fuel Cut-off Active" 2 "Liquified Petroleum Gas Mode" 1 "Natural Gas Mode" 0 "Gasoline Mode" ;
VAL_ 431 TrnsInpCltchStatV 1 "Invalid" 0 "Valid" ;
VAL_ 431 TransCrnkPermsnStatV 1 "Invalid" 0 "Valid" ;
VAL_ 431 TDslPrtFltrIdlRgtnMdAtv 1 "true" 0 "false" ;
VAL_ 431 DrvlneTrqStabStat 3 "Level 3" 0 "Normal Stability" 1 "Level 1" 2 "Level 2" ;
VAL_ 431 TrnsTrqCnvCltCmdMdF 1 "true" 0 "false" ;
VAL_ 431 AutoTransGrSftDirectFl 1 "true" 0 "false" ;
VAL_ 431 AutoTransGrSftDirect 2 "Downshift in Progress" 1 "Upshift in Progress" 0 "No Shift in Progress" ;
VAL_ 431 TrnsTrqCnvCltCmndMd 7 "Not Supported" 3 "Locked" 2 "Controlled Slip" 1 "Transitioning" 0 "Unlocked" ;
VAL_ 431 TrnsStWntrMdOvrd 2 "Override To Winter" 1 "Override To Not Winter" 0 "No Override" ;
VAL_ 431 TrnsStTwHaulMdOvrd 2 "Override To Tow Haul" 1 "Override To Not Tow Haul" 0 "No Override" ;
VAL_ 431 TrnsStSprtMdOvrd 2 "Override To Sport" 1 "Override To Not Sport" 0 "No Override" ;
VAL_ 431 TrnsStEconMdOvrd 2 "Override To Economy" 1 "Override To Not Economy" 0 "No Override" ;
VAL_ 431 TrnsInpCltchStat 0 "Disengaged" 1 "Engaging" 2 "Engaged" 3 "Disengaging" 4 "Controlled Slip" 5 "Reserved" 6 "Reserved" 7 "Not Supported" ;
VAL_ 431 TrnsAntcptdCrpTrqRRnV 1 "Invalid" 0 "Valid" ;
VAL_ 431 TrnCltAdpAtv 1 "true" 0 "false" ;
VAL_ 431 TransCrnkPermsnStat 0 "Crank Not Permitted" 1 "Crank Permitted" ;
VAL_ 431 WrmUpShftPtrn 0 "Inactive" 1 "Active" ;
VAL_ 715 ACCATC_SplREngInpR 1 "true" 0 "false" ;
VAL_ 715 ACCATC_DrvAstdGoSt 2 "Apply Acc Pedal or Resume Sw To Go" 1 "Apply Accel Pedal to Go" 0 "Not Stopped" ;
VAL_ 715 ACCATC_ACCTyp 2 "Full Speed Range ACC with Booster" 1 "Full Speed Range ACC" 0 "Adaptive Cruise Control" ;
VAL_ 715 ACCATC_ACCAct 1 "true" 0 "false" ;
VAL_ 453 DrvIntndAxlTrqV 1 "Invalid" 0 "Valid" ;
VAL_ 453 DrvIntndAxlTrqMinV 1 "Invalid" 0 "Valid" ;
VAL_ 453 DrvIntndAxlTrqMaxV 1 "Invalid" 0 "Valid" ;
VAL_ 452 FSpRgACCSwADd 1 "true" 0 "false" ;
VAL_ 452 ABAAPS_AccPosV 1 "Invalid" 0 "Valid" ;
VAL_ 452 ACCATCS_LmtgStat 3 "Request Rate Limited" 2 "Request Value Limited Maximum" 1 "Request Value Limited Minimum" 0 "Request Not Limited" ;
VAL_ 452 ACCATCS_RqStat 4 "Request Suspended Till Driver Input" 3 "Request Denied" 2 "Lost Arbitration" 1 "Request Honored" 0 "No Request" ;
VAL_ 452 AccPdlOvrrdAtv 1 "true" 0 "false" ;
VAL_ 452 CPSATCS_ReqStatus 0 "No Request" 1 "Request Honored" 2 "Lost Arbitration" 3 "Serial Data Failure Temporary" 4 "Serial Data Failure Permanent" 5 "Control System Failure Temporary" 6 "Control System Failure Permanent" ;
VAL_ 452 CPSATCS_LmtngStatus 0 "Request Not Limited" 1 "Request Value Limited to Minimum" 2 "Request Value Limited to Maximum" 3 "Request Rate Limited" ;
VAL_ 452 RVBATCS_ReqStat 0 "No Request" 1 "Request Honored" 2 "Lost Arbitration" 3 "Serial Data Failure Temporary" 4 "Serial Data Failure Permanent" 5 "Control System Failure Temporary" 6 "Control System Failure Permanent" ;
VAL_ 452 RVBATCS_LmtngStat 0 "Request Not Limited" 1 "Request Value Limited to Minimum" 2 "Request Value Limited to Maximum" 3 "Request Rate Limited" ;
VAL_ 1905 DTCI_DTCFaultType_771 3 "Type C" 2 "Type B" 1 "Type A" 0 "Not Supported" ;
VAL_ 1905 DTCI_CodeSupported_771 1 "true" 0 "false" ;
VAL_ 1905 DTCI_CurrentStatus_771 1 "true" 0 "false" ;
VAL_ 1905 DTCI_TstNPsdCdClrdSt_771 1 "true" 0 "false" ;
VAL_ 1905 DTCI_TstFldCdClrdStat_771 1 "true" 0 "false" ;
VAL_ 1905 DTCI_HistStat_771 1 "true" 0 "false" ;
VAL_ 1905 DTCI_TstNPsdPwrUpSt_771 1 "true" 0 "false" ;
VAL_ 1905 DTCI_TstFldPwrUpSt_771 1 "true" 0 "false" ;
VAL_ 1905 DTCI_WrnIndRqdSt_771 1 "true" 0 "false" ;
VAL_ 1905 DTCI_DTCTriggered_771 1 "true" 0 "false" ;
VAL_ 1905 DTCIUnused7_771 1 "true" 0 "false" ;
VAL_ 1905 DTCIUnused6_771 1 "true" 0 "false" ;
VAL_ 1905 DTCIUnused5_771 1 "true" 0 "false" ;
VAL_ 1905 DTCIUnused4_771 1 "true" 0 "false" ;
VAL_ 1905 DTCIUnused3_771 1 "true" 0 "false" ;
VAL_ 1905 DTCIUnused2_771 1 "true" 0 "false" ;
VAL_ 1905 DTCIUnused1_771 1 "true" 0 "false" ;
VAL_ 1935 DTCI_DTCTriggered_78F 1 "true" 0 "false" ;
VAL_ 1935 DTCIUnused1_78F 1 "true" 0 "false" ;
VAL_ 1935 DTCIUnused2_78F 1 "true" 0 "false" ;
VAL_ 1935 DTCIUnused3_78F 1 "true" 0 "false" ;
VAL_ 1935 DTCIUnused4_78F 1 "true" 0 "false" ;
VAL_ 1935 DTCIUnused5_78F 1 "true" 0 "false" ;
VAL_ 1935 DTCIUnused6_78F 1 "true" 0 "false" ;
VAL_ 1935 DTCIUnused7_78F 1 "true" 0 "false" ;
VAL_ 1935 DTCI_CodeSupported_78F 1 "true" 0 "false" ;
VAL_ 1935 DTCI_CurrentStatus_78F 1 "true" 0 "false" ;
VAL_ 1935 DTCI_DTCFaultType_78F 3 "Type C" 2 "Type B" 1 "Type A" 0 "Not Supported" ;
VAL_ 1935 DTCI_TstFldCdClrdStat_78F 1 "true" 0 "false" ;
VAL_ 1935 DTCI_TstNPsdCdClrdSt_78F 1 "true" 0 "false" ;
VAL_ 1935 DTCI_HistStat_78F 1 "true" 0 "false" ;
VAL_ 1935 DTCI_TstNPsdPwrUpSt_78F 1 "true" 0 "false" ;
VAL_ 1935 DTCI_TstFldPwrUpSt_78F 1 "true" 0 "false" ;
VAL_ 1935 DTCI_WrnIndRqdSt_78F 1 "true" 0 "false" ;
VAL_ 1934 DTCI_CodeSupported_78E 1 "true" 0 "false" ;
VAL_ 1934 DTCI_CurrentStatus_78E 1 "true" 0 "false" ;
VAL_ 1934 DTCI_DTCFaultType_78E 3 "Type C" 2 "Type B" 1 "Type A" 0 "Not Supported" ;
VAL_ 1934 DTCI_DTCTriggered_78E 1 "true" 0 "false" ;
VAL_ 1934 DTCI_HistStat_78E 1 "true" 0 "false" ;
VAL_ 1934 DTCI_TstFldCdClrdStat_78E 1 "true" 0 "false" ;
VAL_ 1934 DTCI_TstFldPwrUpSt_78E 1 "true" 0 "false" ;
VAL_ 1934 DTCI_TstNPsdCdClrdSt_78E 1 "true" 0 "false" ;
VAL_ 1934 DTCI_TstNPsdPwrUpSt_78E 1 "true" 0 "false" ;
VAL_ 1934 DTCIUnused1_78E 1 "true" 0 "false" ;
VAL_ 1934 DTCIUnused2_78E 1 "true" 0 "false" ;
VAL_ 1934 DTCIUnused3_78E 1 "true" 0 "false" ;
VAL_ 1934 DTCIUnused4_78E 1 "true" 0 "false" ;
VAL_ 1934 DTCIUnused5_78E 1 "true" 0 "false" ;
VAL_ 1934 DTCIUnused6_78E 1 "true" 0 "false" ;
VAL_ 1934 DTCIUnused7_78E 1 "true" 0 "false" ;
VAL_ 1934 DTCI_WrnIndRqdSt_78E 1 "true" 0 "false" ;
VAL_ 1933 DTCI_CodeSupported_78D 1 "true" 0 "false" ;
VAL_ 1933 DTCI_CurrentStatus_78D 1 "true" 0 "false" ;
VAL_ 1933 DTCI_DTCFaultType_78D 3 "Type C" 2 "Type B" 1 "Type A" 0 "Not Supported" ;
VAL_ 1933 DTCI_DTCTriggered_78D 1 "true" 0 "false" ;
VAL_ 1933 DTCI_HistStat_78D 1 "true" 0 "false" ;
VAL_ 1933 DTCI_TstFldCdClrdStat_78D 1 "true" 0 "false" ;
VAL_ 1933 DTCI_TstFldPwrUpSt_78D 1 "true" 0 "false" ;
VAL_ 1933 DTCI_TstNPsdCdClrdSt_78D 1 "true" 0 "false" ;
VAL_ 1933 DTCI_TstNPsdPwrUpSt_78D 1 "true" 0 "false" ;
VAL_ 1933 DTCIUnused1_78D 1 "true" 0 "false" ;
VAL_ 1933 DTCIUnused2_78D 1 "true" 0 "false" ;
VAL_ 1933 DTCIUnused3_78D 1 "true" 0 "false" ;
VAL_ 1933 DTCIUnused4_78D 1 "true" 0 "false" ;
VAL_ 1933 DTCIUnused5_78D 1 "true" 0 "false" ;
VAL_ 1933 DTCIUnused6_78D 1 "true" 0 "false" ;
VAL_ 1933 DTCIUnused7_78D 1 "true" 0 "false" ;
VAL_ 1933 DTCI_WrnIndRqdSt_78D 1 "true" 0 "false" ;
VAL_ 1932 DTCI_CodeSupported_78C 1 "true" 0 "false" ;
VAL_ 1932 DTCI_CurrentStatus_78C 1 "true" 0 "false" ;
VAL_ 1932 DTCI_DTCFaultType_78C 3 "Type C" 2 "Type B" 1 "Type A" 0 "Not Supported" ;
VAL_ 1932 DTCI_DTCTriggered_78C 1 "true" 0 "false" ;
VAL_ 1932 DTCI_HistStat_78C 1 "true" 0 "false" ;
VAL_ 1932 DTCI_TstFldCdClrdStat_78C 1 "true" 0 "false" ;
VAL_ 1932 DTCI_TstFldPwrUpSt_78C 1 "true" 0 "false" ;
VAL_ 1932 DTCI_TstNPsdCdClrdSt_78C 1 "true" 0 "false" ;
VAL_ 1932 DTCI_TstNPsdPwrUpSt_78C 1 "true" 0 "false" ;
VAL_ 1932 DTCIUnused1_78C 1 "true" 0 "false" ;
VAL_ 1932 DTCIUnused2_78C 1 "true" 0 "false" ;
VAL_ 1932 DTCIUnused3_78C 1 "true" 0 "false" ;
VAL_ 1932 DTCIUnused4_78C 1 "true" 0 "false" ;
VAL_ 1932 DTCIUnused5_78C 1 "true" 0 "false" ;
VAL_ 1932 DTCIUnused6_78C 1 "true" 0 "false" ;
VAL_ 1932 DTCIUnused7_78C 1 "true" 0 "false" ;
VAL_ 1932 DTCI_WrnIndRqdSt_78C 1 "true" 0 "false" ;
VAL_ 1931 DTCI_CodeSupported_78B 1 "true" 0 "false" ;
VAL_ 1931 DTCI_CurrentStatus_78B 1 "true" 0 "false" ;
VAL_ 1931 DTCI_DTCFaultType_78B 3 "Type C" 2 "Type B" 1 "Type A" 0 "Not Supported" ;
VAL_ 1931 DTCI_DTCTriggered_78B 1 "true" 0 "false" ;
VAL_ 1931 DTCI_HistStat_78B 1 "true" 0 "false" ;
VAL_ 1931 DTCI_TstFldCdClrdStat_78B 1 "true" 0 "false" ;
VAL_ 1931 DTCI_TstFldPwrUpSt_78B 1 "true" 0 "false" ;
VAL_ 1931 DTCI_TstNPsdCdClrdSt_78B 1 "true" 0 "false" ;
VAL_ 1931 DTCI_TstNPsdPwrUpSt_78B 1 "true" 0 "false" ;
VAL_ 1931 DTCIUnused1_78B 1 "true" 0 "false" ;
VAL_ 1931 DTCIUnused2_78B 1 "true" 0 "false" ;
VAL_ 1931 DTCIUnused3_78B 1 "true" 0 "false" ;
VAL_ 1931 DTCIUnused4_78B 1 "true" 0 "false" ;
VAL_ 1931 DTCIUnused5_78B 1 "true" 0 "false" ;
VAL_ 1931 DTCIUnused6_78B 1 "true" 0 "false" ;
VAL_ 1931 DTCIUnused7_78B 1 "true" 0 "false" ;
VAL_ 1931 DTCI_WrnIndRqdSt_78B 1 "true" 0 "false" ;
VAL_ 1930 DTCI_CodeSupported_78A 1 "true" 0 "false" ;
VAL_ 1930 DTCI_CurrentStatus_78A 1 "true" 0 "false" ;
VAL_ 1930 DTCI_DTCFaultType_78A 3 "Type C" 2 "Type B" 1 "Type A" 0 "Not Supported" ;
VAL_ 1930 DTCI_DTCTriggered_78A 1 "true" 0 "false" ;
VAL_ 1930 DTCI_HistStat_78A 1 "true" 0 "false" ;
VAL_ 1930 DTCI_TstFldCdClrdStat_78A 1 "true" 0 "false" ;
VAL_ 1930 DTCI_TstFldPwrUpSt_78A 1 "true" 0 "false" ;
VAL_ 1930 DTCI_TstNPsdCdClrdSt_78A 1 "true" 0 "false" ;
VAL_ 1930 DTCI_TstNPsdPwrUpSt_78A 1 "true" 0 "false" ;
VAL_ 1930 DTCIUnused1_78A 1 "true" 0 "false" ;
VAL_ 1930 DTCIUnused2_78A 1 "true" 0 "false" ;
VAL_ 1930 DTCIUnused3_78A 1 "true" 0 "false" ;
VAL_ 1930 DTCIUnused4_78A 1 "true" 0 "false" ;
VAL_ 1930 DTCIUnused5_78A 1 "true" 0 "false" ;
VAL_ 1930 DTCIUnused6_78A 1 "true" 0 "false" ;
VAL_ 1930 DTCIUnused7_78A 1 "true" 0 "false" ;
VAL_ 1930 DTCI_WrnIndRqdSt_78A 1 "true" 0 "false" ;
VAL_ 1929 DTCI_CodeSupported_789 1 "true" 0 "false" ;
VAL_ 1929 DTCI_CurrentStatus_789 1 "true" 0 "false" ;
VAL_ 1929 DTCI_DTCFaultType_789 3 "Type C" 2 "Type B" 1 "Type A" 0 "Not Supported" ;
VAL_ 1929 DTCI_DTCTriggered_789 1 "true" 0 "false" ;
VAL_ 1929 DTCI_HistStat_789 1 "true" 0 "false" ;
VAL_ 1929 DTCI_TstFldCdClrdStat_789 1 "true" 0 "false" ;
VAL_ 1929 DTCI_TstFldPwrUpSt_789 1 "true" 0 "false" ;
VAL_ 1929 DTCI_TstNPsdCdClrdSt_789 1 "true" 0 "false" ;
VAL_ 1929 DTCI_TstNPsdPwrUpSt_789 1 "true" 0 "false" ;
VAL_ 1929 DTCIUnused1_789 1 "true" 0 "false" ;
VAL_ 1929 DTCIUnused2_789 1 "true" 0 "false" ;
VAL_ 1929 DTCIUnused3_789 1 "true" 0 "false" ;
VAL_ 1929 DTCIUnused4_789 1 "true" 0 "false" ;
VAL_ 1929 DTCIUnused5_789 1 "true" 0 "false" ;
VAL_ 1929 DTCIUnused6_789 1 "true" 0 "false" ;
VAL_ 1929 DTCIUnused7_789 1 "true" 0 "false" ;
VAL_ 1929 DTCI_WrnIndRqdSt_789 1 "true" 0 "false" ;
VAL_ 1928 DTCI_CodeSupported_788 1 "true" 0 "false" ;
VAL_ 1928 DTCI_CurrentStatus_788 1 "true" 0 "false" ;
VAL_ 1928 DTCI_DTCFaultType_788 3 "Type C" 2 "Type B" 1 "Type A" 0 "Not Supported" ;
VAL_ 1928 DTCI_DTCTriggered_788 1 "true" 0 "false" ;
VAL_ 1928 DTCI_HistStat_788 1 "true" 0 "false" ;
VAL_ 1928 DTCI_TstFldCdClrdStat_788 1 "true" 0 "false" ;
VAL_ 1928 DTCI_TstFldPwrUpSt_788 1 "true" 0 "false" ;
VAL_ 1928 DTCI_TstNPsdCdClrdSt_788 1 "true" 0 "false" ;
VAL_ 1928 DTCI_TstNPsdPwrUpSt_788 1 "true" 0 "false" ;
VAL_ 1928 DTCIUnused1_788 1 "true" 0 "false" ;
VAL_ 1928 DTCIUnused2_788 1 "true" 0 "false" ;
VAL_ 1928 DTCIUnused3_788 1 "true" 0 "false" ;
VAL_ 1928 DTCIUnused4_788 1 "true" 0 "false" ;
VAL_ 1928 DTCIUnused5_788 1 "true" 0 "false" ;
VAL_ 1928 DTCIUnused6_788 1 "true" 0 "false" ;
VAL_ 1928 DTCIUnused7_788 1 "true" 0 "false" ;
VAL_ 1928 DTCI_WrnIndRqdSt_788 1 "true" 0 "false" ;
VAL_ 1927 DTCI_CodeSupported_787 1 "true" 0 "false" ;
VAL_ 1927 DTCI_CurrentStatus_787 1 "true" 0 "false" ;
VAL_ 1927 DTCI_DTCFaultType_787 3 "Type C" 2 "Type B" 1 "Type A" 0 "Not Supported" ;
VAL_ 1927 DTCI_DTCTriggered_787 1 "true" 0 "false" ;
VAL_ 1927 DTCI_HistStat_787 1 "true" 0 "false" ;
VAL_ 1927 DTCI_TstFldCdClrdStat_787 1 "true" 0 "false" ;
VAL_ 1927 DTCI_TstFldPwrUpSt_787 1 "true" 0 "false" ;
VAL_ 1927 DTCI_TstNPsdCdClrdSt_787 1 "true" 0 "false" ;
VAL_ 1927 DTCI_TstNPsdPwrUpSt_787 1 "true" 0 "false" ;
VAL_ 1927 DTCIUnused1_787 1 "true" 0 "false" ;
VAL_ 1927 DTCIUnused2_787 1 "true" 0 "false" ;
VAL_ 1927 DTCIUnused3_787 1 "true" 0 "false" ;
VAL_ 1927 DTCIUnused4_787 1 "true" 0 "false" ;
VAL_ 1927 DTCIUnused5_787 1 "true" 0 "false" ;
VAL_ 1927 DTCIUnused6_787 1 "true" 0 "false" ;
VAL_ 1927 DTCIUnused7_787 1 "true" 0 "false" ;
VAL_ 1927 DTCI_WrnIndRqdSt_787 1 "true" 0 "false" ;
VAL_ 1926 DTCI_CodeSupported_786 1 "true" 0 "false" ;
VAL_ 1926 DTCI_CurrentStatus_786 1 "true" 0 "false" ;
VAL_ 1926 DTCI_DTCFaultType_786 3 "Type C" 2 "Type B" 1 "Type A" 0 "Not Supported" ;
VAL_ 1926 DTCI_DTCTriggered_786 1 "true" 0 "false" ;
VAL_ 1926 DTCI_HistStat_786 1 "true" 0 "false" ;
VAL_ 1926 DTCI_TstFldCdClrdStat_786 1 "true" 0 "false" ;
VAL_ 1926 DTCI_TstFldPwrUpSt_786 1 "true" 0 "false" ;
VAL_ 1926 DTCI_TstNPsdCdClrdSt_786 1 "true" 0 "false" ;
VAL_ 1926 DTCI_TstNPsdPwrUpSt_786 1 "true" 0 "false" ;
VAL_ 1926 DTCIUnused1_786 1 "true" 0 "false" ;
VAL_ 1926 DTCIUnused2_786 1 "true" 0 "false" ;
VAL_ 1926 DTCIUnused3_786 1 "true" 0 "false" ;
VAL_ 1926 DTCIUnused4_786 1 "true" 0 "false" ;
VAL_ 1926 DTCIUnused5_786 1 "true" 0 "false" ;
VAL_ 1926 DTCIUnused6_786 1 "true" 0 "false" ;
VAL_ 1926 DTCIUnused7_786 1 "true" 0 "false" ;
VAL_ 1926 DTCI_WrnIndRqdSt_786 1 "true" 0 "false" ;
VAL_ 1925 DTCI_CodeSupported_785 1 "true" 0 "false" ;
VAL_ 1925 DTCI_CurrentStatus_785 1 "true" 0 "false" ;
VAL_ 1925 DTCI_DTCFaultType_785 3 "Type C" 2 "Type B" 1 "Type A" 0 "Not Supported" ;
VAL_ 1925 DTCI_DTCTriggered_785 1 "true" 0 "false" ;
VAL_ 1925 DTCI_HistStat_785 1 "true" 0 "false" ;
VAL_ 1925 DTCI_TstFldCdClrdStat_785 1 "true" 0 "false" ;
VAL_ 1925 DTCI_TstFldPwrUpSt_785 1 "true" 0 "false" ;
VAL_ 1925 DTCI_TstNPsdCdClrdSt_785 1 "true" 0 "false" ;
VAL_ 1925 DTCI_TstNPsdPwrUpSt_785 1 "true" 0 "false" ;
VAL_ 1925 DTCIUnused1_785 1 "true" 0 "false" ;
VAL_ 1925 DTCIUnused2_785 1 "true" 0 "false" ;
VAL_ 1925 DTCIUnused3_785 1 "true" 0 "false" ;
VAL_ 1925 DTCIUnused4_785 1 "true" 0 "false" ;
VAL_ 1925 DTCIUnused5_785 1 "true" 0 "false" ;
VAL_ 1925 DTCIUnused6_785 1 "true" 0 "false" ;
VAL_ 1925 DTCIUnused7_785 1 "true" 0 "false" ;
VAL_ 1925 DTCI_WrnIndRqdSt_785 1 "true" 0 "false" ;
VAL_ 1924 DTCI_HistStat_784 1 "true" 0 "false" ;
VAL_ 1924 DTCI_TstFldCdClrdStat_784 1 "true" 0 "false" ;
VAL_ 1924 DTCI_TstFldPwrUpSt_784 1 "true" 0 "false" ;
VAL_ 1924 DTCI_TstNPsdCdClrdSt_784 1 "true" 0 "false" ;
VAL_ 1924 DTCI_TstNPsdPwrUpSt_784 1 "true" 0 "false" ;
VAL_ 1924 DTCIUnused1_784 1 "true" 0 "false" ;
VAL_ 1924 DTCIUnused2_784 1 "true" 0 "false" ;
VAL_ 1924 DTCIUnused3_784 1 "true" 0 "false" ;
VAL_ 1924 DTCIUnused4_784 1 "true" 0 "false" ;
VAL_ 1924 DTCIUnused5_784 1 "true" 0 "false" ;
VAL_ 1924 DTCIUnused6_784 1 "true" 0 "false" ;
VAL_ 1924 DTCIUnused7_784 1 "true" 0 "false" ;
VAL_ 1924 DTCI_WrnIndRqdSt_784 1 "true" 0 "false" ;
VAL_ 1924 DTCI_CodeSupported_784 1 "true" 0 "false" ;
VAL_ 1924 DTCI_CurrentStatus_784 1 "true" 0 "false" ;
VAL_ 1924 DTCI_DTCFaultType_784 3 "Type C" 2 "Type B" 1 "Type A" 0 "Not Supported" ;
VAL_ 1924 DTCI_DTCTriggered_784 1 "true" 0 "false" ;
VAL_ 1923 DTCI_WrnIndRqdSt_783 1 "true" 0 "false" ;
VAL_ 1923 DTCI_TstNPsdPwrUpSt_783 1 "true" 0 "false" ;
VAL_ 1923 DTCI_TstNPsdCdClrdSt_783 1 "true" 0 "false" ;
VAL_ 1923 DTCI_TstFldPwrUpSt_783 1 "true" 0 "false" ;
VAL_ 1923 DTCI_TstFldCdClrdStat_783 1 "true" 0 "false" ;
VAL_ 1923 DTCI_HistStat_783 1 "true" 0 "false" ;
VAL_ 1923 DTCI_DTCTriggered_783 1 "true" 0 "false" ;
VAL_ 1923 DTCI_DTCFaultType_783 3 "Type C" 2 "Type B" 1 "Type A" 0 "Not Supported" ;
VAL_ 1923 DTCI_CurrentStatus_783 1 "true" 0 "false" ;
VAL_ 1923 DTCI_CodeSupported_783 1 "true" 0 "false" ;
VAL_ 1923 DTCIUnused7_783 1 "true" 0 "false" ;
VAL_ 1923 DTCIUnused6_783 1 "true" 0 "false" ;
VAL_ 1923 DTCIUnused5_783 1 "true" 0 "false" ;
VAL_ 1923 DTCIUnused4_783 1 "true" 0 "false" ;
VAL_ 1923 DTCIUnused3_783 1 "true" 0 "false" ;
VAL_ 1923 DTCIUnused2_783 1 "true" 0 "false" ;
VAL_ 1923 DTCIUnused1_783 1 "true" 0 "false" ;
SIG_GROUP_ 715 ACCAxlTrqCmd 1 : ACCATC_SplREngInpR ACCATC_DrvAstdGoSt ACCATC_AxlTrqRq ACCATC_ACCTyp ACCATC_ACCAct;
SIG_GROUP_ 452 AutBrkAccActPsSt 1 : ABAAPS_AccPos ABAAPS_AccPosV;
SIG_GROUP_ 452 ACCAxlTrqCmdStat 1 : ACCATCS_LmtgStat ACCATCS_RqStat;
SIG_GROUP_ 452 ColPrSysAxlTrqCmdStat 1 : CPSATCS_ReqStatus CPSATCS_LmtngStatus;
SIG_GROUP_ 452 RrVrtBmpAxlTrqCmdStat 1 : RVBATCS_ReqStat RVBATCS_LmtngStat;
SIG_GROUP_ 1905 DTCInfo_771 1 : DTCI_DTCFaultType_771 DTCI_CodeSupported_771 DTCI_CurrentStatus_771 DTCI_TstNPsdCdClrdSt_771 DTCI_TstFldCdClrdStat_771 DTCI_HistStat_771 DTCI_TstNPsdPwrUpSt_771 DTCI_TstFldPwrUpSt_771 DTCI_WrnIndRqdSt_771 DTCI_DTCFailType_771 DTCI_DTCNumber_771 DTCI_DTCSource_771 DTCI_DTCTriggered_771 DTCIUnused7_771 DTCIUnused6_771 DTCIUnused5_771 DTCIUnused4_771 DTCIUnused3_771 DTCIUnused2_771 DTCIUnused1_771;
SIG_GROUP_ 1935 DTCInfo_78F 1 : DTCI_DTCSource_78F DTCI_DTCTriggered_78F DTCIUnused1_78F DTCIUnused2_78F DTCIUnused3_78F DTCIUnused4_78F DTCIUnused5_78F DTCIUnused6_78F DTCIUnused7_78F DTCI_CodeSupported_78F DTCI_CurrentStatus_78F DTCI_DTCFaultType_78F DTCI_TstFldCdClrdStat_78F DTCI_TstNPsdCdClrdSt_78F DTCI_HistStat_78F DTCI_TstNPsdPwrUpSt_78F DTCI_TstFldPwrUpSt_78F DTCI_WrnIndRqdSt_78F DTCI_DTCFailType_78F DTCI_DTCNumber_78F;
SIG_GROUP_ 1934 DTCInfo_78E 1 : DTCI_CodeSupported_78E DTCI_CurrentStatus_78E DTCI_DTCFailType_78E DTCI_DTCFaultType_78E DTCI_DTCNumber_78E DTCI_DTCSource_78E DTCI_DTCTriggered_78E DTCI_HistStat_78E DTCI_TstFldCdClrdStat_78E DTCI_TstFldPwrUpSt_78E DTCI_TstNPsdCdClrdSt_78E DTCI_TstNPsdPwrUpSt_78E DTCIUnused1_78E DTCIUnused2_78E DTCIUnused3_78E DTCIUnused4_78E DTCIUnused5_78E DTCIUnused6_78E DTCIUnused7_78E DTCI_WrnIndRqdSt_78E;
SIG_GROUP_ 1933 DTCInfo_78D 1 : DTCI_CodeSupported_78D DTCI_CurrentStatus_78D DTCI_DTCFailType_78D DTCI_DTCFaultType_78D DTCI_DTCNumber_78D DTCI_DTCSource_78D DTCI_DTCTriggered_78D DTCI_HistStat_78D DTCI_TstFldCdClrdStat_78D DTCI_TstFldPwrUpSt_78D DTCI_TstNPsdCdClrdSt_78D DTCI_TstNPsdPwrUpSt_78D DTCIUnused1_78D DTCIUnused2_78D DTCIUnused3_78D DTCIUnused4_78D DTCIUnused5_78D DTCIUnused6_78D DTCIUnused7_78D DTCI_WrnIndRqdSt_78D;
SIG_GROUP_ 1932 DTCInfo_78C 1 : DTCI_CodeSupported_78C DTCI_CurrentStatus_78C DTCI_DTCFailType_78C DTCI_DTCFaultType_78C DTCI_DTCNumber_78C DTCI_DTCSource_78C DTCI_DTCTriggered_78C DTCI_HistStat_78C DTCI_TstFldCdClrdStat_78C DTCI_TstFldPwrUpSt_78C DTCI_TstNPsdCdClrdSt_78C DTCI_TstNPsdPwrUpSt_78C DTCIUnused1_78C DTCIUnused2_78C DTCIUnused3_78C DTCIUnused4_78C DTCIUnused5_78C DTCIUnused6_78C DTCIUnused7_78C DTCI_WrnIndRqdSt_78C;
SIG_GROUP_ 1931 DTCInfo_78B 1 : DTCI_CodeSupported_78B DTCI_CurrentStatus_78B DTCI_DTCFailType_78B DTCI_DTCFaultType_78B DTCI_DTCNumber_78B DTCI_DTCSource_78B DTCI_DTCTriggered_78B DTCI_HistStat_78B DTCI_TstFldCdClrdStat_78B DTCI_TstFldPwrUpSt_78B DTCI_TstNPsdCdClrdSt_78B DTCI_TstNPsdPwrUpSt_78B DTCIUnused1_78B DTCIUnused2_78B DTCIUnused3_78B DTCIUnused4_78B DTCIUnused5_78B DTCIUnused6_78B DTCIUnused7_78B DTCI_WrnIndRqdSt_78B;
SIG_GROUP_ 1930 DTCInfo_78A 1 : DTCI_CodeSupported_78A DTCI_CurrentStatus_78A DTCI_DTCFailType_78A DTCI_DTCFaultType_78A DTCI_DTCNumber_78A DTCI_DTCSource_78A DTCI_DTCTriggered_78A DTCI_HistStat_78A DTCI_TstFldCdClrdStat_78A DTCI_TstFldPwrUpSt_78A DTCI_TstNPsdCdClrdSt_78A DTCI_TstNPsdPwrUpSt_78A DTCIUnused1_78A DTCIUnused2_78A DTCIUnused3_78A DTCIUnused4_78A DTCIUnused5_78A DTCIUnused6_78A DTCIUnused7_78A DTCI_WrnIndRqdSt_78A;
SIG_GROUP_ 1929 DTCInfo_789 1 : DTCI_CodeSupported_789 DTCI_CurrentStatus_789 DTCI_DTCFailType_789 DTCI_DTCFaultType_789 DTCI_DTCNumber_789 DTCI_DTCSource_789 DTCI_DTCTriggered_789 DTCI_HistStat_789 DTCI_TstFldCdClrdStat_789 DTCI_TstFldPwrUpSt_789 DTCI_TstNPsdCdClrdSt_789 DTCI_TstNPsdPwrUpSt_789 DTCIUnused1_789 DTCIUnused2_789 DTCIUnused3_789 DTCIUnused4_789 DTCIUnused5_789 DTCIUnused6_789 DTCIUnused7_789 DTCI_WrnIndRqdSt_789;
SIG_GROUP_ 1928 DTCInfo_788 1 : DTCI_CodeSupported_788 DTCI_CurrentStatus_788 DTCI_DTCFailType_788 DTCI_DTCFaultType_788 DTCI_DTCNumber_788 DTCI_DTCSource_788 DTCI_DTCTriggered_788 DTCI_HistStat_788 DTCI_TstFldCdClrdStat_788 DTCI_TstFldPwrUpSt_788 DTCI_TstNPsdCdClrdSt_788 DTCI_TstNPsdPwrUpSt_788 DTCIUnused1_788 DTCIUnused2_788 DTCIUnused3_788 DTCIUnused4_788 DTCIUnused5_788 DTCIUnused6_788 DTCIUnused7_788 DTCI_WrnIndRqdSt_788;
SIG_GROUP_ 1927 DTCInfo_787 1 : DTCI_CodeSupported_787 DTCI_CurrentStatus_787 DTCI_DTCFailType_787 DTCI_DTCFaultType_787 DTCI_DTCNumber_787 DTCI_DTCSource_787 DTCI_DTCTriggered_787 DTCI_HistStat_787 DTCI_TstFldCdClrdStat_787 DTCI_TstFldPwrUpSt_787 DTCI_TstNPsdCdClrdSt_787 DTCI_TstNPsdPwrUpSt_787 DTCIUnused1_787 DTCIUnused2_787 DTCIUnused3_787 DTCIUnused4_787 DTCIUnused5_787 DTCIUnused6_787 DTCIUnused7_787 DTCI_WrnIndRqdSt_787;
SIG_GROUP_ 1926 DTCInfo_786 1 : DTCI_CodeSupported_786 DTCI_CurrentStatus_786 DTCI_DTCFailType_786 DTCI_DTCFaultType_786 DTCI_DTCNumber_786 DTCI_DTCSource_786 DTCI_DTCTriggered_786 DTCI_HistStat_786 DTCI_TstFldCdClrdStat_786 DTCI_TstFldPwrUpSt_786 DTCI_TstNPsdCdClrdSt_786 DTCI_TstNPsdPwrUpSt_786 DTCIUnused1_786 DTCIUnused2_786 DTCIUnused3_786 DTCIUnused4_786 DTCIUnused5_786 DTCIUnused6_786 DTCIUnused7_786 DTCI_WrnIndRqdSt_786;
SIG_GROUP_ 1925 DTCInfo_785 1 : DTCI_CodeSupported_785 DTCI_CurrentStatus_785 DTCI_DTCFailType_785 DTCI_DTCFaultType_785 DTCI_DTCNumber_785 DTCI_DTCSource_785 DTCI_DTCTriggered_785 DTCI_HistStat_785 DTCI_TstFldCdClrdStat_785 DTCI_TstFldPwrUpSt_785 DTCI_TstNPsdCdClrdSt_785 DTCI_TstNPsdPwrUpSt_785 DTCIUnused1_785 DTCIUnused2_785 DTCIUnused3_785 DTCIUnused4_785 DTCIUnused5_785 DTCIUnused6_785 DTCIUnused7_785 DTCI_WrnIndRqdSt_785;
SIG_GROUP_ 1924 DTCInfo_784 1 : DTCI_HistStat_784 DTCI_TstFldCdClrdStat_784 DTCI_TstFldPwrUpSt_784 DTCI_TstNPsdCdClrdSt_784 DTCI_TstNPsdPwrUpSt_784 DTCIUnused1_784 DTCIUnused2_784 DTCIUnused3_784 DTCIUnused4_784 DTCIUnused5_784 DTCIUnused6_784 DTCIUnused7_784 DTCI_WrnIndRqdSt_784 DTCI_CodeSupported_784 DTCI_CurrentStatus_784 DTCI_DTCFailType_784 DTCI_DTCFaultType_784 DTCI_DTCNumber_784 DTCI_DTCSource_784 DTCI_DTCTriggered_784;
SIG_GROUP_ 1923 DTCInfo_783 1 : DTCI_WrnIndRqdSt_783 DTCI_TstNPsdPwrUpSt_783 DTCI_TstNPsdCdClrdSt_783 DTCI_TstFldPwrUpSt_783 DTCI_TstFldCdClrdStat_783 DTCI_HistStat_783 DTCI_DTCTriggered_783 DTCI_DTCSource_783 DTCI_DTCNumber_783 DTCI_DTCFaultType_783 DTCI_DTCFailType_783 DTCI_CurrentStatus_783 DTCI_CodeSupported_783 DTCIUnused7_783 DTCIUnused6_783 DTCIUnused5_783 DTCIUnused4_783 DTCIUnused3_783 DTCIUnused2_783 DTCIUnused1_783;
